VERSION "HNNBNNNYNNNNNNNNNNNNNNNNNNNNNNNNNNNNNNNNNN/4/%%%/4/'%**4NNN///"

NS_ :

BS_:

BU_: BAP_Tester BedienDisp_mi BedienDisp_vo_mi CDI ConMod_CD DashCAM Gateway_Max ICC_IO_Node LSH OCU RDK_RS3 Sound_MIB_ab_Gen3 STH ZR_MIB_EINSTIEG_ab_Gen3 ZR_MIB_OPTION_ab_Gen3 ZR_MIB_TOP_ab_Gen3

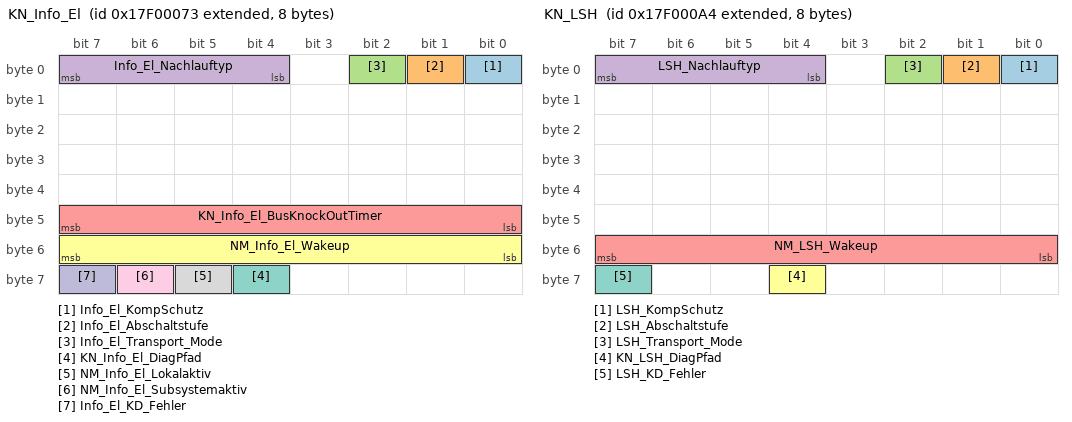
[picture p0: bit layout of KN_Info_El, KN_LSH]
BO_ 2549088371 KN_Info_El: 8 ICC_IO_Node
 SG_ Info_El_KompSchutz : 0|1@1+ (1.0,0.0) [0.0|1] ""  Vector__XXX
 SG_ Info_El_Abschaltstufe : 1|1@1+ (1.0,0.0) [0.0|1] ""  Vector__XXX
 SG_ Info_El_Transport_Mode : 2|1@1+ (1.0,0.0) [0.0|1] ""  Vector__XXX
 SG_ Info_El_Nachlauftyp : 4|4@1+ (1.0,0.0) [0.0|15] ""  Gateway_Max
 SG_ KN_Info_El_BusKnockOutTimer : 40|8@1+ (1,0) [0|254] "Unit_Minut"  Vector__XXX
 SG_ NM_Info_El_Wakeup : 48|8@1+ (1.0,0.0) [0.0|255] ""  Vector__XXX
 SG_ KN_Info_El_DiagPfad : 60|1@1+ (1.0,0.0) [0.0|1] ""  Gateway_Max
 SG_ NM_Info_El_Lokalaktiv : 61|1@1+ (1.0,0.0) [0.0|1] ""  Vector__XXX
 SG_ NM_Info_El_Subsystemaktiv : 62|1@1+ (1.0,0.0) [0.0|1] ""  Vector__XXX
 SG_ Info_El_KD_Fehler : 63|1@1+ (1.0,0.0) [0.0|1] ""  Gateway_Max

BO_ 2549088420 KN_LSH: 8 LSH
 SG_ LSH_KompSchutz : 0|1@1+ (1.0,0.0) [0.0|1] ""  Vector__XXX
 SG_ LSH_Abschaltstufe : 1|1@1+ (1.0,0.0) [0.0|1] ""  Vector__XXX
 SG_ LSH_Transport_Mode : 2|1@1+ (1.0,0.0) [0.0|1] ""  Vector__XXX
 SG_ LSH_Nachlauftyp : 4|4@1+ (1.0,0.0) [0.0|15] ""  Gateway_Max
 SG_ NM_LSH_Wakeup : 48|8@1+ (1.0,0.0) [0.0|255] ""  Vector__XXX
 SG_ KN_LSH_DiagPfad : 60|1@1+ (1.0,0.0) [0.0|1] ""  Gateway_Max
 SG_ LSH_KD_Fehler : 63|1@1+ (1.0,0.0) [0.0|1] ""  Gateway_Max

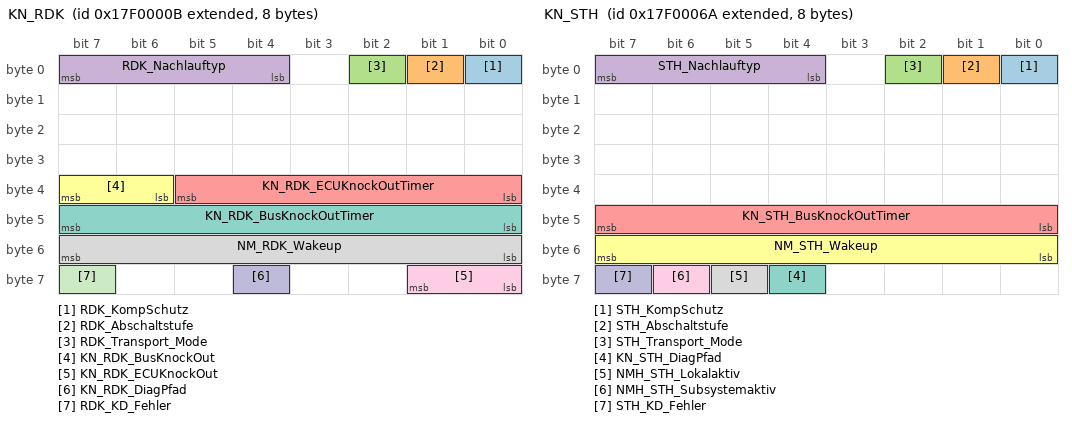
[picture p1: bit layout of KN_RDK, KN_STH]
BO_ 2549088267 KN_RDK: 8 RDK_RS3
 SG_ RDK_KompSchutz : 0|1@1+ (1.0,0.0) [0.0|1] ""  Vector__XXX
 SG_ RDK_Abschaltstufe : 1|1@1+ (1.0,0.0) [0.0|1] ""  Vector__XXX
 SG_ RDK_Transport_Mode : 2|1@1+ (1.0,0.0) [0.0|1] ""  Vector__XXX
 SG_ RDK_Nachlauftyp : 4|4@1+ (1.0,0.0) [0.0|15] ""  Gateway_Max
 SG_ KN_RDK_ECUKnockOutTimer : 32|6@1+ (1,0) [0|62] ""  Vector__XXX
 SG_ KN_RDK_BusKnockOut : 38|2@1+ (1.0,0.0) [0.0|3] ""  Vector__XXX
 SG_ KN_RDK_BusKnockOutTimer : 40|8@1+ (1,0) [0|254] ""  Vector__XXX
 SG_ NM_RDK_Wakeup : 48|8@1+ (1.0,0.0) [0.0|255] ""  Vector__XXX
 SG_ KN_RDK_ECUKnockOut : 56|2@1+ (1.0,0.0) [0.0|3] ""  Vector__XXX
 SG_ KN_RDK_DiagPfad : 60|1@1+ (1.0,0.0) [0.0|1] ""  Gateway_Max
 SG_ RDK_KD_Fehler : 63|1@1+ (1.0,0.0) [0.0|1] ""  Gateway_Max

BO_ 2549088362 KN_STH: 8 STH
 SG_ STH_KompSchutz : 0|1@1+ (1.0,0.0) [0.0|1] ""  Vector__XXX
 SG_ STH_Abschaltstufe : 1|1@1+ (1.0,0.0) [0.0|1] ""  Vector__XXX
 SG_ STH_Transport_Mode : 2|1@1+ (1.0,0.0) [0.0|1] ""  Vector__XXX
 SG_ STH_Nachlauftyp : 4|4@1+ (1.0,0.0) [0.0|15] ""  Gateway_Max
 SG_ KN_STH_BusKnockOutTimer : 40|8@1+ (1,0) [0|254] ""  Vector__XXX
 SG_ NM_STH_Wakeup : 48|8@1+ (1.0,0.0) [0.0|255] ""  Vector__XXX
 SG_ KN_STH_DiagPfad : 60|1@1+ (1.0,0.0) [0.0|1] ""  Gateway_Max
 SG_ NMH_STH_Lokalaktiv : 61|1@1+ (1.0,0.0) [0.0|1] ""  Vector__XXX
 SG_ NMH_STH_Subsystemaktiv : 62|1@1+ (1.0,0.0) [0.0|1] ""  Vector__XXX
 SG_ STH_KD_Fehler : 63|1@1+ (1.0,0.0) [0.0|1] ""  Gateway_Max

BO_ 779 Kombi_01: 8 Gateway_Max
 SG_ KBI_ABS_Lampe : 0|1@1+ (1.0,0.0) [0.0|1] ""  Vector__XXX
 SG_ KBI_ESP_Lampe : 1|1@1+ (1.0,0.0) [0.0|1] ""  Vector__XXX
 SG_ KBI_BKL_Lampe : 2|1@1+ (1.0,0.0) [0.0|1] ""  Vector__XXX
 SG_ KBI_Airbag_Lampe : 3|1@1+ (1.0,0.0) [0.0|1] ""  Vector__XXX
 SG_ KBI_SILA_gueltig : 4|1@1+ (1.0,0.0) [0.0|1] ""  Vector__XXX
 SG_ KBI_Lenkung_Lampe : 5|1@1+ (1,0) [0|1] ""  Vector__XXX
 SG_ KBI_Vorglueh_System_Lampe : 6|1@1+ (1.0,0.0) [0.0|1] ""  OCU
 SG_ KBI_NV_in_Anzeige : 7|1@1+ (1.0,0.0) [0.0|1] ""  Vector__XXX
 SG_ Kombi_01_BZ : 8|4@1+ (1,0) [0|15] ""  Vector__XXX
 SG_ KBI_Anzeigestatus_ACC : 12|1@1+ (1.0,0.0) [0.0|1] ""  OCU
 SG_ KBI_Anzeigestatus_GRA : 13|2@1+ (1.0,0.0) [0.0|3] ""  OCU
 SG_ KBI_Oeldruck_Schalter : 15|1@1+ (1.0,0.0) [0.0|1] ""  Vector__XXX
 SG_ KBI_Tankwarnung : 16|1@1+ (1.0,0.0) [0.0|1] ""  LSH,OCU,STH,ZR_MIB_EINSTIEG_ab_Gen3,ZR_MIB_OPTION_ab_Gen3,ZR_MIB_TOP_ab_Gen3
 SG_ KBI_MFA_v_Einheit_01 : 17|1@1+ (1.0,0.0) [0.0|1] ""  DashCAM,OCU,RDK_RS3,ZR_MIB_EINSTIEG_ab_Gen3,ZR_MIB_OPTION_ab_Gen3,ZR_MIB_TOP_ab_Gen3
 SG_ KBI_im_Stellgliedtest : 18|1@1+ (1.0,0.0) [0.0|1] ""  Vector__XXX
 SG_ KBI_Anzeigefehler_LDW : 19|2@1+ (1.0,0.0) [0.0|3] ""  Vector__XXX
 SG_ KBI_Tankwarnung_ungueltig : 21|1@1+ (1.0,0.0) [0.0|1] ""  OCU,ZR_MIB_TOP_ab_Gen3
 SG_ KBI_Oeldruckwarnung : 22|1@1+ (1.0,0.0) [0.0|1] ""  OCU
 SG_ KBI_Handbremse : 23|1@1+ (1.0,0.0) [0.0|1] ""  OCU,ZR_MIB_EINSTIEG_ab_Gen3,ZR_MIB_OPTION_ab_Gen3,ZR_MIB_TOP_ab_Gen3
 SG_ KBI_V_Digital : 24|9@1+ (1,0) [0|511] ""  DashCAM,OCU,RDK_RS3,ZR_MIB_EINSTIEG_ab_Gen3,ZR_MIB_OPTION_ab_Gen3,ZR_MIB_TOP_ab_Gen3
 SG_ KBI_PLA_in_Anzeige : 33|1@1+ (1.0,0.0) [0.0|1] ""  Vector__XXX
 SG_ KBI_Anzeigefehler_NV : 34|1@1+ (1.0,0.0) [0.0|1] ""  Vector__XXX
 SG_ KBI_Anzeigestatus_LIM : 35|2@1+ (1.0,0.0) [0.0|3] ""  OCU
 SG_ KBI_ARA_in_Anzeige : 37|1@1+ (1.0,0.0) [0.0|1] ""  Vector__XXX
 SG_ KBI_Taster_Lift : 38|1@1+ (1.0,0.0) [0.0|1] ""  Vector__XXX
 SG_ KBI_Taster_Fahrwerk : 39|1@1+ (1.0,0.0) [0.0|1] ""  Vector__XXX
 SG_ KBI_Audioabsenkung_MIB : 40|2@1+ (1.0,0.0) [0.0|3] ""  OCU
 SG_ KBI_Bestaetigung_ESP_Off : 42|2@1+ (1.0,0.0) [0.0|3] ""  Vector__XXX
 SG_ KBI_Anzeigestatus_RHP : 44|2@1+ (1.0,0.0) [0.0|3] ""  Vector__XXX
 SG_ KBI_angez_Geschw : 48|10@1+ (0.32,0) [0.00|325.12] "Unit_KiloMeterPerHour"  CDI,OCU,ZR_MIB_EINSTIEG_ab_Gen3,ZR_MIB_TOP_ab_Gen3
 SG_ KBI_Konsistenz_ACC : 59|1@1+ (1.0,0.0) [0.0|1] ""  Vector__XXX
 SG_ KBI_Fehler_Anzeige_ACC : 60|1@1+ (1.0,0.0) [0.0|1] ""  Vector__XXX
 SG_ KBI_Anzeigefehler_SWA : 61|2@1+ (1.0,0.0) [0.0|3] ""  Vector__XXX
 SG_ KBI_Systemstatus : 63|1@1+ (1.0,0.0) [0.0|1] ""  Vector__XXX

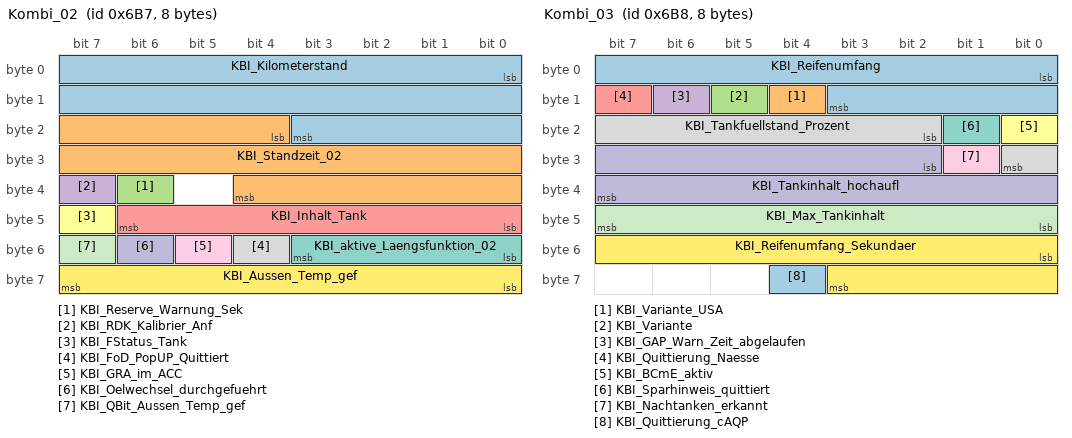
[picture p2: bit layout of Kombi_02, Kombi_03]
BO_ 1719 Kombi_02: 8 Gateway_Max
 SG_ KBI_Kilometerstand : 0|20@1+ (1,0) [0|1048573] "Unit_KiloMeter"  CDI,ConMod_CD,OCU
 SG_ KBI_Standzeit_02 : 20|17@1+ (1,0) [0|131068] "Unit_Secon"  OCU,ZR_MIB_EINSTIEG_ab_Gen3,ZR_MIB_TOP_ab_Gen3
 SG_ KBI_Reserve_Warnung_Sek : 38|1@1+ (1.0,0.0) [0.0|1] ""  ZR_MIB_EINSTIEG_ab_Gen3,ZR_MIB_OPTION_ab_Gen3,ZR_MIB_TOP_ab_Gen3
 SG_ KBI_RDK_Kalibrier_Anf : 39|1@1+ (1.0,0.0) [0.0|1] ""  RDK_RS3
 SG_ KBI_Inhalt_Tank : 40|7@1+ (1,0) [0|125] "Unit_Liter"  LSH,OCU,STH
 SG_ KBI_FStatus_Tank : 47|1@1+ (1.0,0.0) [0.0|1] ""  OCU,ZR_MIB_EINSTIEG_ab_Gen3,ZR_MIB_OPTION_ab_Gen3,ZR_MIB_TOP_ab_Gen3
 SG_ KBI_aktive_Laengsfunktion_02 : 48|4@1+ (1.0,0.0) [0.0|15] ""  Vector__XXX
 SG_ KBI_FoD_PopUP_Quittiert : 52|1@1+ (1.0,0.0) [0.0|1] ""  OCU
 SG_ KBI_GRA_im_ACC : 53|1@1+ (1.0,0.0) [0.0|1] ""  Vector__XXX
 SG_ KBI_Oelwechsel_durchgefuehrt : 54|1@1+ (1.0,0.0) [0.0|1] ""  Vector__XXX
 SG_ KBI_QBit_Aussen_Temp_gef : 55|1@1+ (1.0,0.0) [0.0|1] ""  LSH,OCU,RDK_RS3,ZR_MIB_EINSTIEG_ab_Gen3,ZR_MIB_OPTION_ab_Gen3
 SG_ KBI_Aussen_Temp_gef : 56|8@1+ (0.5,-50) [-50.0|75.0] "Unit_DegreCelsi"  LSH,OCU,RDK_RS3,STH,ZR_MIB_EINSTIEG_ab_Gen3,ZR_MIB_OPTION_ab_Gen3

BO_ 1720 Kombi_03: 8 Gateway_Max
 SG_ KBI_Reifenumfang : 0|12@1+ (1,0) [0|4095] "Unit_MilliMeter"  ZR_MIB_EINSTIEG_ab_Gen3,ZR_MIB_OPTION_ab_Gen3,ZR_MIB_TOP_ab_Gen3
 SG_ KBI_Variante_USA : 12|1@1+ (1.0,0.0) [0.0|1] ""  Vector__XXX
 SG_ KBI_Variante : 13|1@1+ (1.0,0.0) [0.0|1] ""  Vector__XXX
 SG_ KBI_GAP_Warn_Zeit_abgelaufen : 14|1@1+ (1.0,0.0) [0.0|1] ""  Vector__XXX
 SG_ KBI_Quittierung_Naesse : 15|1@1+ (1.0,0.0) [0.0|1] ""  Vector__XXX
 SG_ KBI_BCmE_aktiv : 16|1@1+ (1.0,0.0) [0.0|1] ""  Vector__XXX
 SG_ KBI_Sparhinweis_quittiert : 17|1@1+ (1.0,0.0) [0.0|1] ""  Vector__XXX
 SG_ KBI_Tankfuellstand_Prozent : 18|7@1+ (1,0) [0|100] "Unit_PerCent"  OCU
 SG_ KBI_Nachtanken_erkannt : 25|1@1+ (1.0,0.0) [0.0|1] ""  OCU,ZR_MIB_TOP_ab_Gen3
 SG_ KBI_Tankinhalt_hochaufl : 26|14@1+ (0.01,0) [0.00|163.81] "Unit_Liter"  OCU
 SG_ KBI_Max_Tankinhalt : 40|8@1+ (0.5,0) [0.0|126.5] ""  OCU
 SG_ KBI_Reifenumfang_Sekundaer : 48|12@1+ (1,0) [0|4095] "Unit_MilliMeter"  Vector__XXX
 SG_ KBI_Quittierung_cAQP : 60|1@1+ (1.0,0.0) [0.0|1] ""  Vector__XXX

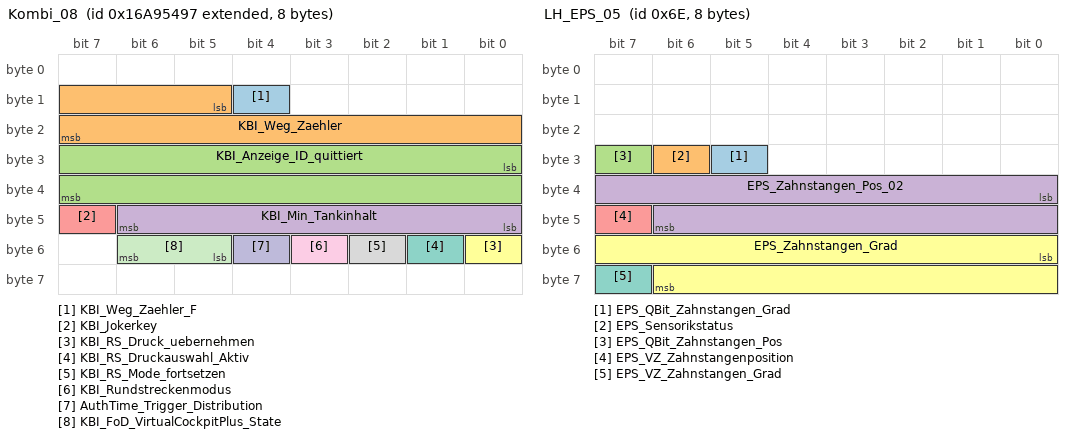
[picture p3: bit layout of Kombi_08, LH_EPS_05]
BO_ 2527679639 Kombi_08: 8 Gateway_Max
 SG_ KBI_Weg_Zaehler_F : 12|1@1+ (1.0,0.0) [0.0|1] ""  ZR_MIB_EINSTIEG_ab_Gen3,ZR_MIB_OPTION_ab_Gen3,ZR_MIB_TOP_ab_Gen3
 SG_ KBI_Weg_Zaehler : 13|11@1+ (1,0) [0|2047] "Unit_Meter"  ZR_MIB_EINSTIEG_ab_Gen3,ZR_MIB_OPTION_ab_Gen3,ZR_MIB_TOP_ab_Gen3
 SG_ KBI_Anzeige_ID_quittiert : 24|16@1+ (1,0) [1|65336] "Unit_None"  Vector__XXX
 SG_ KBI_Min_Tankinhalt : 40|7@1+ (0.1,0) [0.0|12.5] "Unit_Liter"  OCU
 SG_ KBI_Jokerkey : 47|1@1+ (1.0,0.0) [0.0|1] ""  Vector__XXX
 SG_ KBI_RS_Druck_uebernehmen : 48|1@1+ (1.0,0.0) [0.0|1] ""  Vector__XXX
 SG_ KBI_RS_Druckauswahl_Aktiv : 49|1@1+ (1.0,0.0) [0.0|1] ""  Vector__XXX
 SG_ KBI_RS_Mode_fortsetzen : 50|1@1+ (1.0,0.0) [0.0|1] ""  Vector__XXX
 SG_ KBI_Rundstreckenmodus : 51|1@1+ (1.0,0.0) [0.0|1] ""  Vector__XXX
 SG_ AuthTime_Trigger_Distribution : 52|1@1+ (1.0,0.0) [0.0|1] ""  ICC_IO_Node,OCU,ZR_MIB_EINSTIEG_ab_Gen3,ZR_MIB_OPTION_ab_Gen3,ZR_MIB_TOP_ab_Gen3
 SG_ KBI_FoD_VirtualCockpitPlus_State : 53|2@1+ (1.0,0.0) [0.0|3] ""  Vector__XXX

BO_ 2527679656 Kombi_23: 8 Gateway_Max
 SG_ KBI_StartupAnimation : 61|3@1+ (1.0,0.0) [0.0|7] ""  ZR_MIB_EINSTIEG_ab_Gen3

BO_ 2589283935 Kombi_ATM_01: 8 Gateway_Max
 SG_ KBI_View1 : 12|1@1+ (1.0,0.0) [0.0|1] ""  ZR_MIB_OPTION_ab_Gen3
 SG_ KBI_View2 : 13|1@1+ (1.0,0.0) [0.0|1] ""  ZR_MIB_OPTION_ab_Gen3
 SG_ KBI_View3 : 14|1@1+ (1.0,0.0) [0.0|1] ""  ZR_MIB_OPTION_ab_Gen3
 SG_ KBI_View4 : 15|1@1+ (1.0,0.0) [0.0|1] ""  ZR_MIB_OPTION_ab_Gen3
 SG_ KBI_View5 : 16|1@1+ (1.0,0.0) [0.0|1] ""  ZR_MIB_OPTION_ab_Gen3
 SG_ KBI_View6 : 17|1@1+ (1.0,0.0) [0.0|1] ""  ZR_MIB_OPTION_ab_Gen3
 SG_ KBI_View7 : 18|1@1+ (1.0,0.0) [0.0|1] ""  ZR_MIB_OPTION_ab_Gen3
 SG_ KBI_View8 : 19|1@1+ (1.0,0.0) [0.0|1] ""  ZR_MIB_OPTION_ab_Gen3
 SG_ KBI_View9 : 20|1@1+ (1.0,0.0) [0.0|1] ""  ZR_MIB_OPTION_ab_Gen3
 SG_ KBI_View10 : 21|1@1+ (1.0,0.0) [0.0|1] ""  ZR_MIB_OPTION_ab_Gen3
 SG_ KBI_View11 : 22|1@1+ (1.0,0.0) [0.0|1] ""  ZR_MIB_OPTION_ab_Gen3
 SG_ KBI_View12 : 23|1@1+ (1.0,0.0) [0.0|1] ""  ZR_MIB_OPTION_ab_Gen3
 SG_ KBI_View13 : 24|1@1+ (1.0,0.0) [0.0|1] ""  ZR_MIB_OPTION_ab_Gen3
 SG_ KBI_View14 : 25|1@1+ (1.0,0.0) [0.0|1] ""  ZR_MIB_OPTION_ab_Gen3
 SG_ KBI_View15 : 26|1@1+ (1.0,0.0) [0.0|1] ""  ZR_MIB_OPTION_ab_Gen3
 SG_ KBI_View16 : 27|1@1+ (1.0,0.0) [0.0|1] ""  ZR_MIB_OPTION_ab_Gen3
 SG_ KBI_View17 : 28|1@1+ (1.0,0.0) [0.0|1] ""  ZR_MIB_OPTION_ab_Gen3
 SG_ KBI_View18 : 29|1@1+ (1.0,0.0) [0.0|1] ""  ZR_MIB_OPTION_ab_Gen3
 SG_ KBI_View19 : 30|1@1+ (1.0,0.0) [0.0|1] ""  ZR_MIB_OPTION_ab_Gen3
 SG_ KBI_View20 : 31|1@1+ (1.0,0.0) [0.0|1] ""  ZR_MIB_OPTION_ab_Gen3
 SG_ KBI_View21 : 32|1@1+ (1.0,0.0) [0.0|1] ""  ZR_MIB_OPTION_ab_Gen3
 SG_ KBI_View22 : 33|1@1+ (1.0,0.0) [0.0|1] ""  ZR_MIB_OPTION_ab_Gen3
 SG_ KBI_View23 : 34|1@1+ (1.0,0.0) [0.0|1] ""  ZR_MIB_OPTION_ab_Gen3
 SG_ KBI_View24 : 35|1@1+ (1.0,0.0) [0.0|1] ""  ZR_MIB_OPTION_ab_Gen3
 SG_ KBI_Curr_View : 36|5@1+ (1.0,0.0) [0.0|31] ""  ZR_MIB_OPTION_ab_Gen3
 SG_ KBI_Sec_View_Status : 41|2@1+ (1.0,0.0) [0.0|3] ""  ZR_MIB_OPTION_ab_Gen3

BO_ 2550399240 KS_ICAS3Sys01_Req: 8 Gateway_Max
 SG_ KS_ICAS3Sys01_Req_Data : 0|64@1+ (1.0,0.0) [0.0|18446744073709551615] ""  ICC_IO_Node

BO_ 2550530312 KS_ICAS3Sys01_Resp: 8 ICC_IO_Node
 SG_ KS_ICAS3Sys01_Resp_Data : 0|64@1+ (1.0,0.0) [0.0|18446744073709551615] ""  Gateway_Max

BO_ 2549875059 KS_Info_El_Req: 8 Gateway_Max
 SG_ KS_Info_El_Req_Data : 0|64@1+ (1.0,0.0) [0.0|18446744073709551615] ""  ICC_IO_Node,ZR_MIB_EINSTIEG_ab_Gen3,ZR_MIB_OPTION_ab_Gen3,ZR_MIB_TOP_ab_Gen3

BO_ 2550006131 KS_Info_El_Resp: 8 ICC_IO_Node
 SG_ KS_Info_El_Resp_Data : 0|64@1+ (1.0,0.0) [0.0|18446744073709551615] ""  Gateway_Max

BO_ 2549899278 KS_SSN_ABT_1_Req: 8 Gateway_Max
 SG_ KS_SSN_ABT_1_Req_Data : 0|64@1+ (1.0,0.0) [0.0|18446744073709551615] ""  ICC_IO_Node,ZR_MIB_EINSTIEG_ab_Gen3,ZR_MIB_OPTION_ab_Gen3

BO_ 2550030350 KS_SSN_ABT_1_Resp: 8 ICC_IO_Node
 SG_ KS_SSN_ABT_1_Resp_Data : 0|64@1+ (1.0,0.0) [0.0|18446744073709551615] ""  Gateway_Max

BO_ 2549875053 KS_TV_Tuner_Req: 8 Gateway_Max
 SG_ KS_TV_Tuner_Req_Data : 0|64@1+ (1.0,0.0) [0.0|18446744073709551615] ""  ZR_MIB_TOP_ab_Gen3

BO_ 2550006125 KS_TV_Tuner_Resp: 8 ZR_MIB_TOP_ab_Gen3
 SG_ KS_TV_Tuner_Resp_Data : 0|64@1+ (1.0,0.0) [0.0|18446744073709551615] ""  Gateway_Max

BO_ 110 LH_EPS_05: 8 Gateway_Max
 SG_ EPS_QBit_Zahnstangen_Grad : 29|1@1+ (1.0,0.0) [0.0|1] ""  Vector__XXX
 SG_ EPS_Sensorikstatus : 30|1@1+ (1.0,0.0) [0.0|1] ""  ZR_MIB_OPTION_ab_Gen3
 SG_ EPS_QBit_Zahnstangen_Pos : 31|1@1+ (1.0,0.0) [0.0|1] ""  OCU,ZR_MIB_OPTION_ab_Gen3
 SG_ EPS_Zahnstangen_Pos_02 : 32|15@1+ (0.00306,0) [0.00000|100.00080] "Unit_MilliMeter"  OCU,ZR_MIB_OPTION_ab_Gen3
 SG_ EPS_VZ_Zahnstangenposition : 47|1@1+ (1.0,0.0) [0.0|1] ""  OCU,ZR_MIB_OPTION_ab_Gen3
 SG_ EPS_Zahnstangen_Grad : 48|15@1+ (0.0000078125,0) [0E-10|0.2559843750] "Unit_MeterPerSecon"  Vector__XXX
 SG_ EPS_VZ_Zahnstangen_Grad : 63|1@1+ (1.0,0.0) [0.0|1] ""  Vector__XXX

BO_ 981 Licht_Anf_01: 8 Gateway_Max
 SG_ Licht_Anf_01_CRC : 0|8@1+ (1,0) [0|255] ""  Vector__XXX
 SG_ Licht_Anf_01_BZ : 8|4@1+ (1,0) [0|15] ""  Vector__XXX
 SG_ BCM1_Kurvenlicht_links_Anf : 12|1@1+ (1.0,0.0) [0.0|1] ""  ZR_MIB_EINSTIEG_ab_Gen3,ZR_MIB_OPTION_ab_Gen3
 SG_ BCM1_Kurvenlicht_rechts_Anf : 13|1@1+ (1.0,0.0) [0.0|1] ""  ZR_MIB_EINSTIEG_ab_Gen3,ZR_MIB_OPTION_ab_Gen3
 SG_ BCM1_Standlicht_Anf : 14|1@1+ (1.0,0.0) [0.0|1] ""  OCU,ZR_MIB_EINSTIEG_ab_Gen3,ZR_MIB_OPTION_ab_Gen3
 SG_ BCM1_Abblendlicht_Anf : 15|1@1+ (1.0,0.0) [0.0|1] ""  OCU,ZR_MIB_EINSTIEG_ab_Gen3,ZR_MIB_OPTION_ab_Gen3
 SG_ BCM1_Fernlicht_Anf : 16|1@1+ (1.0,0.0) [0.0|1] ""  OCU,ZR_MIB_EINSTIEG_ab_Gen3,ZR_MIB_OPTION_ab_Gen3
 SG_ BCM1_Nebellicht_Anf : 17|1@1+ (1.0,0.0) [0.0|1] ""  OCU,ZR_MIB_EINSTIEG_ab_Gen3,ZR_MIB_OPTION_ab_Gen3
 SG_ BCM1_Parklicht_li_Anf : 18|1@1+ (1.0,0.0) [0.0|1] ""  OCU,ZR_MIB_EINSTIEG_ab_Gen3,ZR_MIB_OPTION_ab_Gen3
 SG_ BCM1_Parklicht_re_Anf : 19|1@1+ (1.0,0.0) [0.0|1] ""  OCU,ZR_MIB_EINSTIEG_ab_Gen3,ZR_MIB_OPTION_ab_Gen3
 SG_ BCM1_Nebelschluss_Ahg_Anf : 20|1@1+ (1.0,0.0) [0.0|1] ""  Vector__XXX
 SG_ BCM1_Nebelschluss_Fzg_Anf : 21|1@1+ (1.0,0.0) [0.0|1] ""  OCU,ZR_MIB_EINSTIEG_ab_Gen3,ZR_MIB_OPTION_ab_Gen3
 SG_ BCM1_Schlusslicht_Anf : 22|1@1+ (1.0,0.0) [0.0|1] ""  Vector__XXX
 SG_ BCM_Rueckfahrlicht_Anf : 23|1@1+ (1.0,0.0) [0.0|1] ""  OCU,ZR_MIB_EINSTIEG_ab_Gen3,ZR_MIB_OPTION_ab_Gen3,ZR_MIB_TOP_ab_Gen3
 SG_ BCM1_Signaturlicht_Anf : 24|1@1+ (1.0,0.0) [0.0|1] ""  Vector__XXX
 SG_ BCM1_Umfeldleuchten_Anf : 25|1@1+ (1.0,0.0) [0.0|1] ""  Vector__XXX
 SG_ BCM1_Tagfahrlicht_Anf : 26|1@1+ (1.0,0.0) [0.0|1] ""  ZR_MIB_EINSTIEG_ab_Gen3,ZR_MIB_OPTION_ab_Gen3,ZR_MIB_TOP_ab_Gen3
 SG_ BCM1_Regenlicht_Anf : 27|1@1+ (1.0,0.0) [0.0|1] ""  Vector__XXX
 SG_ BCM1_Autobahnlicht_Anf : 28|1@1+ (1.0,0.0) [0.0|1] ""  Vector__XXX
 SG_ BCM1_Touristen_Licht_Anf : 29|1@1+ (1.0,0.0) [0.0|1] ""  Vector__XXX
 SG_ BCM1_CH_aktiv : 30|1@1+ (1.0,0.0) [0.0|1] ""  Vector__XXX
 SG_ BCM1_LH_aktiv : 31|1@1+ (1.0,0.0) [0.0|1] ""  Vector__XXX
 SG_ BCM1_Gleitende_Leuchtw_Anf : 32|1@1+ (1.0,0.0) [0.0|1] ""  Vector__XXX
 SG_ BCM1_GLW_Fernlicht_Anf : 33|1@1+ (1.0,0.0) [0.0|1] ""  ZR_MIB_EINSTIEG_ab_Gen3,ZR_MIB_OPTION_ab_Gen3
 SG_ BCM1_Adaptive_Lichtvert_Anf : 34|1@1+ (1.0,0.0) [0.0|1] ""  Vector__XXX
 SG_ BCM1_Animationssperrung : 39|1@1+ (1.0,0.0) [0.0|1] ""  Vector__XXX
 SG_ BCM1_CH_LH_aktiv : 40|1@1+ (1.0,0.0) [0.0|1] ""  Vector__XXX
 SG_ BCM1_Allwetterlicht_Anf : 41|1@1+ (1.0,0.0) [0.0|1] ""  Vector__XXX
 SG_ TFL_Matrix_Variante01_Anf : 42|1@1+ (1.0,0.0) [0.0|1] ""  Vector__XXX
 SG_ TFL_Matrix_Variante02_Anf : 43|1@1+ (1.0,0.0) [0.0|1] ""  Vector__XXX
 SG_ TFL_Matrix_Variante03_Anf : 44|1@1+ (1.0,0.0) [0.0|1] ""  Vector__XXX
 SG_ TFL_Matrix_Variante04_Anf : 45|1@1+ (1.0,0.0) [0.0|1] ""  Vector__XXX

BO_ 982 Licht_hinten_01: 8 Gateway_Max
 SG_ Licht_hinten_01_BZ : 0|4@1+ (1,0) [0|15] ""  Vector__XXX
 SG_ BCM2_Bremsl_durch_ECD_invers : 4|1@1+ (1.0,0.0) [0.0|1] ""  Vector__XXX
 SG_ BCM2_Bremsl_durch_ECD : 5|1@1+ (1.0,0.0) [0.0|1] ""  Vector__XXX
 SG_ LH_Aussenlicht_def : 7|1@1+ (1.0,0.0) [0.0|1] ""  Vector__XXX
 SG_ LH_Standlicht_H_aktiv : 8|1@1+ (1.0,0.0) [0.0|1] ""  Vector__XXX
 SG_ LH_Parklicht_HL_aktiv : 9|1@1+ (1.0,0.0) [0.0|1] ""  Vector__XXX
 SG_ LH_Parklicht_HR_aktiv : 10|1@1+ (1.0,0.0) [0.0|1] ""  Vector__XXX
 SG_ LH_Bremslicht_H_aktiv : 11|1@1+ (1.0,0.0) [0.0|1] ""  OCU,ZR_MIB_EINSTIEG_ab_Gen3,ZR_MIB_OPTION_ab_Gen3
 SG_ LH_Nebelschluss_aktiv : 12|1@1+ (1.0,0.0) [0.0|1] ""  Vector__XXX
 SG_ LH_Rueckfahrlicht_aktiv : 13|1@1+ (1.0,0.0) [0.0|1] ""  Vector__XXX
 SG_ LH_Blinker_HL_akt : 14|1@1+ (1.0,0.0) [0.0|1] ""  Vector__XXX
 SG_ LH_Blinker_HR_akt : 15|1@1+ (1.0,0.0) [0.0|1] ""  Vector__XXX
 SG_ LH_Blinker_li_def : 16|1@1+ (1.0,0.0) [0.0|1] ""  OCU
 SG_ LH_Bremsl_li_def : 17|1@1+ (1.0,0.0) [0.0|1] ""  OCU
 SG_ LH_Schlusslicht_li_def : 18|1@1+ (1.0,0.0) [0.0|1] ""  OCU
 SG_ LH_Rueckf_li_def : 19|1@1+ (1.0,0.0) [0.0|1] ""  OCU
 SG_ LH_Nebel_li_def : 20|1@1+ (1.0,0.0) [0.0|1] ""  OCU
 SG_ LH_Schluss_Brems_Nebel_li_def : 21|1@1+ (1.0,0.0) [0.0|1] ""  OCU
 SG_ LH_Schluss_Brems_Nebel_re_def : 22|1@1+ (1.0,0.0) [0.0|1] ""  OCU
 SG_ LH_Zusatzschlussl_def : 23|1@1+ (1.0,0.0) [0.0|1] ""  OCU
 SG_ LH_Schluss_Brems_li_def : 24|1@1+ (1.0,0.0) [0.0|1] ""  OCU
 SG_ LH_Schluss_Nebel_li_def : 25|1@1+ (1.0,0.0) [0.0|1] ""  OCU
 SG_ LH_SL_BRL_BLK_li_def : 26|1@1+ (1.0,0.0) [0.0|1] ""  OCU
 SG_ LH_Brems_Blk_li_def : 27|1@1+ (1.0,0.0) [0.0|1] ""  OCU
 SG_ LH_Diag_Status_re_def : 28|1@1+ (1.0,0.0) [0.0|1] ""  OCU
 SG_ LH_Diag_Status_li_def : 29|1@1+ (1.0,0.0) [0.0|1] ""  OCU
 SG_ LH_Diag_LED_li_def : 30|1@1+ (1.0,0.0) [0.0|1] ""  OCU
 SG_ LH_Diag_LED_re_def : 31|1@1+ (1.0,0.0) [0.0|1] ""  OCU
 SG_ LH_Blinker_re_def : 32|1@1+ (1.0,0.0) [0.0|1] ""  OCU
 SG_ LH_Bremsl_re_def : 33|1@1+ (1.0,0.0) [0.0|1] ""  OCU
 SG_ LH_Schlusslicht_re_def : 34|1@1+ (1.0,0.0) [0.0|1] ""  OCU
 SG_ LH_Rueckf_re_def : 35|1@1+ (1.0,0.0) [0.0|1] ""  OCU
 SG_ LH_Nebel_re_def : 36|1@1+ (1.0,0.0) [0.0|1] ""  OCU
 SG_ LH_Schluss_Brems_re_def : 40|1@1+ (1.0,0.0) [0.0|1] ""  OCU
 SG_ LH_Schluss_Nebel_re_def : 41|1@1+ (1.0,0.0) [0.0|1] ""  OCU
 SG_ LH_SL_BRL_BLK_re_def : 42|1@1+ (1.0,0.0) [0.0|1] ""  OCU
 SG_ LH_Brems_Blk_re_def : 43|1@1+ (1.0,0.0) [0.0|1] ""  OCU
 SG_ LH_Kennzl_def : 48|1@1+ (1.0,0.0) [0.0|1] ""  OCU
 SG_ LH_3_Bremsl_def : 49|1@1+ (1.0,0.0) [0.0|1] ""  OCU
 SG_ LH_Nebel_mi_def : 50|1@1+ (1.0,0.0) [0.0|1] ""  OCU
 SG_ LH_Rueckf_mi_def : 51|1@1+ (1.0,0.0) [0.0|1] ""  Vector__XXX
 SG_ LH_Bremsl_li_ges_def : 54|1@1+ (1.0,0.0) [0.0|1] ""  OCU
 SG_ LH_Bremsl_re_ges_def : 55|1@1+ (1.0,0.0) [0.0|1] ""  OCU

BO_ 1624 Licht_vorne_01: 8 Gateway_Max
 SG_ Licht_Vorne_01_CRC : 0|8@1+ (1,0) [0|255] ""  Vector__XXX
 SG_ Licht_Vorne_01_BZ : 8|4@1+ (1,0) [0|15] ""  Vector__XXX
 SG_ LV_Standlicht_Anzeige : 12|1@1+ (1.0,0.0) [0.0|1] ""  OCU
 SG_ LV_Abblendlicht_Anzeige : 13|1@1+ (1.0,0.0) [0.0|1] ""  DashCAM,OCU,ZR_MIB_EINSTIEG_ab_Gen3,ZR_MIB_OPTION_ab_Gen3,ZR_MIB_TOP_ab_Gen3
 SG_ LV_Fernlicht_Anzeige : 14|1@1+ (1.0,0.0) [0.0|1] ""  DashCAM,OCU,ZR_MIB_EINSTIEG_ab_Gen3,ZR_MIB_OPTION_ab_Gen3,ZR_MIB_TOP_ab_Gen3
 SG_ LV_Nebellicht_Anzeige : 15|1@1+ (1.0,0.0) [0.0|1] ""  OCU,ZR_MIB_EINSTIEG_ab_Gen3,ZR_MIB_OPTION_ab_Gen3,ZR_MIB_TOP_ab_Gen3
 SG_ LV_Nebelschlusslicht_Anzeige : 16|1@1+ (1.0,0.0) [0.0|1] ""  OCU,ZR_MIB_EINSTIEG_ab_Gen3,ZR_MIB_OPTION_ab_Gen3,ZR_MIB_TOP_ab_Gen3
 SG_ LV_Tagfahrlicht_Anzeige : 17|1@1+ (1.0,0.0) [0.0|1] ""  OCU
 SG_ LV_AFL_aktiv_Anzeige : 18|1@1+ (1.0,0.0) [0.0|1] ""  OCU
 SG_ LV_AFL_defekt : 19|1@1+ (1.0,0.0) [0.0|1] ""  OCU
 SG_ LV_Blinker_li_def : 20|1@1+ (1.0,0.0) [0.0|1] ""  OCU
 SG_ LV_Standlicht_li_def : 21|1@1+ (1.0,0.0) [0.0|1] ""  OCU
 SG_ LV_Abblendlicht_li_def : 22|1@1+ (1.0,0.0) [0.0|1] ""  DashCAM,OCU
 SG_ LV_Fernlicht_li_def : 23|1@1+ (1.0,0.0) [0.0|1] ""  OCU
 SG_ LV_Nebellicht_li_def : 24|1@1+ (1.0,0.0) [0.0|1] ""  OCU
 SG_ LV_Blk_li_Seite_def : 25|1@1+ (1.0,0.0) [0.0|1] ""  OCU
 SG_ LV_Tagfahrlicht_li_def : 26|1@1+ (1.0,0.0) [0.0|1] ""  OCU
 SG_ LV_FLA_aktiv_Anzeige : 27|1@1+ (1.0,0.0) [0.0|1] ""  OCU
 SG_ LV_FLA_defekt : 28|1@1+ (1.0,0.0) [0.0|1] ""  OCU
 SG_ LV_FLA_Sensor_blockiert : 29|1@1+ (1.0,0.0) [0.0|1] ""  Vector__XXX
 SG_ LV_Blinker_re_def : 30|1@1+ (1.0,0.0) [0.0|1] ""  OCU
 SG_ LV_Standlicht_re_def : 31|1@1+ (1.0,0.0) [0.0|1] ""  OCU
 SG_ LV_Abblendlicht_re_def : 32|1@1+ (1.0,0.0) [0.0|1] ""  DashCAM,OCU
 SG_ LV_Fernlicht_re_def : 33|1@1+ (1.0,0.0) [0.0|1] ""  OCU
 SG_ LV_Nebellicht_re_def : 34|1@1+ (1.0,0.0) [0.0|1] ""  OCU
 SG_ LV_Blk_re_Seite_def : 35|1@1+ (1.0,0.0) [0.0|1] ""  OCU
 SG_ LV_Tagfahrlicht_re_def : 36|1@1+ (1.0,0.0) [0.0|1] ""  OCU
 SG_ LV_Aussenlicht_def : 37|1@1+ (1.0,0.0) [0.0|1] ""  OCU
 SG_ LV_Abblendlicht_TFL_li_def : 38|1@1+ (1.0,0.0) [0.0|1] ""  OCU
 SG_ LV_Nebellicht_TFL_li_def : 39|1@1+ (1.0,0.0) [0.0|1] ""  OCU
 SG_ LV_Standlicht_TFL_li_def : 40|1@1+ (1.0,0.0) [0.0|1] ""  OCU
 SG_ LV_Abblend_Fernlicht_li_def : 41|1@1+ (1.0,0.0) [0.0|1] ""  OCU
 SG_ LV_Abblendlicht_TFL_re_def : 42|1@1+ (1.0,0.0) [0.0|1] ""  OCU
 SG_ LV_Nebellicht_TFL_re_def : 43|1@1+ (1.0,0.0) [0.0|1] ""  OCU
 SG_ LV_Standlicht_TFL_re_def : 44|1@1+ (1.0,0.0) [0.0|1] ""  OCU
 SG_ LV_Abblend_Fernlicht_re_def : 45|1@1+ (1.0,0.0) [0.0|1] ""  OCU
 SG_ LV_Abbiegelicht_li_def : 46|1@1+ (1.0,0.0) [0.0|1] ""  OCU
 SG_ LV_Abbiegelicht_re_def : 47|1@1+ (1.0,0.0) [0.0|1] ""  OCU
 SG_ BCM1_Linksverkehr : 48|1@1+ (1.0,0.0) [0.0|1] ""  Vector__XXX
 SG_ BCM1_Licht_Dunkelheit_aktiv : 49|1@1+ (1.0,0.0) [0.0|1] ""  CDI
 SG_ LV_LED_Scheinwerfer_li_def : 50|1@1+ (1.0,0.0) [0.0|1] ""  OCU
 SG_ LV_LED_Scheinwerfer_re_def : 51|1@1+ (1.0,0.0) [0.0|1] ""  OCU
 SG_ LV_Blinker_VL_aktiv : 52|1@1+ (1.0,0.0) [0.0|1] ""  Vector__XXX
 SG_ LV_Blinker_VR_aktiv : 53|1@1+ (1.0,0.0) [0.0|1] ""  Vector__XXX
 SG_ LV_MXB_Status_Anzeige : 54|2@1+ (1.0,0.0) [0.0|3] ""  Vector__XXX

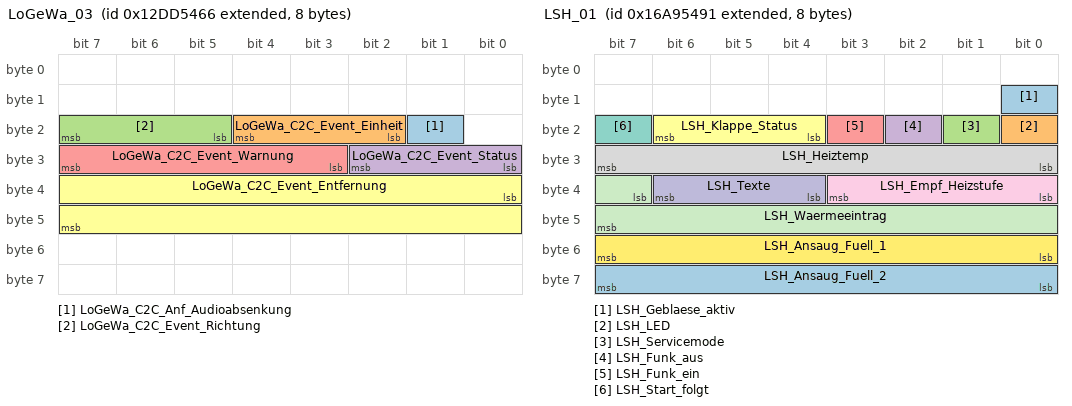
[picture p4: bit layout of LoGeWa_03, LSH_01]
BO_ 2463978598 LoGeWa_03: 8 Gateway_Max
 SG_ LoGeWa_C2C_Anf_Audioabsenkung : 17|1@1+ (1.0,0.0) [0.0|1] ""  Vector__XXX
 SG_ LoGeWa_C2C_Event_Einheit : 18|3@1+ (1.0,0.0) [0.0|7] ""  OCU
 SG_ LoGeWa_C2C_Event_Richtung : 21|3@1+ (1.0,0.0) [0.0|7] ""  OCU
 SG_ LoGeWa_C2C_Event_Status : 24|3@1+ (1.0,0.0) [0.0|7] ""  OCU
 SG_ LoGeWa_C2C_Event_Warnung : 27|5@1+ (1.0,0.0) [0.0|31] ""  OCU
 SG_ LoGeWa_C2C_Event_Entfernung : 32|16@1+ (0.1,0) [0.0|6553.4] "Unit_None"  OCU

BO_ 2527679633 LSH_01: 8 Gateway_Max
 SG_ LSH_Geblaese_aktiv : 8|1@1+ (1.0,0.0) [0.0|1] ""  Gateway_Max,OCU
 SG_ LSH_LED : 16|1@1+ (1.0,0.0) [0.0|1] ""  Gateway_Max,OCU,STH
 SG_ LSH_Servicemode : 17|1@1+ (1.0,0.0) [0.0|1] ""  Gateway_Max,OCU
 SG_ LSH_Funk_aus : 18|1@1+ (1.0,0.0) [0.0|1] ""  Gateway_Max,OCU
 SG_ LSH_Funk_ein : 19|1@1+ (1.0,0.0) [0.0|1] ""  Gateway_Max,OCU
 SG_ LSH_Klappe_Status : 20|3@1+ (1.0,0.0) [0.0|7] ""  Gateway_Max,OCU
 SG_ LSH_Start_folgt : 23|1@1+ (1.0,0.0) [0.0|1] ""  Gateway_Max,OCU
 SG_ LSH_Heiztemp : 24|8@1+ (2,-40) [-40|360] "Unit_DegreCelsi"  Gateway_Max,OCU
 SG_ LSH_Empf_Heizstufe : 32|4@1+ (1.0,0.0) [0.0|15] ""  Gateway_Max,OCU
 SG_ LSH_Texte : 36|3@1+ (1.0,0.0) [0.0|7] ""  Gateway_Max,OCU
 SG_ LSH_Waermeeintrag : 39|9@1+ (5,0) [0|2500] "Unit_Minut"  Gateway_Max,OCU
 SG_ LSH_Ansaug_Fuell_1 : 48|8@1+ (0.75,-40) [-40.00|142.25] "Unit_DegreCelsi"  Gateway_Max,OCU
 SG_ LSH_Ansaug_Fuell_2 : 56|8@1+ (0.75,-40) [-40.00|142.25] "Unit_DegreCelsi"  Gateway_Max,OCU

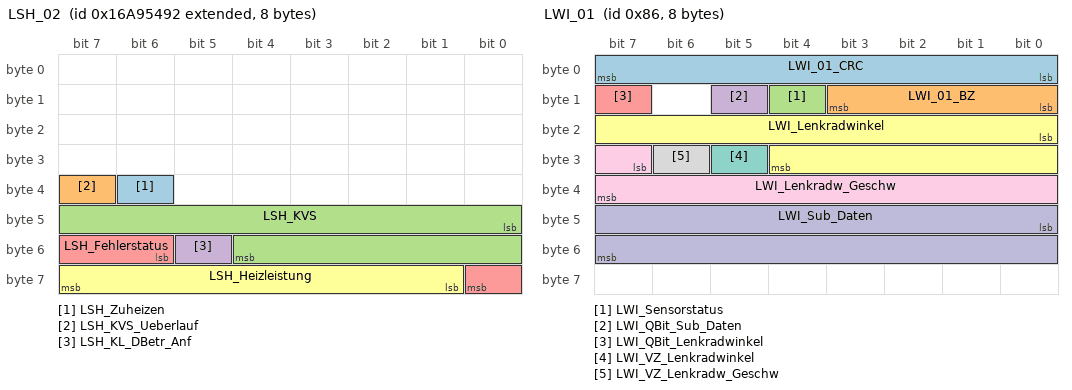
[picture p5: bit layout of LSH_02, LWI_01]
BO_ 2527679634 LSH_02: 8 Gateway_Max
 SG_ LSH_Zuheizen : 38|1@1+ (1.0,0.0) [0.0|1] ""  Gateway_Max
 SG_ LSH_KVS_Ueberlauf : 39|1@1+ (1.0,0.0) [0.0|1] ""  Gateway_Max,OCU
 SG_ LSH_KVS : 40|13@1+ (1,0) [0|8191] "Unit_MilliLiter"  Gateway_Max,OCU
 SG_ LSH_KL_DBetr_Anf : 53|1@1+ (1.0,0.0) [0.0|1] ""  Gateway_Max
 SG_ LSH_Fehlerstatus : 54|3@1+ (1.0,0.0) [0.0|7] ""  Gateway_Max,STH
 SG_ LSH_Heizleistung : 57|7@1+ (1,0) [0|100] "Unit_PerCent"  Gateway_Max

BO_ 134 LWI_01: 8 Gateway_Max
 SG_ LWI_01_CRC : 0|8@1+ (1,0) [0|255] ""  Vector__XXX
 SG_ LWI_01_BZ : 8|4@1+ (1,0) [0|15] ""  Vector__XXX
 SG_ LWI_Sensorstatus : 12|1@1+ (1.0,0.0) [0.0|1] ""  OCU
 SG_ LWI_QBit_Sub_Daten : 13|1@1+ (1.0,0.0) [0.0|1] ""  Vector__XXX
 SG_ LWI_QBit_Lenkradwinkel : 15|1@1+ (1.0,0.0) [0.0|1] ""  OCU
 SG_ LWI_Lenkradwinkel : 16|13@1+ (0.1,0) [0.0|800.0] "Unit_DegreOfArc"  OCU
 SG_ LWI_VZ_Lenkradwinkel : 29|1@1+ (1.0,0.0) [0.0|1] ""  OCU
 SG_ LWI_VZ_Lenkradw_Geschw : 30|1@1+ (1.0,0.0) [0.0|1] ""  OCU
 SG_ LWI_Lenkradw_Geschw : 31|9@1+ (5,0) [0|2500] "Unit_DegreOfArcPerSecon"  OCU
 SG_ LWI_Sub_Daten : 40|16@1+ (1,0) [0|65535] ""  Vector__XXX

BO_ 1153 MainUnit_01: 8 Gateway_Max
 SG_ ZR_LoGeWa_Event_Kombiwarnung : 0|4@1+ (1.0,0.0) [0.0|15] ""  Gateway_Max
 SG_ Nav_FoD_Status : 4|3@1+ (1.0,0.0) [0.0|7] ""  Gateway_Max,OCU
 SG_ MIB_ASW_Diagnose : 7|1@1+ (1.0,0.0) [0.0|1] ""  Gateway_Max,OCU
 SG_ ZR_Lichter_Tag : 8|1@1+ (1.0,0.0) [0.0|1] ""  Gateway_Max
 SG_ MIB_Tongenerator_PH_verfuegbar : 9|3@1+ (1.0,0.0) [0.0|7] ""  Gateway_Max,OCU
 SG_ MMI_Counter_Bedienevent : 12|4@1+ (1.0,0.0) [0.0|15] ""  Gateway_Max
 SG_ DSSS_Warning : 16|5@1+ (1.0,0.0) [0.0|31] ""  Gateway_Max
 SG_ ZR_Kindersicherung_RSE : 21|1@1+ (1.0,0.0) [0.0|1] ""  Gateway_Max
 SG_ ZR_RSE_aktivieren : 22|1@1+ (1.0,0.0) [0.0|1] ""  Gateway_Max
 SG_ MMI_SDS_aktiv : 23|1@1+ (1.0,0.0) [0.0|1] ""  Gateway_Max
 SG_ MU_SecondDisplay : 24|3@1+ (1.0,0.0) [0.0|7] ""  Gateway_Max
 SG_ MMI_Telefon_aktiv : 27|1@1+ (1.0,0.0) [0.0|1] ""  Gateway_Max
 SG_ MMI_Gurt_Mic_ref : 28|1@1+ (1.0,0.0) [0.0|1] ""  Gateway_Max
 SG_ ZR_Sta_Inszenierung : 29|2@1+ (1.0,0.0) [0.0|3] ""  Gateway_Max
 SG_ ZR_AppConnect_Zustand : 31|1@1+ (1.0,0.0) [0.0|1] ""  Gateway_Max
 SG_ MU_Update_Time : 32|8@1+ (0.1,0) [0.0|25.5] "Unit_Hours"  Gateway_Max
 SG_ ZR_Parken_Sondermodus : 48|4@1+ (1.0,0.0) [0.0|15] ""  Gateway_Max

BO_ 1178 Mem_FS_01: 8 Gateway_Max
 SG_ Mem_FS_01_MQB_CRC : 0|8@1+ (1,0) [0|255] ""  Vector__XXX
 SG_ Mem_FS_01_MQB_BZ : 8|4@1+ (1,0) [0|15] ""  Vector__XXX
 SG_ FS_Fond_Bed_enable : 12|1@1+ (1.0,0.0) [0.0|1] ""  Vector__XXX
 SG_ FS_Lehne_nicht_verriegelt : 13|1@1+ (1.0,0.0) [0.0|1] ""  Vector__XXX
 SG_ FS_Spezialposition_anfahren : 14|1@1+ (1.0,0.0) [0.0|1] ""  Vector__XXX
 SG_ FS_Gurtbringer_Sperre : 15|1@1+ (1.0,0.0) [0.0|1] ""  Vector__XXX
 SG_ FS_BFS_Sitzsym_Anfahrt : 16|1@1+ (1.0,0.0) [0.0|1] ""  Vector__XXX
 SG_ FS_Sitzfahrt_aktiv : 17|1@1+ (1.0,0.0) [0.0|1] ""  OCU
 SG_ FS_SLV_aktiv : 18|1@1+ (1.0,0.0) [0.0|1] ""  Vector__XXX
 SG_ FS_SHV_aktiv : 19|1@1+ (1.0,0.0) [0.0|1] ""  Vector__XXX
 SG_ FS_LNV_aktiv : 20|1@1+ (1.0,0.0) [0.0|1] ""  Vector__XXX
 SG_ FS_SNV_aktiv : 21|1@1+ (1.0,0.0) [0.0|1] ""  Vector__XXX
 SG_ FS_KSV_aktiv : 22|1@1+ (1.0,0.0) [0.0|1] ""  Vector__XXX
 SG_ FS_LKV_aktiv : 23|1@1+ (1.0,0.0) [0.0|1] ""  Vector__XXX
 SG_ FS_STV_aktiv : 24|1@1+ (1.0,0.0) [0.0|1] ""  Vector__XXX
 SG_ FS_LHV_aktiv : 25|1@1+ (1.0,0.0) [0.0|1] ""  Vector__XXX
 SG_ FS_LWV_aktiv : 26|1@1+ (1.0,0.0) [0.0|1] ""  Vector__XXX
 SG_ FS_GHV_aktiv : 27|1@1+ (1.0,0.0) [0.0|1] ""  Vector__XXX
 SG_ FS_BFS_KSS_Anfahrt : 28|1@1+ (1.0,0.0) [0.0|1] ""  Vector__XXX
 SG_ FS_MMB_lokal_Stop : 29|1@1+ (1.0,0.0) [0.0|1] ""  Vector__XXX
 SG_ FS_MMB_storage : 32|4@1+ (1.0,0.0) [0.0|15] ""  Vector__XXX
 SG_ FS_MMB_tipp : 36|1@1+ (1.0,0.0) [0.0|1] ""  Vector__XXX
 SG_ FS_MMB_tast : 37|1@1+ (1.0,0.0) [0.0|1] ""  Vector__XXX
 SG_ FS_MMB_store_LED_on : 38|1@1+ (1.0,0.0) [0.0|1] ""  Vector__XXX
 SG_ FS_MMB_storage_beep : 39|1@1+ (1.0,0.0) [0.0|1] ""  Vector__XXX
 SG_ FS_MMB_store : 40|1@1+ (1.0,0.0) [0.0|1] ""  Vector__XXX
 SG_ FS_MMB_glob_stop : 41|1@1+ (1.0,0.0) [0.0|1] ""  Vector__XXX
 SG_ FS_EE_Fond_FS_enable : 42|1@1+ (1.0,0.0) [0.0|1] ""  Vector__XXX
 SG_ FS_EE_Fond_BFS_enable : 43|1@1+ (1.0,0.0) [0.0|1] ""  Vector__XXX
 SG_ FS_BFS_Fond_Verst_enable : 44|1@1+ (1.0,0.0) [0.0|1] ""  Vector__XXX
 SG_ FS_EE_BFS_enable : 45|1@1+ (1.0,0.0) [0.0|1] ""  Vector__XXX

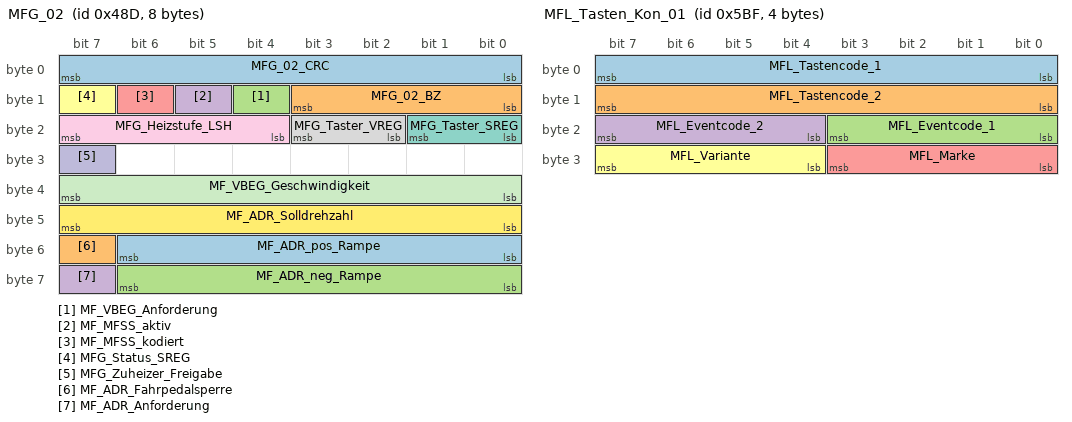
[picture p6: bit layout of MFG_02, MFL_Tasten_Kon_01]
BO_ 1165 MFG_02: 8 Gateway_Max
 SG_ MFG_02_CRC : 0|8@1+ (1,0) [0|255] ""  Vector__XXX
 SG_ MFG_02_BZ : 8|4@1+ (1,0) [0|15] ""  Vector__XXX
 SG_ MF_VBEG_Anforderung : 12|1@1+ (1.0,0.0) [0.0|1] ""  Vector__XXX
 SG_ MF_MFSS_aktiv : 13|1@1+ (1.0,0.0) [0.0|1] ""  Vector__XXX
 SG_ MF_MFSS_kodiert : 14|1@1+ (1.0,0.0) [0.0|1] ""  Vector__XXX
 SG_ MFG_Status_SREG : 15|1@1+ (1.0,0.0) [0.0|1] ""  Vector__XXX
 SG_ MFG_Taster_SREG : 16|2@1+ (1.0,0.0) [0.0|3] ""  Vector__XXX
 SG_ MFG_Taster_VREG : 18|2@1+ (1.0,0.0) [0.0|3] ""  Vector__XXX
 SG_ MFG_Heizstufe_LSH : 20|4@1+ (1.0,0.0) [0.0|15] ""  LSH
 SG_ MFG_Zuheizer_Freigabe : 31|1@1+ (1.0,0.0) [0.0|1] ""  LSH
 SG_ MF_VBEG_Geschwindigkeit : 32|8@1+ (1,0) [0|254] "Unit_KiloMeterPerHour"  Vector__XXX
 SG_ MF_ADR_Solldrehzahl : 40|8@1+ (20,0) [0|5100] "Unit_MinutInver"  Vector__XXX
 SG_ MF_ADR_pos_Rampe : 48|7@1+ (10,0) [0|1000] ""  Vector__XXX
 SG_ MF_ADR_Fahrpedalsperre : 55|1@1+ (1.0,0.0) [0.0|1] ""  Vector__XXX
 SG_ MF_ADR_neg_Rampe : 56|7@1+ (10,0) [0|1000] ""  Vector__XXX
 SG_ MF_ADR_Anforderung : 63|1@1+ (1.0,0.0) [0.0|1] ""  Vector__XXX

BO_ 1164 MFG_03: 8 Gateway_Max
 SG_ MFG_Infotainment_Autark : 12|1@1+ (1.0,0.0) [0.0|1] ""  ICC_IO_Node,ZR_MIB_EINSTIEG_ab_Gen3,ZR_MIB_OPTION_ab_Gen3
 SG_ MFG_Klappe_Status : 13|3@1+ (1.0,0.0) [0.0|7] ""  LSH
 SG_ MFG_LSH_DBetr_Ein : 16|1@1+ (1.0,0.0) [0.0|1] ""  LSH
 SG_ MFG_LSH_Betriebsdauer : 17|7@1+ (1,0) [0|120] "Unit_Minut"  LSH
 SG_ MFG_LSH_DBetr_Bestaet : 24|1@1+ (1.0,0.0) [0.0|1] ""  LSH
 SG_ MFG_LSH_Ansteuerung : 25|2@1+ (1.0,0.0) [0.0|3] ""  LSH
 SG_ MF_Radiomute : 27|1@1+ (1.0,0.0) [0.0|1] ""  ZR_MIB_EINSTIEG_ab_Gen3,ZR_MIB_OPTION_ab_Gen3,ZR_MIB_TOP_ab_Gen3
 SG_ MF_Relais_2_Batterie : 28|1@1+ (1.0,0.0) [0.0|1] ""  Vector__XXX
 SG_ MF_Batteriediagnose : 29|3@1+ (1.0,0.0) [0.0|7] ""  Vector__XXX
 SG_ MFG_AppConnect_Anf : 32|2@1+ (1.0,0.0) [0.0|3] ""  ZR_MIB_EINSTIEG_ab_Gen3
 SG_ MF_Lampenausfall : 34|1@1+ (1.0,0.0) [0.0|1] ""  Vector__XXX
 SG_ MF_Blinker_L_Sta : 35|1@1+ (1.0,0.0) [0.0|1] ""  Vector__XXX
 SG_ MF_Blinker_R_Sta : 36|1@1+ (1.0,0.0) [0.0|1] ""  Vector__XXX
 SG_ MF_interm_Nebelscheinwerfer : 37|1@1+ (1.0,0.0) [0.0|1] ""  Vector__XXX
 SG_ MF_Generatordiagnose : 38|2@1+ (1.0,0.0) [0.0|3] ""  Vector__XXX
 SG_ MF_Heck_entriegeln : 40|1@1+ (1.0,0.0) [0.0|1] ""  Vector__XXX
 SG_ MF_Heck_verriegeln : 41|1@1+ (1.0,0.0) [0.0|1] ""  Vector__XXX
 SG_ MF_2BatSOCzugering : 42|1@1+ (1.0,0.0) [0.0|1] ""  Vector__XXX
 SG_ MF_Fahrerhinweis : 43|3@1+ (1.0,0.0) [0.0|7] ""  Vector__XXX
 SG_ MF_ZV_Unlock : 46|1@1+ (1.0,0.0) [0.0|1] ""  Vector__XXX
 SG_ MF_Tuerverriegelung_hinten : 47|1@1+ (1.0,0.0) [0.0|1] ""  Vector__XXX
 SG_ MF_2BattAb : 48|1@1+ (1.0,0.0) [0.0|1] ""  LSH
 SG_ MF_2BattHlkAnf : 49|1@1+ (1.0,0.0) [0.0|1] ""  Vector__XXX
 SG_ MF_2BattLadWarn : 50|1@1+ (1.0,0.0) [0.0|1] ""  Vector__XXX
 SG_ MF_2BattLlaAnf : 51|1@1+ (1.0,0.0) [0.0|1] ""  Vector__XXX
 SG_ MF_2BattSpannungsAnf : 52|2@1+ (1.0,0.0) [0.0|3] ""  Vector__XXX
 SG_ MF_NotStartAktiv : 54|1@1+ (1.0,0.0) [0.0|1] ""  Vector__XXX
 SG_ MF_ExterneLadungWarn : 55|1@1+ (1.0,0.0) [0.0|1] ""  Vector__XXX
 SG_ MF_LSH_Zielzeit : 56|4@1+ (10,0) [0|130] "Unit_Minut"  Vector__XXX
 SG_ MF_LSH_Abschaltstufe : 60|3@1+ (1.0,0.0) [0.0|7] ""  LSH
 SG_ MF_LSH_Einschaltverbot : 63|1@1+ (1.0,0.0) [0.0|1] ""  LSH

BO_ 1471 MFL_Tasten_Kon_01: 4 Gateway_Max
 SG_ MFL_Tastencode_1 : 0|8@1+ (1.0,0.0) [0.0|255] ""  ICC_IO_Node,OCU,ZR_MIB_EINSTIEG_ab_Gen3,ZR_MIB_OPTION_ab_Gen3,ZR_MIB_TOP_ab_Gen3
 SG_ MFL_Tastencode_2 : 8|8@1+ (1.0,0.0) [0.0|255] ""  ICC_IO_Node,OCU,ZR_MIB_EINSTIEG_ab_Gen3,ZR_MIB_OPTION_ab_Gen3,ZR_MIB_TOP_ab_Gen3
 SG_ MFL_Eventcode_1 : 16|4@1+ (1.0,0.0) [0.0|15] ""  ICC_IO_Node,OCU,ZR_MIB_EINSTIEG_ab_Gen3,ZR_MIB_OPTION_ab_Gen3,ZR_MIB_TOP_ab_Gen3
 SG_ MFL_Eventcode_2 : 20|4@1+ (1.0,0.0) [0.0|15] ""  ICC_IO_Node,OCU,ZR_MIB_EINSTIEG_ab_Gen3,ZR_MIB_OPTION_ab_Gen3,ZR_MIB_TOP_ab_Gen3
 SG_ MFL_Marke : 24|4@1+ (1.0,0.0) [0.0|15] ""  ICC_IO_Node,OCU,ZR_MIB_EINSTIEG_ab_Gen3,ZR_MIB_OPTION_ab_Gen3,ZR_MIB_TOP_ab_Gen3
 SG_ MFL_Variante : 28|4@1+ (1,0) [0|15] ""  ICC_IO_Node,OCU,ZR_MIB_EINSTIEG_ab_Gen3,ZR_MIB_OPTION_ab_Gen3,ZR_MIB_TOP_ab_Gen3

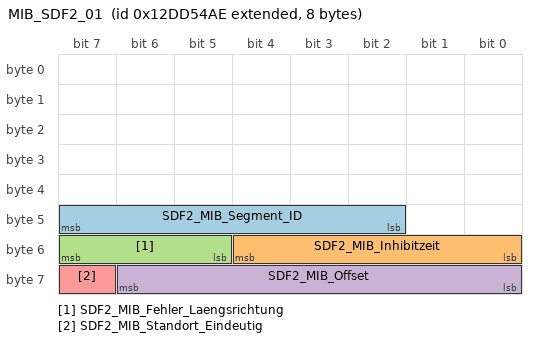
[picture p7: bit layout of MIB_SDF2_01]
BO_ 2463978670 MIB_SDF2_01: 8 ZR_MIB_TOP_ab_Gen3
 SG_ SDF2_MIB_Segment_ID : 42|6@1+ (1,0) [2|63] ""  Vector__XXX
 SG_ SDF2_MIB_Inhibitzeit : 48|5@1+ (10,0) [0|310] "Unit_MilliSecon"  Vector__XXX
 SG_ SDF2_MIB_Fehler_Laengsrichtung : 53|3@1+ (1.0,0.0) [0.0|7] ""  Vector__XXX
 SG_ SDF2_MIB_Offset : 56|7@1+ (2,0) [0|254] "Unit_Meter"  Vector__XXX
 SG_ SDF2_MIB_Standort_Eindeutig : 63|1@1+ (1.0,0.0) [0.0|1] ""  Vector__XXX

BO_TX_BU_ 2549088371 :ICC_IO_Node,ZR_MIB_EINSTIEG_ab_Gen3,ZR_MIB_OPTION_ab_Gen3,ZR_MIB_TOP_ab_Gen3;
BO_TX_BU_ 2550006131 :ICC_IO_Node,ZR_MIB_EINSTIEG_ab_Gen3,ZR_MIB_OPTION_ab_Gen3,ZR_MIB_TOP_ab_Gen3;
BO_TX_BU_ 2550030350 :ICC_IO_Node,ZR_MIB_EINSTIEG_ab_Gen3,ZR_MIB_OPTION_ab_Gen3;
BO_TX_BU_ 2527679633 :Gateway_Max,LSH;
BO_TX_BU_ 2527679634 :Gateway_Max,LSH;
BO_TX_BU_ 1153 :Gateway_Max,ZR_MIB_EINSTIEG_ab_Gen3,ZR_MIB_OPTION_ab_Gen3,ZR_MIB_TOP_ab_Gen3;
CM_ BO_ 779 "MQB";
CM_ BO_ 982 "MQB";
CM_ BO_ 2527679633 "Botschaft mit Signalen der Luftzusatzheizung";
CM_ BO_ 134 "ab MQB mit CRC in Byte 1";
CM_ BO_ 1178 "ab MQB 7.2";

CM_ SG_ 2549088371 Info_El_Abschaltstufe "Funktionseinschränkung aufgrund aktiver Abschaltstufe";
CM_ SG_ 2549088371 Info_El_KD_Fehler "Bei gesetztem Bit ist mindestens ein Kundendienstfehler eingetragen";
CM_ SG_ 2549088371 Info_El_KompSchutz "Funktionseinschränkung aufgrund Komponentenschutz aktiv";
CM_ SG_ 2549088371 Info_El_Nachlauftyp "Abgebildet wird die von der Hardware vorgegebene Möglichkeit, die Kommunikation nach Klemme 15 = AUS aufrecht zu erhalten. Es wird ein Init-Wert gesendet.";
CM_ SG_ 2549088371 Info_El_Transport_Mode "Funktionseinschränkung aufgrund aktivem Transport Mode und/oder Transport Schutz";
CM_ SG_ 2549088371 KN_Info_El_BusKnockOutTimer "Ausgabe des BusKnockOut-Timer";
CM_ SG_ 2549088371 KN_Info_El_DiagPfad "Kennzeichnung der Diagnosefähigkeit des BusInterfaces eines Steuergerätes (Knoten)
Umfang LAH 80127

Bei Nutzung des Signal explizit pro angebundenem BusInterface zu setzen:
MQB AB auf I-CAN = 0 (aktiv)
MQB A0 auf K-CAN = 0 (aktiv)
MQB2020 auf I-CAN";
CM_ SG_ 2549088371 NM_Info_El_Lokalaktiv "Zeigt an ob das SG nach Klemme15 AUS und nach entsprechender MAX Aktivzeit noch aktiv war.";
CM_ SG_ 2549088371 NM_Info_El_Subsystemaktiv "Zeigt an ob ein Subsystem des SGs nach Klemme15 AUS und nach entsprechender MAX Aktivzeit noch aktiv war";
CM_ SG_ 2549088371 NM_Info_El_Wakeup "enthält die Weckursache; stehen mehrere Weckursachen parallel an, dann muss der kleinste Wert übertragen werden";

CM_ SG_ 2549088420 KN_LSH_DiagPfad "Kennzeichnung der Diagnosefähigkeit des BusInterfaces eines Steuergerätes (Knoten)
Umfang LAH 80127

Bei Nutzung des Signal explizit pro angebundenem BusInterface zu setzen:
MQB auf I-CAN = 0 (aktiv)
MQB2020 auf I-CAN = 0 (aktiv)
MQBw_Baseline auf I";
CM_ SG_ 2549088420 LSH_Abschaltstufe "Funktionseinschränkung aufgrund aktiver Abschaltstufe";
CM_ SG_ 2549088420 LSH_KD_Fehler "Status Kundendienst-Fehlerspeicher";
CM_ SG_ 2549088420 LSH_KompSchutz "Funktionseinschränkung aufgrund Komponentenschutz aktiv";
CM_ SG_ 2549088420 LSH_Nachlauftyp "Abgebildet wird die von der Hardware vorgegebene Möglichkeit, die Kommunikation nach Klemme 15 = AUS aufrecht zu erhalten. Es wird ein Init-Wert gesendet.
0 = Kommunikation nur bei KL15=EIN (kein Nachlauf, nicht weckfähig)
1 = Kommunikation nach KL15=AU";
CM_ SG_ 2549088420 LSH_Transport_Mode "Funktionseinschränkung aufgrund aktivem Transport Mode und/oder Transport Schutz";
CM_ SG_ 2549088420 NM_LSH_Wakeup "enthält die Weckursache; stehen mehrere Weckursachen parallel an, dann muss der kleinste Wert übertragen werden";

CM_ SG_ 2549088267 KN_RDK_BusKnockOut "Ausgabe des BusKnockout-Status";
CM_ SG_ 2549088267 KN_RDK_BusKnockOutTimer "Ausgabe des BusKnockOut-Timer";
CM_ SG_ 2549088267 KN_RDK_DiagPfad "Kennzeichnung der Diagnosefähigkeit des BusInterfaces eines Steuergerätes (Knoten)
Umfang LAH 80127

Bei Nutzung des Signal explizit pro angebundenem BusInterface zu setzen:
MLBevo auf E-CAN = 0 (aktiv)
MQB auf E-CAN = 0 (aktiv)
MQB2020 auf I-CAN = ";
CM_ SG_ 2549088267 KN_RDK_ECUKnockOut "Ausgabe des ECUKnockout-Status";
CM_ SG_ 2549088267 KN_RDK_ECUKnockOutTimer "Ausgabe des ECUKnockOut-Timer";
CM_ SG_ 2549088267 NM_RDK_Wakeup "enthält die Weckursache; stehen mehrere Weckursachen parallel an, dann muss der kleinste Wert übertragen werden";
CM_ SG_ 2549088267 RDK_Abschaltstufe "Funktionseinschränkung aufgrund aktiver Abschaltstufe";
CM_ SG_ 2549088267 RDK_KD_Fehler "Bei gesetztem Bit ist mindestens ein Kundendienstfehler eingetragen";
CM_ SG_ 2549088267 RDK_KompSchutz "Funktionseinschränkung aufgrund Komponentenschutz aktiv";
CM_ SG_ 2549088267 RDK_Nachlauftyp "Abgebildet wird die von der Hardware vorgegebene Möglichkeit, die Kommunikation nach Klemme 15 = AUS aufrecht zu erhalten. Es wird ein Init-Wert gesendet.";
CM_ SG_ 2549088267 RDK_Transport_Mode "Funktionseinschränkung aufgrund aktivem Transport Mode und/oder Transport Schutz";

CM_ SG_ 2549088362 KN_STH_BusKnockOutTimer "Ausgabe des BusKnockOut-Timer";
CM_ SG_ 2549088362 KN_STH_DiagPfad "Kennzeichnung der Diagnosefähigkeit des BusInterfaces eines Steuergerätes (Knoten)
Umfang LAH 80127

Bei Nutzung des Signal explizit pro angebundenem BusInterface zu setzen:
MLBevo auf E-CAN = 0 (aktiv)
MQB auf I-CAN = 0 (aktiv)
MQB2020 auf I-CAN = ";
CM_ SG_ 2549088362 NM_STH_Wakeup "enthält die Weckursache; stehen mehrere Weckursachen parallel an, dann muss der kleinste Wert übertragen werden";
CM_ SG_ 2549088362 NMH_STH_Lokalaktiv "Zeigt an ob das SG nach Klemme15 AUS und nach entsprechender MAX Aktivzeit noch aktiv war";
CM_ SG_ 2549088362 NMH_STH_Subsystemaktiv "Zeigt an ob ein Subsystem des SGs nach Klemme15 AUS und nach entsprechender MAX Aktivzeit noch aktiv war";
CM_ SG_ 2549088362 STH_Abschaltstufe "Funktionseinschränkung aufgrund aktiver Abschaltstufe";
CM_ SG_ 2549088362 STH_KD_Fehler "Bei gesetztem Bit ist mindestens ein Kundendienstfehler eingetragen";
CM_ SG_ 2549088362 STH_KompSchutz "Funktionseinschränkung aufgrund Komponentenschutz aktiv";
CM_ SG_ 2549088362 STH_Nachlauftyp "Abgebildet wird die von der Hardware vorgegebene Möglichkeit, die Kommunikation nach Klemme 15 = AUS aufrecht zu erhalten. Es wird ein Init-Wert gesendet.";
CM_ SG_ 2549088362 STH_Transport_Mode "Funktionseinschränkung aufgrund aktivem Transport Mode und/oder Transport Schutz";

CM_ SG_ 779 KBI_ABS_Lampe "ABS-Sicherheits-Lampe wurde eingeschaltet.";
CM_ SG_ 779 KBI_Airbag_Lampe "Airbag Sicherheits-Lampe wurde eingeschaltet ";
CM_ SG_ 779 KBI_angez_Geschw "Im Tacho angezeigte Geschwindigkeit inklusive der Voreilung

";
CM_ SG_ 779 KBI_Anzeigefehler_NV "Über dieses Signal teilt das Kombiinstrument dem Nightvision-Steuergerät mit, dass ein Fehler vom Kombiinstrument diagnostiziert wurde, der zur Abschaltung der Nightvision-Funktion führen muss.";
CM_ SG_ 779 KBI_Anzeigefehler_SWA "Signal bezieht sich nur auf die SWA-Lampe, Vorhalt für Kombis mit SWA-Lampe. ";
CM_ SG_ 779 KBI_Anzeigestatus_ACC "Status der ACC-Anzeige im nicht permanenten Displaybereich";
CM_ SG_ 779 KBI_Anzeigestatus_GRA "Anzeigestatus der GRA High Wunschgeschwindigkeitsanzeige im Kombiinstrument.
Bei VW bedeutet 'nicht vorhanden' GRA-low fähig (LED immer verbaut).
0 = nicht vorhanden
1 = Wunschgeschwindigkeits-Anzeigemöglichkeit vorhanden
2 = reserviert
3 = Fehler (B";
CM_ SG_ 779 KBI_Anzeigestatus_LIM "Anzeigestatus der Speedlimiter Wunschgeschwindigkeitsanzeige im Kombiinstrument (permanenter Anzeigebereich)
0 = nicht vorhanden
1 = Wunschgeschwindigkeits-Anzeigemöglichkeit vorhanden
2 = reserviert
3 = Fehler (Botschaftsüberwachung, Timeout, Akustik";
CM_ SG_ 779 KBI_Anzeigestatus_RHP "Anzeigestatus des roten RHP-Symbols.";
CM_ SG_ 779 KBI_ARA_in_Anzeige "Anzeige von ARA im Kombi aktiv";
CM_ SG_ 779 KBI_Audioabsenkung_MIB "Anforderung der Audioabsenkung im MIB";
CM_ SG_ 779 KBI_Bestaetigung_ESP_Off "ESP Off Bestätigung vom Kombi ans ESC";
CM_ SG_ 779 KBI_BKL_Lampe "Sicherheits-Lampe Bremskontrolle wurde eingeschaltet;
";
CM_ SG_ 779 KBI_ESP_Lampe "ESP-Sicherheits-Lampe wurde eingeschaltet ";
CM_ SG_ 779 KBI_Fehler_Anzeige_ACC "Rückmeldung an ACC, dass mindestens eine der ACC-relevanten Anzeigen -rote Fahrerübernahme, Mitteldisplay, Gong - fehlerhaft sind.";
CM_ SG_ 779 KBI_Handbremse "Handbremsen-Information vom Kombi.
Das Signal bezieht sich ausschließlich auf den Zustand der konventionellen Handbremse.";
CM_ SG_ 779 KBI_im_Stellgliedtest "Kombi im Stellgliedtest, Signal muss eingelesen werden, um Fehlfunktion aufgrund der Bewegung der Stellglieder (Drehzahlmesser, Tacho) des Kombis zu verhindern";
CM_ SG_ 779 KBI_Konsistenz_ACC "Rückmeldung an ACC, dass die Botschaften zur Ansteuerung von Anzeigen nicht bzw. nicht konsistent empfangen wurden (Timeout-, BZ-, CHK- und DLC-Fehler)                                                                                                        ";
CM_ SG_ 779 KBI_Lenkung_Lampe "Sicherheits-Lampe der Lenkung (Lenkhilfe EPS, Audi-Dynamic-Steering ...) wurde eingeschaltet.

0x0 = Lenkungs-Lampe aus
0x1 = Lenkungs-Lampe ein";
CM_ SG_ 779 KBI_MFA_v_Einheit_01 "Einheit der Geschwindigkeit, die vom Fahrer im Car-Menü gewählt wurde. Veränderliche Grösse, im Gegensatz zur Einheit des Tachokranzes.";
CM_ SG_ 779 KBI_NV_in_Anzeige "Das Bit gibt dem NV die Information, ob NV-Bild im Kombi in der Anzeige ist. (Information ist notwendig um Kontrasverstellungen nur dann zuzulassen, wenn der Fahrer das Feedback über das  Kombidisplay bekommt.)";
CM_ SG_ 779 KBI_Oeldruck_Schalter "Das Signal bildet den Status des Öldrucks über den am Kombi angeschlossenen Öldruckschalter ab.";
CM_ SG_ 779 KBI_Oeldruckwarnung "Öldruckwarnung im Kombi aktiv";
CM_ SG_ 779 KBI_PLA_in_Anzeige "Das Signal wird als aktive Rückmeldung genutzt, ob die Info des PLA im Kombi angezeigt wird. Wenn nach Anforderung des Displays das Signal zweimal auf 0 ist, wird der Parkvorgang abgebrochen.
Ein Kombi, dass PLA Anzeige nicht unterstützt, schickt dauerha";
CM_ SG_ 779 KBI_SILA_gueltig "Rückmeldeinformation (Bit 1-6) ist gültig";
CM_ SG_ 779 KBI_Systemstatus "Signalisiert erkannte FuSi-relevante Fehler im Kombi
(keinen Ausfall der Akustik oder des Displays)";
CM_ SG_ 779 KBI_Tankwarnung "Fahrer wird gewarnt, dass er den Reservebereich erreicht hat. Fzg.spezifische Warnschwelle";
CM_ SG_ 779 KBI_Tankwarnung_ungueltig "Validiert den Inhalt des Signales KBI_Tankwarnung";
CM_ SG_ 779 KBI_Taster_Fahrwerk "Betätigung Taster 'Fahrwerk' im Kombi";
CM_ SG_ 779 KBI_Taster_Lift "Betätigung Taster 'Lift' im Kombi J1 zur Verarbeitung im Porsche EFP Steuergerät";
CM_ SG_ 779 KBI_V_Digital "Ausgabe der im Kombi angezeigten digitalen Geschwindigkeit.

Einheit ist im KBI_MFA_v_Einheit_01 definiert";
CM_ SG_ 779 KBI_Vorglueh_System_Lampe "Rückmeldung der Vorglühlampe bzw. Motor Systemlampe (MO_Systemlampe) an den Motor (bei Diesel und Otto!). Hardwaremässig gleiche LED im Kombi (EPC- oder Glühwendel), Unterscheidung nur über Ziffernblatt.";

CM_ SG_ 1719 KBI_aktive_Laengsfunktion_02 "Auswahl, der vom Fahrer gewünschten Laengsregelfunktion";
CM_ SG_ 1719 KBI_FoD_PopUP_Quittiert "Angezeigte FoD-Warnung im Kombi wurde vom Fahrer quittiert; 
Signal wird für die Dauer von 2 Sekunden gesendet";
CM_ SG_ 1719 KBI_FStatus_Tank "Signal wird gesetzt:

a) Während der Fehlerentprellzeit (20 s Entprellung)

b) Bei erkanntem Fehler wird der Tankinhalt während der laufenden KL15-Phase über den 
    Verbrauch zurückgerechnet. In dieser Zeit ist das Bit ebenfalls gesetzt. Nach einem";
CM_ SG_ 1719 KBI_GRA_im_ACC "Gibt den vom Fahrer ausgewählten Modus (ACC oder GRA_im_ACC) an.";
CM_ SG_ 1719 KBI_Inhalt_Tank "Restmenge 2 bzw. 2,5l nicht auflösbar

";
CM_ SG_ 1719 KBI_Kilometerstand "Fehler wird ausgegeben, falls Kilometerstand nicht restaurierbar
";
CM_ SG_ 1719 KBI_Oelwechsel_durchgefuehrt "Nach einen Ölwechsel (Service) ist die Ethanol Warmfahrwarnung zu unterdrücken.";
CM_ SG_ 1719 KBI_QBit_Aussen_Temp_gef "0x0 = gültiger Wert
0x1 = Ersatz-, Init- oder Fehlerwert";
CM_ SG_ 1719 KBI_RDK_Kalibrier_Anf "Bei gesetztem Bit soll die RDK die aktuellen Istdrücke zu Solldrücken übernehmen (nur bei Nichtverbau einer Headunit erforderlich).";
CM_ SG_ 1719 KBI_Reserve_Warnung_Sek "Signalisiert die Reservewarnung für die Energiespeicher CNG, LPG, HV-Batterie.
Fahrer wird gewarnt, dass er den Reservebereich erreicht hat. Fzg.spezifische Warnschwelle.";
CM_ SG_ 1719 KBI_Standzeit_02 "Zähler welcher die Standzeit des Motors wiedergibt.
Das Signal beschreibt den Anteil der Motor-Standzeit zwischen Zündung aus und nächstem Motorstart.";

CM_ SG_ 1720 KBI_BCmE_aktiv "Anzeige BCmE aktiv (BCmE-Screen oder Einsparhinweis in der Anzeige)";
CM_ SG_ 1720 KBI_GAP_Warn_Zeit_abgelaufen "Die Zeit, z.B. 1460 Tage, bis zur finalen Warnstufe der Gasanlagenprüfung wurde berechnet. Berechnung erfolgt auf Basis der aktuellen Uhrzeit mit einem Tageszähler. Keine Berechnung des Zählers bei Kl.30 AUS.";
CM_ SG_ 1720 KBI_Max_Tankinhalt "Mitteilung des maximalen Tankinhalts an das Reichweitenmodul";
CM_ SG_ 1720 KBI_Nachtanken_erkannt "Statusinformation Nachtankmodus";
CM_ SG_ 1720 KBI_Quittierung_cAQP "Quittierungsbestätigung vom Fahrer für Funktion cAQP";
CM_ SG_ 1720 KBI_Quittierung_Naesse "Quittierungsbestätigung vom Fahrer";
CM_ SG_ 1720 KBI_Reifenumfang "Mittlerer Radumfang aus der K-Zahl gerechnet in Millimeter.  Byte 2 Bit 5,4 reserviert, Byte 2 Bit 3..0 und Byte 1 Bit 7..0; Wertebereich 0..4096 mm
";
CM_ SG_ 1720 KBI_Reifenumfang_Sekundaer "Fahrzeuge mit unterschiedlichen Reifenumfängen Vorderachse / Hinterachse:

Primärachse: KBI_Reifenumfang
Sekundärachse: KBI_Reifenumfang_Sekundaer
";
CM_ SG_ 1720 KBI_Sparhinweis_quittiert "angezeigter Sparhinweis ist quittiert. Signal wird nach zwei Sendebotschaften wieder auf '0' gesetzt.";
CM_ SG_ 1720 KBI_Tankfuellstand_Prozent "Tankfüllstand in %";
CM_ SG_ 1720 KBI_Tankinhalt_hochaufl "angezeigter Tankinhalt hochauflösend zur Restreichweitenberechnung";
CM_ SG_ 1720 KBI_Variante "Zeigt an ob es sich um ein konventionelles Zeiger-Kombiinstrument handelt oder um eine Volldisplay-Kombiinstrument";
CM_ SG_ 1720 KBI_Variante_USA "In diesem Signal wird die HW-Variante des Kombis ausgegeben, ACC plausibilisiert auf dieses Signal hin seine US-Codierung";

CM_ SG_ 2527679639 AuthTime_Trigger_Distribution "Funktion Authentische Zeit-Verteilung.Broadcast- Triggersignal für Bekanntgabe an alle Clients, dass ein neuer Zeitstempel im Zeitmaster vorliegt.";
CM_ SG_ 2527679639 KBI_Anzeige_ID_quittiert "Inforrmation über die vom Fahrer quittierte Anzeige";
CM_ SG_ 2527679639 KBI_FoD_VirtualCockpitPlus_State "Informs if the function on demand feature 'Virtual Cockpit Plus' is locked or not.";
CM_ SG_ 2527679639 KBI_Jokerkey "Betaetigung KBI Jokertaste";
CM_ SG_ 2527679639 KBI_Min_Tankinhalt "Tankanzeigeleerwert für Reichweitenberechnung, kein reales Kraftstoffvolumen";
CM_ SG_ 2527679639 KBI_RS_Druck_uebernehmen "Druck für Rundstreckenmodus übernehmen";
CM_ SG_ 2527679639 KBI_RS_Druckauswahl_Aktiv "Menue Druckauswahl aktiv";
CM_ SG_ 2527679639 KBI_RS_Mode_fortsetzen "Kombi fordert Fortsetzung des Rundstreckenmodus";
CM_ SG_ 2527679639 KBI_Rundstreckenmodus "Rundstreckenmodus Anforderung";
CM_ SG_ 2527679639 KBI_Weg_Zaehler "Inkrementaler Zähler des Kombis

PAG-Plattform:
Sendeart: Cyclic
Zykluszeit: 100ms

MLBevo_Konzern:
Sendeart: OnChange
Zykluszeit: 1000ms
Inhibitzeit: 100ms
";
CM_ SG_ 2527679639 KBI_Weg_Zaehler_F "Fehlerbit für den Inkrementalzähler Weg

PAG-Plattform:
Sendeart: Cyclic
Zykluszeit: 100ms

MLBevo_Konzern:
Sendeart: OnChange
Zykluszeit: 1000ms
Inhibitzeit: 100ms";

CM_ SG_ 2527679656 KBI_StartupAnimation "Synchronisierung der StartupAnimation zwischen Kombi und MMI.";

CM_ SG_ 2589283935 KBI_Curr_View "Aktueller auf dem Kombiinstrument dargestellter View";
CM_ SG_ 2589283935 KBI_Sec_View_Status "Anzeigezustand der Nebenanzeigen im Kombiinstrument";
CM_ SG_ 2589283935 KBI_View1 "Dieser View wird vom Kombiinstrument unterstützt";
CM_ SG_ 2589283935 KBI_View10 "Dieser View wird vom Kombiinstrument unterstützt";
CM_ SG_ 2589283935 KBI_View11 "Dieser View wird vom Kombiinstrument unterstützt";
CM_ SG_ 2589283935 KBI_View12 "Dieser View wird vom Kombiinstrument unterstützt";
CM_ SG_ 2589283935 KBI_View13 "Dieser View wird vom Kombiinstrument unterstützt";
CM_ SG_ 2589283935 KBI_View14 "Dieser View wird vom Kombiinstrument unterstützt";
CM_ SG_ 2589283935 KBI_View15 "Dieser View wird vom Kombiinstrument unterstützt";
CM_ SG_ 2589283935 KBI_View16 "Dieser View wird vom Kombiinstrument unterstützt";
CM_ SG_ 2589283935 KBI_View17 "Dieser View wird vom Kombiinstrument unterstützt";
CM_ SG_ 2589283935 KBI_View18 "Dieser View wird vom Kombiinstrument unterstützt";
CM_ SG_ 2589283935 KBI_View19 "Dieser View wird vom Kombiinstrument unterstützt";
CM_ SG_ 2589283935 KBI_View2 "Dieser View wird vom Kombiinstrument unterstützt";
CM_ SG_ 2589283935 KBI_View20 "Dieser View wird vom Kombiinstrument unterstützt";
CM_ SG_ 2589283935 KBI_View21 "Dieser View wird vom Kombiinstrument unterstützt";
CM_ SG_ 2589283935 KBI_View22 "Dieser View wird vom Kombiinstrument unterstützt";
CM_ SG_ 2589283935 KBI_View23 "Dieser View wird vom Kombiinstrument unterstützt";
CM_ SG_ 2589283935 KBI_View24 "Dieser View wird vom Kombiinstrument unterstützt";
CM_ SG_ 2589283935 KBI_View3 "Dieser View wird vom Kombiinstrument unterstützt";
CM_ SG_ 2589283935 KBI_View4 "Dieser View wird vom Kombiinstrument unterstützt";
CM_ SG_ 2589283935 KBI_View5 "Dieser View wird vom Kombiinstrument unterstützt";
CM_ SG_ 2589283935 KBI_View6 "Dieser View wird vom Kombiinstrument unterstützt";
CM_ SG_ 2589283935 KBI_View7 "Dieser View wird vom Kombiinstrument unterstützt";
CM_ SG_ 2589283935 KBI_View8 "Dieser View wird vom Kombiinstrument unterstützt";
CM_ SG_ 2589283935 KBI_View9 "Dieser View wird vom Kombiinstrument unterstützt";

CM_ SG_ 2550399240 KS_ICAS3Sys01_Req_Data "Komponentenschutz (Funktion 01h). Request mit NA des Slaves.";

CM_ SG_ 2550530312 KS_ICAS3Sys01_Resp_Data "Komponentenschutz (Funktion 01h). Request mit NA des Slaves.";

CM_ SG_ 2549875059 KS_Info_El_Req_Data "Komponentenschutz (Funktion 01h). Request mit NA des Slaves.";

CM_ SG_ 2550006131 KS_Info_El_Resp_Data "Komponentenschutz (Funktion 01h). Response mit eigener NA.";

CM_ SG_ 2549899278 KS_SSN_ABT_1_Req_Data "Kompontenschutz DK2 ABT1";

CM_ SG_ 2550030350 KS_SSN_ABT_1_Resp_Data "Komponentenschutz DK2 ABT";

CM_ SG_ 2549875053 KS_TV_Tuner_Req_Data "Komponentenschutz (Funktion 01h). Request mit NA des Slaves.";

CM_ SG_ 2550006125 KS_TV_Tuner_Resp_Data "Komponentenschutz (Funktion 01h). Response mit eigener NA.";

CM_ SG_ 110 EPS_QBit_Zahnstangen_Grad "QBit zum Signal EPS_Zahnstangen_Grad";
CM_ SG_ 110 EPS_QBit_Zahnstangen_Pos "beschreibt die Qualität/Vertrauenswürdigkeit der Zahnstangenposition";
CM_ SG_ 110 EPS_Sensorikstatus "Status des Sensors";
CM_ SG_ 110 EPS_VZ_Zahnstangen_Grad "Vorzeichen Zahnstangengradient";
CM_ SG_ 110 EPS_VZ_Zahnstangenposition "Vorzeichen der Position/Verschiebung der Zahnstange bzgl. Lenkungsmitte
Vorzeichen:
(Fahreransicht: positiv = links von der Nullstellung des Lenkrades)
Nullstellung = +0mm";
CM_ SG_ 110 EPS_Zahnstangen_Grad "Zahnstangengeschwindigkeit";
CM_ SG_ 110 EPS_Zahnstangen_Pos_02 "Position der Zahnstange des Lenkgetriebes in mm";

CM_ SG_ 981 BCM1_Abblendlicht_Anf "Anforderung Abblendlicht
";
CM_ SG_ 981 BCM1_Adaptive_Lichtvert_Anf "Funktion 'Adaptive Lichtverteilung' im AFS-SG  Ein- und Ausschalten";
CM_ SG_ 981 BCM1_Allwetterlicht_Anf "Anforderung eines Allwetterlichts (über AFS-SG realisiert): Licht für schlechte Sichtverhältnisse";
CM_ SG_ 981 BCM1_Animationssperrung "Sperrung der Scheinwerfer- und Heckleuchten-Animationen. Grund für Sperrung sind allgemeine Rahmenbedingungen, wie beispielseweise eine LDS-Stellung ungleich 'Auto'";
CM_ SG_ 981 BCM1_Autobahnlicht_Anf "Anforderung Autobahnlicht
";
CM_ SG_ 981 BCM1_CH_aktiv "Coming Home (zusätzlich zum Signal 'BCM1_CH_LH_aktiv' in der Botschaft BCM1_01)";
CM_ SG_ 981 BCM1_CH_LH_aktiv "Status Comming / Leaving Home
";
CM_ SG_ 981 BCM1_Fernlicht_Anf "Anforderung Fernlicht
";
CM_ SG_ 981 BCM1_Gleitende_Leuchtw_Anf "Funktion 'Gleitende Leuchtweite' im AFS-SG  freischalten";
CM_ SG_ 981 BCM1_GLW_Fernlicht_Anf "Harte Fernlichtanforderung von BCM1 an die Funktion 'gleitende Leuchtweite' im AFS-SG";
CM_ SG_ 981 BCM1_Kurvenlicht_links_Anf "Ansteuerung linkes Kurvenlicht/Abbiegelicht duch BCM1";
CM_ SG_ 981 BCM1_Kurvenlicht_rechts_Anf "Ansteuerung rechtes Kurvenlicht/Abbiegelicht duch BCM1";
CM_ SG_ 981 BCM1_LH_aktiv "Leaving Home (zusätzlich zum Signal 'BCM1_CH_LH_aktiv' in der Botschaft BCM1_01)";
CM_ SG_ 981 BCM1_Nebellicht_Anf "Anforderung Nebellicht
";
CM_ SG_ 981 BCM1_Nebelschluss_Ahg_Anf "Anforderung: Nebelschlusslicht Anhänger (Sollzustand)
";
CM_ SG_ 981 BCM1_Nebelschluss_Fzg_Anf "Anforderung: Nebelschlusslicht Fahrzeug (Sollzustand)";
CM_ SG_ 981 BCM1_Parklicht_li_Anf "Anforderung: Parklicht links (Sollzustand)
";
CM_ SG_ 981 BCM1_Parklicht_re_Anf "Anforderung: Parklicht rechts (Sollzustand)
";
CM_ SG_ 981 BCM1_Regenlicht_Anf "Anforderung: Regenlicht (Sollzustand)
";
CM_ SG_ 981 BCM1_Schlusslicht_Anf "Anforderung: Schlusslicht Fahrzeug (Sollzustand)
";
CM_ SG_ 981 BCM1_Signaturlicht_Anf "Signal zur Anforderung des Signaturlichts";
CM_ SG_ 981 BCM1_Standlicht_Anf "Anforderung: Schlusslicht (Sollzustand)";
CM_ SG_ 981 BCM1_Tagfahrlicht_Anf "Anforderung: Tagfahrlicht (Sollzustand)";
CM_ SG_ 981 BCM1_Touristen_Licht_Anf "Anforderung: Touristenlicht (Sollzustand)";
CM_ SG_ 981 BCM1_Umfeldleuchten_Anf "Anforderung für Umfeldleuchten";
CM_ SG_ 981 BCM_Rueckfahrlicht_Anf "Anforderung Rückfahrlicht (Sollzustand). 
Das Signal wird entprellt (typisch 400ms) und bei KL15EIN gesendet. Das Signal ist unabhängig von der Position des Heckdeckels (kein Überhitzungsschutz).";
CM_ SG_ 981 Licht_Anf_01_BZ "4bit Botschaftszaehler, wird mit jeder Sendebotschaft inkrementiert";
CM_ SG_ 981 Licht_Anf_01_CRC "Für MLB:
'Berechnung siehe Lastenheft 'Kommunikationsabsicherung für FlexRay und CAN''

Ab MQB und MLBevo:
'Berechnung siehe Lastenheft 'End-to-End Kommunikationsabsicherung''

Endwerte siehe Begleitdokument 'S-PDU Kennungsfolgen'";
CM_ SG_ 981 TFL_Matrix_Variante01_Anf "Gibt die einzustellende Variante der Tagfahrlicht-Matrix an.";
CM_ SG_ 981 TFL_Matrix_Variante02_Anf "Gibt die einzustellende Variante der Tagfahrlicht-Matrix an.";
CM_ SG_ 981 TFL_Matrix_Variante03_Anf "Gibt die einzustellende Variante der Tagfahrlicht-Matrix an.";
CM_ SG_ 981 TFL_Matrix_Variante04_Anf "Gibt die einzustellende Variante der Tagfahrlicht-Matrix an.";

CM_ SG_ 982 BCM2_Bremsl_durch_ECD "Bremslicht (ECD-Bremsung)
";
CM_ SG_ 982 BCM2_Bremsl_durch_ECD_invers "Inversbit Bremslicht (ECD-Bremsung) (Kommunikationsabsicherung)";
CM_ SG_ 982 LH_3_Bremsl_def "Fehlerstatus 3. Bremsleuchte
";
CM_ SG_ 982 LH_Aussenlicht_def "Aussenlicht kann nicht mehr korrekt angesteuert werden (EEPROM Codierung kann nicht mehr ausgelesen werden)
";
CM_ SG_ 982 LH_Blinker_HL_akt "Blinker hinten links
";
CM_ SG_ 982 LH_Blinker_HR_akt "Blinker hinten rechts
";
CM_ SG_ 982 LH_Blinker_li_def "Fehlerstatus Blinker hinten links
";
CM_ SG_ 982 LH_Blinker_re_def "Fehlerstatus Blinker hinten rechts
";
CM_ SG_ 982 LH_Brems_Blk_li_def "Konfiguration BRL + BLK links 
";
CM_ SG_ 982 LH_Brems_Blk_re_def "Konfiguration BRL + BLK rechts
";
CM_ SG_ 982 LH_Bremsl_li_def "Fehlerstatus Bremslicht hinten links (Detektion Einzelausfall)
";
CM_ SG_ 982 LH_Bremsl_li_ges_def "Fehlerstatus Bremslicht hinten links (Detektion Totalausfall)
";
CM_ SG_ 982 LH_Bremsl_re_def "Fehlerstatus Bremslicht hinten rechts  (Detektion Einzelausfall)
";
CM_ SG_ 982 LH_Bremsl_re_ges_def "Fehlerstatus Bremslicht hinten rechts (Detektion Totalausfall)";
CM_ SG_ 982 LH_Bremslicht_H_aktiv "Bremslicht hinten
";
CM_ SG_ 982 LH_Diag_LED_li_def "Heckleuchte links defekt";
CM_ SG_ 982 LH_Diag_LED_re_def "Heckleuchte rechts defekt";
CM_ SG_ 982 LH_Diag_Status_li_def "Außenlicht Diagnose 
Systemstörung links";
CM_ SG_ 982 LH_Diag_Status_re_def "Außenlicht Diagnose Systemstörung rechts ";
CM_ SG_ 982 LH_Kennzl_def "Fehlerstatus Kennzeichenbeleuchtung hinten
";
CM_ SG_ 982 LH_Nebel_li_def "Fehlererkennung Nebelschlusslicht hinten links";
CM_ SG_ 982 LH_Nebel_mi_def "Fehlererkennung Nebelschlusslicht hinten Mitte


";
CM_ SG_ 982 LH_Nebel_re_def "Fehlererkennung Nebelschlusslicht hinten rechts
";
CM_ SG_ 982 LH_Nebelschluss_aktiv "Nebelschlusslicht
";
CM_ SG_ 982 LH_Parklicht_HL_aktiv "Parklicht hinten links 
";
CM_ SG_ 982 LH_Parklicht_HR_aktiv "Parklicht hinten rechts 
";
CM_ SG_ 982 LH_Rueckf_li_def "Fehlererkennung Rückfahrlicht hinten links
";
CM_ SG_ 982 LH_Rueckf_mi_def "Fehlererkennung Rückfahrlicht Mitte
";
CM_ SG_ 982 LH_Rueckf_re_def "Fehlererkennung Rückfahrlicht hinten rechts
";
CM_ SG_ 982 LH_Rueckfahrlicht_aktiv "Rueckfahrlicht";
CM_ SG_ 982 LH_Schluss_Brems_li_def "Konfiguration SL+ BRL + PL links und SL+ BRL  links
";
CM_ SG_ 982 LH_Schluss_Brems_Nebel_li_def "Signal wird gesetzt, wenn eine Unterbrechung oder  ein Kurzschluss am Lampenausgang für Schluss_Brems_Nebelschlusslicht erkannt wird.";
CM_ SG_ 982 LH_Schluss_Brems_Nebel_re_def "Signal wird gesetzt, wenn eine Unterbrechung oder  ein Kurzschluss am Lampenausgang für Schluss_Brems_Nebelschlusslicht erkannt wird.";
CM_ SG_ 982 LH_Schluss_Brems_re_def "Konfiguration SL+ BRL + PL rechts und SL+ BRL  rechts
";
CM_ SG_ 982 LH_Schluss_Nebel_li_def "Konfiguration SL + NSL links oder SL + NSL + PL links
";
CM_ SG_ 982 LH_Schluss_Nebel_re_def "Konfiguration SL + NSL rechts oder SL + NSL + PL rechts
";
CM_ SG_ 982 LH_Schlusslicht_li_def "Fehlererkennung Schlusslicht hinten links
";
CM_ SG_ 982 LH_Schlusslicht_re_def "Fehlererkennung Schlusslicht hinten rechts";
CM_ SG_ 982 LH_SL_BRL_BLK_li_def "Konfiguration SL + BRL + BLK links oder SL + BRL + BLK + PL links
";
CM_ SG_ 982 LH_SL_BRL_BLK_re_def "Konfiguration SL + BRL + BLK rechts oder SL + BRL + BLK + PL rechts
";
CM_ SG_ 982 LH_Standlicht_H_aktiv "Standlicht hinten
";
CM_ SG_ 982 LH_Zusatzschlussl_def "mindestens ein Zusatzschlusslicht in der Heckbeleuchtung defekt.";
CM_ SG_ 982 Licht_hinten_01_BZ "überlaufender 4bit Botschaftszaehler; wird in jeder Sendebotschaft inkrementiert";

CM_ SG_ 1624 BCM1_Licht_Dunkelheit_aktiv "Licht aktiv aufgrund von Dunkelheit (nicht bei Autobahn-, Tagfahr- oder Regenlicht)";
CM_ SG_ 1624 BCM1_Linksverkehr "Information über Aufbauzustand des Fzg:
0 = Scheinwerfer für Rechtsverkehr
1 = Scheinwerfer für Linksverkehr";
CM_ SG_ 1624 Licht_Vorne_01_CRC "Für MLB:
'Berechnung siehe Lastenheft 'Kommunikationsabsicherung für FlexRay und CAN''

Ab MQB und MLBevo:
'Berechnung siehe Lastenheft 'End-to-End Kommunikationsabsicherung''

Endwerte siehe Begleitdokument 'S-PDU Kennungsfolgen'";
CM_ SG_ 1624 LV_Abbiegelicht_li_def "Fehlerstatus Abbiegelicht vorne links
";
CM_ SG_ 1624 LV_Abbiegelicht_re_def "Fehlerstatus Abbiegelicht vorne rechts
";
CM_ SG_ 1624 LV_Abblend_Fernlicht_li_def "Fehlerstatus Abblendlicht und Fernlicht links ";
CM_ SG_ 1624 LV_Abblend_Fernlicht_re_def "Fehlerstatus Abblendlicht und Fernlicht rechts";
CM_ SG_ 1624 LV_Abblendlicht_Anzeige "Abblendlicht aktiv";
CM_ SG_ 1624 LV_Abblendlicht_li_def "Fehlerstatus Abblendlicht vorne links 
";
CM_ SG_ 1624 LV_Abblendlicht_re_def "Fehlerstatus Abblendlicht vorne rechts
";
CM_ SG_ 1624 LV_Abblendlicht_TFL_li_def "Fehlerstatus Abblendlicht und Tagfahrlicht links
";
CM_ SG_ 1624 LV_Abblendlicht_TFL_re_def "Fehlerstatus Abblendlicht und Tagfahrlicht rechts ";
CM_ SG_ 1624 LV_AFL_aktiv_Anzeige "Anzeige AFL-Funktion";
CM_ SG_ 1624 LV_AFL_defekt "Fehlerstatus AFL
";
CM_ SG_ 1624 LV_Aussenlicht_def "Aussenlicht kann nicht mehr korrekt angesteuert werden (EEPROM Codierung kann nicht mehr ausgelesen werden)
";
CM_ SG_ 1624 LV_Blinker_li_def "Fehlerstatus Blinker vorne links
";
CM_ SG_ 1624 LV_Blinker_re_def "Fehlerstatus Blinker vorne rechts
";
CM_ SG_ 1624 LV_Blinker_VL_aktiv "Blinker vorne links
";
CM_ SG_ 1624 LV_Blinker_VR_aktiv "Blinker vorne links
";
CM_ SG_ 1624 LV_Blk_li_Seite_def "Fehlerstatus Seitenblinker links
";
CM_ SG_ 1624 LV_Blk_re_Seite_def "Fehlerstatus Blinker Seite rechts
";
CM_ SG_ 1624 LV_Fernlicht_Anzeige "Fernlicht_aktiv";
CM_ SG_ 1624 LV_Fernlicht_li_def "Fehlerstatus Fernlicht vorne links
";
CM_ SG_ 1624 LV_Fernlicht_re_def "Fehlerstatus Fernlicht vorne rechts
";
CM_ SG_ 1624 LV_FLA_aktiv_Anzeige "Ansteuerung FLA-Lampe im Kombi (BCM1 Bedienmaster)";
CM_ SG_ 1624 LV_FLA_defekt "Fehlerstatus FLA (Anzeige des entsprechenden Fehlertext im Kombi)";
CM_ SG_ 1624 LV_FLA_Sensor_blockiert "Status FLA-Sensor (Anzeige des entsprechenden Fehlertext im Kombi)";
CM_ SG_ 1624 LV_LED_Scheinwerfer_li_def "Fehlerstatus LED-Scheinwerfer links
";
CM_ SG_ 1624 LV_LED_Scheinwerfer_re_def "Fehlerstatus LED-Scheinwerfer rechts";
CM_ SG_ 1624 LV_MXB_Status_Anzeige "Aktueller Status des Fernlichts / MxB zur Signalisierung im Kombi.";
CM_ SG_ 1624 LV_Nebellicht_Anzeige "Nebellicht_aktiv
";
CM_ SG_ 1624 LV_Nebellicht_li_def "Fehlerstatus Nebelscheinwerfer vorne links
";
CM_ SG_ 1624 LV_Nebellicht_re_def "Fehlerstatus Nebelscheinwerfer vorne rechts
";
CM_ SG_ 1624 LV_Nebellicht_TFL_li_def "Fehlerstatus Nebellicht und Tagfahrlicht links ";
CM_ SG_ 1624 LV_Nebellicht_TFL_re_def "Fehlerstatus Nebellicht und Tagfahrlicht rechts";
CM_ SG_ 1624 LV_Nebelschlusslicht_Anzeige "Nebelschlusslicht_aktiv
";
CM_ SG_ 1624 LV_Standlicht_Anzeige "Anzeige Standlicht
";
CM_ SG_ 1624 LV_Standlicht_li_def "Fehlerstatus Standlicht vorne links
";
CM_ SG_ 1624 LV_Standlicht_re_def "Fehlerstatus Standlicht vorne rechts
";
CM_ SG_ 1624 LV_Standlicht_TFL_li_def "Fehlerstatus Standlicht und Tagfahrlicht links ";
CM_ SG_ 1624 LV_Standlicht_TFL_re_def "Fehlerstatus Standlicht und Tagfahrlicht rechts ";
CM_ SG_ 1624 LV_Tagfahrlicht_Anzeige "Anzeige Tagfahrlicht
";
CM_ SG_ 1624 LV_Tagfahrlicht_li_def "Fehlerstatus Tagfahrlicht links
";
CM_ SG_ 1624 LV_Tagfahrlicht_re_def "Fehlerstatus Tagfahrlicht rechts";

CM_ SG_ 2463978598 LoGeWa_C2C_Anf_Audioabsenkung "Anforderung der Audioabsenkung im Infotainment, aufgrund empfangener Car-2-Car Nachricht (z.B. SonderEinsatzFahrzeuge)";
CM_ SG_ 2463978598 LoGeWa_C2C_Event_Einheit "Einheit der Entfernung des Events für Kombianzeige von Car2Car";
CM_ SG_ 2463978598 LoGeWa_C2C_Event_Entfernung "Entfernung des Events für Kombianzeige von Car2Car";
CM_ SG_ 2463978598 LoGeWa_C2C_Event_Richtung "Richtung des Events für Kombianzeige von Car2Car";
CM_ SG_ 2463978598 LoGeWa_C2C_Event_Status "Status der Anzeige des Events für Kombianzeige von Car2Car";
CM_ SG_ 2463978598 LoGeWa_C2C_Event_Warnung "Typ des Events für Kombianzeige von Car2Car";

CM_ SG_ 2527679633 LSH_Ansaug_Fuell_1 "Luftstandheizungsansaugtemperaturfühler 1";
CM_ SG_ 2527679633 LSH_Ansaug_Fuell_2 "Luftstandheizungsansaugtemperaturfühler 2";
CM_ SG_ 2527679633 LSH_Empf_Heizstufe "Heizstufen";
CM_ SG_ 2527679633 LSH_Funk_aus "LSH über Funksignal ausschalten";
CM_ SG_ 2527679633 LSH_Funk_ein "LSH über Funksignal einschalten";
CM_ SG_ 2527679633 LSH_Geblaese_aktiv "Anzeige der Luftstandheizung, dass das interne Gebläse aktiv ist.
0 = Gebläse inaktiv
1 = Gebläse aktiv";
CM_ SG_ 2527679633 LSH_Heiztemp "Luftheizungswärmetauschertemperatur";
CM_ SG_ 2527679633 LSH_Klappe_Status "Status Luftklappe";
CM_ SG_ 2527679633 LSH_LED "Funktionslampe Luftstandheizung";
CM_ SG_ 2527679633 LSH_Servicemode "Luftstandheizung Servicemode";
CM_ SG_ 2527679633 LSH_Start_folgt "Thema Start/Stop: Im Stop-Modus muß das KBT einen Wiederstart anfordern, da ein STH-Start notwendig ist.";
CM_ SG_ 2527679633 LSH_Texte "Anforderung der untersch. Anzeigetexte im Mitteldisplay d. Kombi.

0: Keine Anzeige
1: Kein Standheizungsbetrieb wegen Batteriemanagementeinschränkung
2: Kein Standheizungsbetrieb wegen Kraftstoffmangels
3: Kein Standheizungsbetrieb wegen internem Sy";
CM_ SG_ 2527679633 LSH_Waermeeintrag "Signal enthält die Brenndauer der Luftstandheizung in 5min-Schritten";

CM_ SG_ 2527679634 LSH_Fehlerstatus "Fehlerstatus Luftstandheizung";
CM_ SG_ 2527679634 LSH_Heizleistung "Heizleistung in %";
CM_ SG_ 2527679634 LSH_KL_DBetr_Anf "Sicherheitsabfrage der Luftstandheizung, ob Dauerstandheizbetrieb wirklich gestartet werden soll.
Bestätigungsbit für Anforderung KL_LSH_DBetr_Ein";
CM_ SG_ 2527679634 LSH_KVS "Kraftstoffverbrauch";
CM_ SG_ 2527679634 LSH_KVS_Ueberlauf "Kraftstoffverbrauch Ueberlauf";
CM_ SG_ 2527679634 LSH_Zuheizen "Rückmeldung von der Luftstandheizung, dass das Gerät im Zuheizbetrieb ist.";

CM_ SG_ 134 LWI_01_BZ "Botschaft asynchron geroutet. Zählerwert kann springen.";
CM_ SG_ 134 LWI_01_CRC "Für MLB:
'Berechnung siehe Lastenheft 'Kommunikationsabsicherung für FlexRay und CAN''

Ab MQB und MLBevo:
'Berechnung siehe Lastenheft 'End-to-End Kommunikationsabsicherung'

Endwerte siehe Begleitdokument 'S-PDU Kennungsfolgen'";
CM_ SG_ 134 LWI_Lenkradw_Geschw "Wertebereich = +/- 2500 Grad/s
Auflösung = 5 Grad/s

Hinweis: Zusätzlich gestellte Winkel bei Dynamiklenkung beachten !";
CM_ SG_ 134 LWI_Lenkradwinkel "Wertebereich = +/- 800 Grad
Auflösung = 0,1 Grad
ACHTUNG: spezifizierte Interne Auflösung des Sensors beträgt aber nur Schrittweite 0,5 Grad!

Hinweis:
MLB: Zusätzlich gestellte Winkel bei Dynamiklenkung beachten !
MQB: Nicht konstante Lenkübersetzu";
CM_ SG_ 134 LWI_QBit_Lenkradwinkel "Das QBit wird auch bei nicht abgeglichenem Lenkradwinkelsensor gesetzt";
CM_ SG_ 134 LWI_QBit_Sub_Daten "Es gilt die Signalspezifikation laut LAH";
CM_ SG_ 134 LWI_Sub_Daten "Verschlüsseltes Datenpaket vom Sub-Rechner des LWS, Verwendung nur durch SCU und ESP_ADS
Verwendung gemäß 'Sicherheitsanforderungen an Empfängersteuergeräte'

Im MLB gilt die Signalspezifikation: LAH 8K0953B
Im MLBevo gilt die Signalspezifikation LAH.";
CM_ SG_ 134 LWI_VZ_Lenkradw_Geschw "Vorzeichen Lenkradwinkelgeschwindigkeit gemäss DIN70000; 
Nullstellung = +0";
CM_ SG_ 134 LWI_VZ_Lenkradwinkel "Vorzeichen Lenkradwinkel gemäss DIN70000; 
Nullstellung = +0";

CM_ SG_ 1153 DSSS_Warning "DSSS - Driving Safety Support System Meldungen";
CM_ SG_ 1153 MIB_ASW_Diagnose "Diagnose Rückmeldung vom MIB zu Heckradar Entry. ASW Warnton Verfügbarkeit.";
CM_ SG_ 1153 MIB_Tongenerator_PH_verfuegbar "Verfügbarkeit des Tongenerators im MIB für die Nutzung durch die Parkhilfe";
CM_ SG_ 1153 MMI_Counter_Bedienevent "Signal wird inkrementiert, wenn Bedienevent stattgefunden hat.";
CM_ SG_ 1153 MMI_Gurt_Mic_ref "Referenzsignal für das Gurtmikrofon Steuergerät zur Signalisierung ob der Downlink aktiv oder inaktiv ist";
CM_ SG_ 1153 MMI_SDS_aktiv "Signal wird gesetzt, solange die Sprachbedienung aktiv ist.";
CM_ SG_ 1153 MU_SecondDisplay "Dient zur Überwachung der zweiten LVDS Leitung.";
CM_ SG_ 1153 MU_Update_Time "Ermöglicht auslesen der Historiendaten, wann ein Update lief";
CM_ SG_ 1153 Nav_FoD_Status "FoD Status der Navigation";
CM_ SG_ 1153 ZR_AppConnect_Zustand "Ist Zustand des AppConnect Kontextes im MIB";
CM_ SG_ 1153 ZR_Kindersicherung_RSE "Sperren der Rearseat Unit (Komplette Weckfähigkeit)";
CM_ SG_ 1153 ZR_Lichter_Tag "Berechnete Kennzeichnung des Sonnenstandes über bzw. oder unter Horizont.";
CM_ SG_ 1153 ZR_LoGeWa_Event_Kombiwarnung "Event für Kombiwarnung";
CM_ SG_ 1153 ZR_Parken_Sondermodus "Rückkanal zum pilotierten Parken zur Signalisierung Status Sondermodus";
CM_ SG_ 1153 ZR_RSE_aktivieren "Weckfähigkeit der RSE";
CM_ SG_ 1153 ZR_Sta_Inszenierung "MIB sendet Status über Inszenierungssound (welcome sound) an BCM1
Zweck: Synchronisierung mit weiteren Teilnehmern der Startupinszenierung";

CM_ SG_ 1178 FS_BFS_Fond_Verst_enable "Verstellung Fond (vom MMI)
";
CM_ SG_ 1178 FS_BFS_KSS_Anfahrt "Komfortseitensicht Anfahrt BFS";
CM_ SG_ 1178 FS_BFS_Sitzsym_Anfahrt "Sitzsymetrie Anfahrt BFS";
CM_ SG_ 1178 FS_EE_BFS_enable "EasyEntry Freigabe für Befahrersitz.";
CM_ SG_ 1178 FS_EE_Fond_BFS_enable "EE Fond rechts

";
CM_ SG_ 1178 FS_EE_Fond_FS_enable "EE Fond links
";
CM_ SG_ 1178 FS_Fond_Bed_enable "Freigabe für Fondsitzverstellungen";
CM_ SG_ 1178 FS_GHV_aktiv "Verstellung Gurthöhe
";
CM_ SG_ 1178 FS_Gurtbringer_Sperre "Freigabesignal für den Gurtzubringer";
CM_ SG_ 1178 FS_KSV_aktiv "Verstellung Kopfstütze
";
CM_ SG_ 1178 FS_Lehne_nicht_verriegelt "Fahrer Sitz Lehne Verstellung Verriegelt Status

Verwendung nur im Bentley";
CM_ SG_ 1178 FS_LHV_aktiv "Verstellung Lordose Höhe
";
CM_ SG_ 1178 FS_LKV_aktiv "Verstellung Lehnenkopf
";
CM_ SG_ 1178 FS_LNV_aktiv "Verstellung Lehnenneigung
";
CM_ SG_ 1178 FS_LWV_aktiv "Verstellung Lordose W
";
CM_ SG_ 1178 FS_MMB_glob_stop "Abbruch Memoryverstellung";
CM_ SG_ 1178 FS_MMB_lokal_Stop "mit dem lokal Stop moechte man, dass ein Sitz mit Pneumatik - Lordose sich im Memoryfall wie ein Sitz mit elektromechanischer Lordose verhaelt. Nur lokler Abbruch im TIP-Betrieb.";
CM_ SG_ 1178 FS_MMB_storage "Memory-Positionstaste, Funkschlüssel-Memory-ID, Benutzerkonto-Nummer";
CM_ SG_ 1178 FS_MMB_storage_beep "Quittierungston Sitzmemory FS (Anforderung Kombi)";
CM_ SG_ 1178 FS_MMB_store "Memoryposition Speichern";
CM_ SG_ 1178 FS_MMB_store_LED_on "LED für Speichern
";
CM_ SG_ 1178 FS_MMB_tast "Memoryverstellung im Tastbetrieb";
CM_ SG_ 1178 FS_MMB_tipp "Memoryverstellung im Tippbetrieb";
CM_ SG_ 1178 FS_SHV_aktiv "Verstellung Sitzhöhe

";
CM_ SG_ 1178 FS_Sitzfahrt_aktiv "Aktive Sitzfahrt Fahrersitz
";
CM_ SG_ 1178 FS_SLV_aktiv "Sitzlängsverstellung
";
CM_ SG_ 1178 FS_SNV_aktiv "Verstellung Sitzneigung
";
CM_ SG_ 1178 FS_Spezialposition_anfahren "paralell zu diesem Signal wird eine Botschaft auf den KCAN gesendet in der spezielle Anforderungen für den Empfänger stehen. 
Dieses Signal dient zusätzlich der Checksummenabsicherung bei einer Remotverstellung ";
CM_ SG_ 1178 FS_STV_aktiv "Verstellung Sitztiefe
";
CM_ SG_ 1178 Mem_FS_01_MQB_BZ "4bit Botschaftszähler, wird mit jeder Sendebotschaft inkrementiert";
CM_ SG_ 1178 Mem_FS_01_MQB_CRC "Für MLB:
Berechnung siehe Lastenheft 'Kommunikationsabsicherung für FlexRay und CAN'
Ab MQB und MLBevo:
Berechnung siehe Lastenheft 'End-to-End Kommunikationsabsicherung'

Endwerte siehe Begleitdokument 'S-PDU Kennungsfolgen'";

CM_ SG_ 1165 MF_ADR_Anforderung "Anforderung der Arbeitsdrehzahlanhebung";
CM_ SG_ 1165 MF_ADR_Fahrpedalsperre "Aktivierung der Fahrpedalsperre";
CM_ SG_ 1165 MF_ADR_neg_Rampe "Gradient Abschaltung ADR";
CM_ SG_ 1165 MF_ADR_pos_Rampe "Gradient Drehzahl Einschaltung ADR";
CM_ SG_ 1165 MF_ADR_Solldrehzahl "Solldrehzahl der Arbeitsdrehzahlregelung";
CM_ SG_ 1165 MF_MFSS_aktiv "Status der Funktion Motor-Fern-Start-Stopp";
CM_ SG_ 1165 MF_MFSS_kodiert "MFG/ KFG zeigt Kodierstatus auf MFSS";
CM_ SG_ 1165 MF_VBEG_Anforderung "Anforderung Geschwindigkeitsbegrenzung";
CM_ SG_ 1165 MF_VBEG_Geschwindigkeit "Geschwindigkeitsbegrenzung KFG";
CM_ SG_ 1165 MFG_02_BZ "Botschaftszähler";
CM_ SG_ 1165 MFG_02_CRC "Für MLB:
'Berechnung siehe Lastenheft 'Kommunikationsabsicherung für FlexRay und CAN''

Ab MQB und MLBevo:
'Berechnung siehe Lastenheft 'End-to-End Kommunikationsabsicherung''

Endwerte siehe Begleitdokument 'S-PDU Kennungsfolgen'

Kennungsfolge:";
CM_ SG_ 1165 MFG_Heizstufe_LSH "Vom Klimabedienteil gesendete Heizstufe der Luftstandheizung";
CM_ SG_ 1165 MFG_Status_SREG "Über das Signal wird dem Motorsteuergerät der Freischaltstatus der Funktion Stand Regeneration (SREG) übermittelt.";
CM_ SG_ 1165 MFG_Taster_SREG "Über den Taster SREG wird die Funktion im MSG aktiviert. Ein fehlerhafter Schaltzustand wird berücksichtigt";
CM_ SG_ 1165 MFG_Taster_VREG "Über den Taster VREG wird die Funktion im MSG aktiviert. Ein fehlerhafter Schaltzustand wird berücksichtigt";
CM_ SG_ 1165 MFG_Zuheizer_Freigabe "Freigabe Zuheizer";

CM_ SG_ 1164 MF_2BatSOCzugering "Anzeige bei geringer Ladung der Zweitbatterie";
CM_ SG_ 1164 MF_2BattAb "Batterie Ab Warnung der Zweitbatterie";
CM_ SG_ 1164 MF_2BattHlkAnf "Anforderung einer HLK - Stufe an das BEM";
CM_ SG_ 1164 MF_2BattLadWarn "Anzeige das bei Motorlauf die Zweitbatterie entladen wird im KI";
CM_ SG_ 1164 MF_2BattLlaAnf "Anforderung einer Drehzahlanhebung an das BEM";
CM_ SG_ 1164 MF_2BattSpannungsAnf "Mindestspannugnsanforderung der Zusatbatterie an den BEM";
CM_ SG_ 1164 MF_Batteriediagnose "Erstellt für Zusatzbatterie Crafter";
CM_ SG_ 1164 MF_Blinker_L_Sta "Status Blinker links Sonderaufbauten";
CM_ SG_ 1164 MF_Blinker_R_Sta "Status Blinker rechts Sonderaufbauten";
CM_ SG_ 1164 MF_ExterneLadungWarn "Warnung bei Motorlauf das externer Ladestecker gesteckt ist im KI";
CM_ SG_ 1164 MF_Fahrerhinweis "Fahrerhinweis Kombiinstrument";
CM_ SG_ 1164 MF_Generatordiagnose "Neu erstellt für Crafter";
CM_ SG_ 1164 MF_Heck_entriegeln "Entriegelung Heck über KFG";
CM_ SG_ 1164 MF_Heck_verriegeln "Verriegelung Heck über KFG";
CM_ SG_ 1164 MF_interm_Nebelscheinwerfer "Intermittierender Nebelscheinwerfer bei einer Einsatzfahrt";
CM_ SG_ 1164 MF_Lampenausfall "Meldung Lampenausfall Aufbauhersteller";
CM_ SG_ 1164 MF_LSH_Abschaltstufe "Abschaltstufen der Luftstandheizung an der Zweitbatterie. Das Signal dient der Steuerung des Klima SG an der ersten Batterie und der LSH an der zweiten Batterie durch das Zweitbatterie Em im KFG";
CM_ SG_ 1164 MF_LSH_Einschaltverbot "Statussignal für das Einschaltverbot der Luftstandheizung an der Zweitbatterie, Steuerung durch das Zweitbatterie EM im KFG.
0 volle Verfuegbarkeit Standheizung/-lueftung
1 Standheizung/-lueftung nicht aktivierbar";
CM_ SG_ 1164 MF_LSH_Zielzeit "Definition der Zielzeit für die Luftstandheizung an der zweiten Batterie, Steuerung durch das Zweitbatterie EM im KFG.";
CM_ SG_ 1164 MF_NotStartAktiv "Anzeige Notstart Aktiv für den Zeitraum der Schließung des Notstartrelais";
CM_ SG_ 1164 MF_Radiomute "Wird bei Sonderfahrzeugen wie Polizei dafür verwendet, um das Radio bei einem eingehenden Funkspruch zu muten.";
CM_ SG_ 1164 MF_Relais_2_Batterie "Zeigt den Zustand des vom KFG angesteuerten Laderelais einer verbauten 2. Batterie an";
CM_ SG_ 1164 MF_Tuerverriegelung_hinten "Internes Verriegeln der hinteren Türen";
CM_ SG_ 1164 MF_ZV_Unlock "Globales entriegeln über KFG";
CM_ SG_ 1164 MFG_AppConnect_Anf "AppConnect Anforderung durch das KFG";
CM_ SG_ 1164 MFG_Infotainment_Autark "Das Signal gibt an ob die Energieversorgung für ein Infotainment im Fahrzeug Autarkbetrieb sichergestellt ist";
CM_ SG_ 1164 MFG_Klappe_Status "Einstellung der Luftklappenposition an der Luftstandheizung";
CM_ SG_ 1164 MFG_LSH_Ansteuerung "Ansteuerung LSH";
CM_ SG_ 1164 MFG_LSH_Betriebsdauer "Betriebsdauer LSH";
CM_ SG_ 1164 MFG_LSH_DBetr_Bestaet "Bestätigung des KFGs an die LSH, dass Dauerbetrieb tatsächlich angefordert ist.";
CM_ SG_ 1164 MFG_LSH_DBetr_Ein "Dauerbetrieb der Luftstandheizung Ein";

CM_ SG_ 1471 MFL_Eventcode_1 "Siehe Q-LAH MFL-Protokoll";
CM_ SG_ 1471 MFL_Eventcode_2 "Siehe Q-LAH MFL-Protokoll";
CM_ SG_ 1471 MFL_Marke "Marke für markenspezifische Variantennummer des MFL";
CM_ SG_ 1471 MFL_Tastencode_1 "Beschreibt die Funktion einer fest zugeordneten Taste/Walze auf dem MFL. Bei Betätigung ändert sich der Wert von 0x0 auf den jeweiligen Tastencode.";
CM_ SG_ 1471 MFL_Tastencode_2 "Beschreibt die Funktion einer fest zugeordneten Taste/Walze auf dem MFL. Ist MFL_Tastencode_1 wegen Betätigung einer Taste/Walze bereits mit einem Wert ungleich 0x0 belegt, so ändert sich bei Betätigung einer weiteren Taste/Walze der Wert dieses Signals v";
CM_ SG_ 1471 MFL_Variante "Markenspezifische Variantennummer des MFL";

CM_ SG_ 2463978670 SDF2_MIB_Fehler_Laengsrichtung "Längsfehler der Positionierung im ZR.";
CM_ SG_ 2463978670 SDF2_MIB_Inhibitzeit "Zeitspanne zwischen Generierung und Versand der Positionsdaten im ZR.";
CM_ SG_ 2463978670 SDF2_MIB_Offset "Verbleibende Länge des Streckensegments, auf dem sich das Fahrzeug nach der Positionierung auf dem ZR befindet.";
CM_ SG_ 2463978670 SDF2_MIB_Segment_ID "PSD-Segment ID der Positionierung im ZR";
CM_ SG_ 2463978670 SDF2_MIB_Standort_Eindeutig "Information, ob die Position des Fahrzeugs im ZR eindeutig dem aktuellen Segment zugeordnet wurde.";
BA_DEF_REL_ BU_SG_REL_  "GenSigTimeoutTime" INT 0 65535;
BA_DEF_ BO_  "DiagRequest" ENUM "No", "Yes";
BA_DEF_ BO_  "DiagResponse" ENUM "No", "Yes";
BA_DEF_ BO_  "DiagState" ENUM "No", "Yes";
BA_DEF_ BO_  "GenMsgChkConstant" HEX 0 4095;
BA_DEF_ BO_  "GenMsgCycleTime" INT 0 65535;
BA_DEF_ BO_  "GenMsgCycleTimeFast" INT 0 65535;
BA_DEF_ BO_  "GenMsgDelayTime" INT 0 100000;
BA_DEF_ BO_  "GenMsgILSupport" ENUM "No", "Yes";
BA_DEF_ BO_  "GenMsgNrOfRepetition" INT 0 100;
BA_DEF_ BO_  "GenMsgPDUConstants" STRING;
BA_DEF_ BO_  "GenMsgSendType" ENUM "Cyclic", "not_used", "not_used", "not_used", "not_used", "not_used", "not_used", "IfActive", "NoMsgSendType";
BA_DEF_ BO_  "GenMsgStartDelayTime" INT 0 100000;
BA_DEF_ BO_  "NmMessage" ENUM "No", "Yes";
BA_DEF_ BO_  "NmhMessage" ENUM "No", "Yes";
BA_DEF_ BO_  "MsgType" ENUM "Application", "NM ", "NMH", "TP2.0", "ISO-TP ", "BAP", "EID", "KS", "XCP_PRE_CONFIGURED", "XCP_RUNTIME_CONFIGURED";
BA_DEF_ BO_  "VAGTP20_API" HEX 0 255;
BA_DEF_ BO_  "VAGTP20_DynConnection" ENUM "No", "Yes";
BA_DEF_ BO_  "VAGTP20_DynSetup" ENUM "No", "Yes";
BA_DEF_ BO_  "VAGTP20_StatConnection" ENUM "No", "Yes";
BA_DEF_ SG_  "GenSigActiveRepetitions" INT -2147483648 2147483647;
BA_DEF_ SG_  "GenSigInactiveValue" INT -2147483648 2147483647;
BA_DEF_ SG_  "GenSigSendType" ENUM "Cyclic", "OnWrite", "OnWriteWithRepetition", "OnChange", "OnChangeWithRepetition", "IfActive", "IfActiveWithRepetition", "NoSigSendType", "OnChangeAndIfActive", "OnChangeAndIfActiveWithRepetition";
BA_DEF_ SG_  "GenSigStartValue" INT -2147483648 2147483647;
BA_DEF_ SG_  "NWM-WakeupAllowed" ENUM "No", "Yes";
BA_DEF_ SG_  "GenSigFuncType" ENUM "NoFunction", "MsgCounter", "CRC-8", "XOR", "XOR-2", "DatedBit", "SW-Kl15", "CHK", "Constant", "Protocol", "CRC-8-SAE_J1850", "CRC-32", "DataLength", "DataID", "MsgCounter16", "SOK-Signatur", "Cluster";
BA_DEF_ SG_  "GenSigSwitchedByIgnition" ENUM "No", "Yes";
BA_DEF_ SG_  "Fehlerwert" HEX 0 2147483647;
BA_DEF_ SG_  "GenSigMissingSourceValue" HEX 0 2147483647;
BA_DEF_DEF_REL_  "GenSigTimeoutTime" 0;
BA_DEF_DEF_  "DiagRequest" "No";
BA_DEF_DEF_  "DiagResponse" "No";
BA_DEF_DEF_  "DiagState" "No";
BA_DEF_DEF_  "GenMsgChkConstant" 0;
BA_DEF_DEF_  "GenMsgCycleTime" 0;
BA_DEF_DEF_  "GenMsgCycleTimeFast" 0;
BA_DEF_DEF_  "GenMsgDelayTime" 0;
BA_DEF_DEF_  "GenMsgILSupport" "No";
BA_DEF_DEF_  "GenMsgNrOfRepetition" 0;
BA_DEF_DEF_  "GenMsgPDUConstants" "";
BA_DEF_DEF_  "GenMsgSendType" "NoMsgSendType";
BA_DEF_DEF_  "GenMsgStartDelayTime" 0;
BA_DEF_DEF_  "NmMessage" "No";
BA_DEF_DEF_  "NmhMessage" "No";
BA_DEF_DEF_  "MsgType" "Application";
BA_DEF_DEF_  "VAGTP20_API" 0;
BA_DEF_DEF_  "VAGTP20_DynConnection" "No";
BA_DEF_DEF_  "VAGTP20_DynSetup" "No";
BA_DEF_DEF_  "VAGTP20_StatConnection" "No";
BA_DEF_DEF_  "GenSigActiveRepetitions" 0;
BA_DEF_DEF_  "GenSigInactiveValue" 0;
BA_DEF_DEF_  "GenSigSendType" "NoSigSendType";
BA_DEF_DEF_  "GenSigStartValue" 0;
BA_DEF_DEF_  "NWM-WakeupAllowed" "No";
BA_DEF_DEF_  "GenSigFuncType" "NoFunction";
BA_DEF_DEF_  "GenSigSwitchedByIgnition" "Yes";
BA_DEF_DEF_  "Fehlerwert" 0;
BA_DEF_DEF_  "GenSigMissingSourceValue" 0;
BA_ "GenMsgCycleTime" BO_ 2549088371 500;
BA_ "GenMsgILSupport" BO_ 2549088371 1;
BA_ "GenMsgSendType" BO_ 2549088371 0;
BA_ "GenMsgCycleTime" BO_ 2549088420 500;
BA_ "GenMsgILSupport" BO_ 2549088420 1;
BA_ "GenMsgSendType" BO_ 2549088420 0;
BA_ "GenMsgCycleTime" BO_ 2549088267 500;
BA_ "GenMsgILSupport" BO_ 2549088267 1;
BA_ "GenMsgSendType" BO_ 2549088267 0;
BA_ "GenMsgCycleTime" BO_ 2549088362 500;
BA_ "GenMsgILSupport" BO_ 2549088362 1;
BA_ "GenMsgSendType" BO_ 2549088362 0;
BA_ "GenMsgCycleTime" BO_ 779 50;
BA_ "GenMsgILSupport" BO_ 779 1;
BA_ "GenMsgSendType" BO_ 779 0;
BA_ "GenMsgCycleTime" BO_ 1719 1000;
BA_ "GenMsgDelayTime" BO_ 1719 100;
BA_ "GenMsgILSupport" BO_ 1719 1;
BA_ "GenMsgSendType" BO_ 1719 0;
BA_ "GenMsgCycleTime" BO_ 1720 1000;
BA_ "GenMsgILSupport" BO_ 1720 1;
BA_ "GenMsgSendType" BO_ 1720 0;
BA_ "GenMsgCycleTime" BO_ 2527679639 1000;
BA_ "GenMsgCycleTimeFast" BO_ 2527679639 100;
BA_ "GenMsgDelayTime" BO_ 2527679639 100;
BA_ "GenMsgILSupport" BO_ 2527679639 1;
BA_ "GenMsgNrOfRepetition" BO_ 2527679639 5;
BA_ "GenMsgSendType" BO_ 2527679639 0;
BA_ "GenMsgCycleTime" BO_ 2527679656 1000;
BA_ "GenMsgDelayTime" BO_ 2527679656 50;
BA_ "GenMsgILSupport" BO_ 2527679656 1;
BA_ "GenMsgSendType" BO_ 2527679656 0;
BA_ "GenMsgCycleTime" BO_ 2589283935 1000;
BA_ "GenMsgCycleTimeFast" BO_ 2589283935 100;
BA_ "GenMsgDelayTime" BO_ 2589283935 50;
BA_ "GenMsgILSupport" BO_ 2589283935 1;
BA_ "GenMsgNrOfRepetition" BO_ 2589283935 5;
BA_ "GenMsgSendType" BO_ 2589283935 0;
BA_ "MsgType" BO_ 2550399240 4;
BA_ "MsgType" BO_ 2550530312 4;
BA_ "MsgType" BO_ 2549875059 4;
BA_ "MsgType" BO_ 2550006131 4;
BA_ "MsgType" BO_ 2549899278 4;
BA_ "MsgType" BO_ 2550030350 4;
BA_ "MsgType" BO_ 2549875053 4;
BA_ "MsgType" BO_ 2550006125 4;
BA_ "GenMsgCycleTime" BO_ 110 100;
BA_ "GenMsgILSupport" BO_ 110 1;
BA_ "GenMsgPDUConstants" BO_ 110 "0xd9,0xb3,0x09,0xa6,0x77,0x68,0xc5,0x85,0xf0,0xf1,0x0d,0xdd,0xad,0x0c,0x0a,0xae";
BA_ "GenMsgSendType" BO_ 110 0;
BA_ "GenMsgCycleTime" BO_ 981 100;
BA_ "GenMsgDelayTime" BO_ 981 50;
BA_ "GenMsgILSupport" BO_ 981 1;
BA_ "GenMsgPDUConstants" BO_ 981 "0xc5,0x39,0xc7,0xf9,0x92,0xd8,0x24,0xce,0xf1,0xb5,0x7a,0xc4,0xbc,0x60,0xe3,0xd1";
BA_ "GenMsgSendType" BO_ 981 0;
BA_ "GenMsgCycleTime" BO_ 982 100;
BA_ "GenMsgDelayTime" BO_ 982 20;
BA_ "GenMsgILSupport" BO_ 982 1;
BA_ "GenMsgSendType" BO_ 982 0;
BA_ "GenMsgCycleTime" BO_ 1624 1000;
BA_ "GenMsgDelayTime" BO_ 1624 50;
BA_ "GenMsgILSupport" BO_ 1624 1;
BA_ "GenMsgPDUConstants" BO_ 1624 "0x46,0x0f,0xe0,0xcc,0xbe,0xb1,0xd7,0xf1,0x1f,0x31,0xc1,0x25,0xb4,0x3e,0xc8,0xa3";
BA_ "GenMsgSendType" BO_ 1624 0;
BA_ "GenMsgCycleTime" BO_ 2463978598 200;
BA_ "GenMsgDelayTime" BO_ 2463978598 100;
BA_ "GenMsgILSupport" BO_ 2463978598 1;
BA_ "GenMsgSendType" BO_ 2463978598 0;
BA_ "GenMsgCycleTime" BO_ 2527679633 200;
BA_ "GenMsgILSupport" BO_ 2527679633 1;
BA_ "GenMsgSendType" BO_ 2527679633 0;
BA_ "GenMsgCycleTime" BO_ 2527679634 200;
BA_ "GenMsgILSupport" BO_ 2527679634 1;
BA_ "GenMsgSendType" BO_ 2527679634 0;
BA_ "GenMsgChkConstant" BO_ 134 134;
BA_ "GenMsgCycleTime" BO_ 134 500;
BA_ "GenMsgILSupport" BO_ 134 1;
BA_ "GenMsgPDUConstants" BO_ 134 "0x86,0x86,0x86,0x86,0x86,0x86,0x86,0x86,0x86,0x86,0x86,0x86,0x86,0x86,0x86,0x86";
BA_ "GenMsgSendType" BO_ 134 0;
BA_ "GenMsgCycleTime" BO_ 1153 500;
BA_ "GenMsgCycleTimeFast" BO_ 1153 50;
BA_ "GenMsgDelayTime" BO_ 1153 50;
BA_ "GenMsgILSupport" BO_ 1153 1;
BA_ "GenMsgNrOfRepetition" BO_ 1153 5;
BA_ "GenMsgSendType" BO_ 1153 0;
BA_ "GenMsgCycleTime" BO_ 1178 100;
BA_ "GenMsgDelayTime" BO_ 1178 50;
BA_ "GenMsgILSupport" BO_ 1178 1;
BA_ "GenMsgPDUConstants" BO_ 1178 "0xd0,0xc5,0xac,0x82,0xb1,0xfb,0x24,0x4d,0xc0,0x20,0x4b,0xbc,0x86,0x3b,0x22,0x25";
BA_ "GenMsgSendType" BO_ 1178 0;
BA_ "GenMsgCycleTime" BO_ 1165 200;
BA_ "GenMsgILSupport" BO_ 1165 1;
BA_ "GenMsgPDUConstants" BO_ 1165 "0x84,0xcb,0x82,0xa1,0x41,0xe2,0xfa,0x9a,0x90,0x5e,0x51,0xe3,0xe8,0xc4,0x7f,0xf1";
BA_ "GenMsgSendType" BO_ 1165 0;
BA_ "GenMsgCycleTime" BO_ 1164 200;
BA_ "GenMsgCycleTimeFast" BO_ 1164 50;
BA_ "GenMsgDelayTime" BO_ 1164 20;
BA_ "GenMsgILSupport" BO_ 1164 1;
BA_ "GenMsgNrOfRepetition" BO_ 1164 5;
BA_ "GenMsgSendType" BO_ 1164 0;
BA_ "GenMsgCycleTimeFast" BO_ 1471 1000;
BA_ "GenMsgDelayTime" BO_ 1471 30;
BA_ "GenMsgILSupport" BO_ 1471 1;
BA_ "GenMsgNrOfRepetition" BO_ 1471 5;
BA_ "GenMsgCycleTime" BO_ 2463978670 150;
BA_ "GenMsgILSupport" BO_ 2463978670 1;
BA_ "GenMsgSendType" BO_ 2463978670 0;
BA_ "GenSigSendType" SG_ 2549088371 Info_El_Abschaltstufe 0;
BA_ "GenSigSwitchedByIgnition" SG_ 2549088371 Info_El_Abschaltstufe 0;
BA_ "GenSigSendType" SG_ 2549088371 Info_El_KD_Fehler 0;
BA_ "GenSigSwitchedByIgnition" SG_ 2549088371 Info_El_KD_Fehler 0;
BA_ "GenSigSendType" SG_ 2549088371 Info_El_KompSchutz 0;
BA_ "GenSigSwitchedByIgnition" SG_ 2549088371 Info_El_KompSchutz 0;
BA_ "GenSigSendType" SG_ 2549088371 Info_El_Nachlauftyp 0;
BA_ "GenSigStartValue" SG_ 2549088371 Info_El_Nachlauftyp 2;
BA_ "GenSigSwitchedByIgnition" SG_ 2549088371 Info_El_Nachlauftyp 0;
BA_ "GenSigSendType" SG_ 2549088371 Info_El_Transport_Mode 0;
BA_ "GenSigSwitchedByIgnition" SG_ 2549088371 Info_El_Transport_Mode 0;
BA_ "GenSigSendType" SG_ 2549088371 KN_Info_El_BusKnockOutTimer 0;
BA_ "GenSigStartValue" SG_ 2549088371 KN_Info_El_BusKnockOutTimer 255;
BA_ "GenSigSwitchedByIgnition" SG_ 2549088371 KN_Info_El_BusKnockOutTimer 0;
BA_ "GenSigSendType" SG_ 2549088371 KN_Info_El_DiagPfad 0;
BA_ "GenSigSwitchedByIgnition" SG_ 2549088371 KN_Info_El_DiagPfad 0;
BA_ "GenSigSendType" SG_ 2549088371 NM_Info_El_Lokalaktiv 0;
BA_ "GenSigSwitchedByIgnition" SG_ 2549088371 NM_Info_El_Lokalaktiv 0;
BA_ "GenSigSendType" SG_ 2549088371 NM_Info_El_Subsystemaktiv 0;
BA_ "GenSigSwitchedByIgnition" SG_ 2549088371 NM_Info_El_Subsystemaktiv 0;
BA_ "GenSigSendType" SG_ 2549088371 NM_Info_El_Wakeup 0;
BA_ "NWM-WakeupAllowed" SG_ 2549088371 NM_Info_El_Wakeup 1;
BA_ "GenSigSwitchedByIgnition" SG_ 2549088371 NM_Info_El_Wakeup 0;
BA_ "GenSigSendType" SG_ 2549088420 KN_LSH_DiagPfad 0;
BA_ "GenSigSwitchedByIgnition" SG_ 2549088420 KN_LSH_DiagPfad 0;
BA_ "GenSigSendType" SG_ 2549088420 LSH_Abschaltstufe 0;
BA_ "GenSigSwitchedByIgnition" SG_ 2549088420 LSH_Abschaltstufe 0;
BA_ "GenSigSendType" SG_ 2549088420 LSH_KD_Fehler 0;
BA_ "GenSigSwitchedByIgnition" SG_ 2549088420 LSH_KD_Fehler 0;
BA_ "GenSigSendType" SG_ 2549088420 LSH_KompSchutz 0;
BA_ "GenSigSwitchedByIgnition" SG_ 2549088420 LSH_KompSchutz 0;
BA_ "GenSigSendType" SG_ 2549088420 LSH_Nachlauftyp 0;
BA_ "GenSigStartValue" SG_ 2549088420 LSH_Nachlauftyp 2;
BA_ "GenSigSwitchedByIgnition" SG_ 2549088420 LSH_Nachlauftyp 0;
BA_ "GenSigSendType" SG_ 2549088420 LSH_Transport_Mode 0;
BA_ "GenSigSwitchedByIgnition" SG_ 2549088420 LSH_Transport_Mode 0;
BA_ "GenSigSendType" SG_ 2549088420 NM_LSH_Wakeup 0;
BA_ "GenSigSwitchedByIgnition" SG_ 2549088420 NM_LSH_Wakeup 0;
BA_ "GenSigSendType" SG_ 2549088267 KN_RDK_BusKnockOut 0;
BA_ "GenSigSwitchedByIgnition" SG_ 2549088267 KN_RDK_BusKnockOut 0;
BA_ "GenSigSendType" SG_ 2549088267 KN_RDK_BusKnockOutTimer 0;
BA_ "GenSigSwitchedByIgnition" SG_ 2549088267 KN_RDK_BusKnockOutTimer 0;
BA_ "GenSigSendType" SG_ 2549088267 KN_RDK_DiagPfad 0;
BA_ "GenSigSwitchedByIgnition" SG_ 2549088267 KN_RDK_DiagPfad 0;
BA_ "GenSigSendType" SG_ 2549088267 KN_RDK_ECUKnockOut 0;
BA_ "GenSigSwitchedByIgnition" SG_ 2549088267 KN_RDK_ECUKnockOut 0;
BA_ "GenSigSendType" SG_ 2549088267 KN_RDK_ECUKnockOutTimer 0;
BA_ "GenSigSwitchedByIgnition" SG_ 2549088267 KN_RDK_ECUKnockOutTimer 0;
BA_ "GenSigSendType" SG_ 2549088267 NM_RDK_Wakeup 0;
BA_ "NWM-WakeupAllowed" SG_ 2549088267 NM_RDK_Wakeup 1;
BA_ "GenSigSwitchedByIgnition" SG_ 2549088267 NM_RDK_Wakeup 0;
BA_ "GenSigSendType" SG_ 2549088267 RDK_Abschaltstufe 0;
BA_ "GenSigSwitchedByIgnition" SG_ 2549088267 RDK_Abschaltstufe 0;
BA_ "GenSigSendType" SG_ 2549088267 RDK_KD_Fehler 0;
BA_ "GenSigSwitchedByIgnition" SG_ 2549088267 RDK_KD_Fehler 0;
BA_ "GenSigSendType" SG_ 2549088267 RDK_KompSchutz 0;
BA_ "GenSigSwitchedByIgnition" SG_ 2549088267 RDK_KompSchutz 0;
BA_ "GenSigSendType" SG_ 2549088267 RDK_Nachlauftyp 0;
BA_ "GenSigStartValue" SG_ 2549088267 RDK_Nachlauftyp 2;
BA_ "GenSigSwitchedByIgnition" SG_ 2549088267 RDK_Nachlauftyp 0;
BA_ "GenSigSendType" SG_ 2549088267 RDK_Transport_Mode 0;
BA_ "GenSigSwitchedByIgnition" SG_ 2549088267 RDK_Transport_Mode 0;
BA_ "GenSigSendType" SG_ 2549088362 KN_STH_BusKnockOutTimer 0;
BA_ "GenSigSwitchedByIgnition" SG_ 2549088362 KN_STH_BusKnockOutTimer 0;
BA_ "GenSigSendType" SG_ 2549088362 KN_STH_DiagPfad 0;
BA_ "GenSigSwitchedByIgnition" SG_ 2549088362 KN_STH_DiagPfad 0;
BA_ "GenSigSendType" SG_ 2549088362 NM_STH_Wakeup 0;
BA_ "NWM-WakeupAllowed" SG_ 2549088362 NM_STH_Wakeup 1;
BA_ "GenSigSendType" SG_ 2549088362 NMH_STH_Lokalaktiv 0;
BA_ "GenSigSwitchedByIgnition" SG_ 2549088362 NMH_STH_Lokalaktiv 0;
BA_ "GenSigSendType" SG_ 2549088362 NMH_STH_Subsystemaktiv 0;
BA_ "GenSigSwitchedByIgnition" SG_ 2549088362 NMH_STH_Subsystemaktiv 0;
BA_ "GenSigSendType" SG_ 2549088362 STH_Abschaltstufe 0;
BA_ "GenSigSwitchedByIgnition" SG_ 2549088362 STH_Abschaltstufe 0;
BA_ "GenSigSendType" SG_ 2549088362 STH_KD_Fehler 0;
BA_ "GenSigSwitchedByIgnition" SG_ 2549088362 STH_KD_Fehler 0;
BA_ "GenSigSendType" SG_ 2549088362 STH_KompSchutz 0;
BA_ "GenSigSwitchedByIgnition" SG_ 2549088362 STH_KompSchutz 0;
BA_ "GenSigSendType" SG_ 2549088362 STH_Nachlauftyp 0;
BA_ "GenSigStartValue" SG_ 2549088362 STH_Nachlauftyp 2;
BA_ "GenSigSwitchedByIgnition" SG_ 2549088362 STH_Nachlauftyp 0;
BA_ "GenSigSendType" SG_ 2549088362 STH_Transport_Mode 0;
BA_ "GenSigSwitchedByIgnition" SG_ 2549088362 STH_Transport_Mode 0;
BA_ "GenSigSendType" SG_ 779 KBI_ABS_Lampe 0;
BA_ "GenSigSwitchedByIgnition" SG_ 779 KBI_ABS_Lampe 0;
BA_ "GenSigSendType" SG_ 779 KBI_Airbag_Lampe 0;
BA_ "GenSigSwitchedByIgnition" SG_ 779 KBI_Airbag_Lampe 0;
BA_ "GenSigSendType" SG_ 779 KBI_angez_Geschw 0;
BA_ "GenSigSwitchedByIgnition" SG_ 779 KBI_angez_Geschw 0;
BA_ "GenSigSendType" SG_ 779 KBI_Anzeigefehler_LDW 0;
BA_ "GenSigSwitchedByIgnition" SG_ 779 KBI_Anzeigefehler_LDW 0;
BA_ "GenSigSendType" SG_ 779 KBI_Anzeigefehler_NV 0;
BA_ "GenSigSwitchedByIgnition" SG_ 779 KBI_Anzeigefehler_NV 0;
BA_ "GenSigSendType" SG_ 779 KBI_Anzeigefehler_SWA 0;
BA_ "GenSigSwitchedByIgnition" SG_ 779 KBI_Anzeigefehler_SWA 0;
BA_ "GenSigSendType" SG_ 779 KBI_Anzeigestatus_ACC 0;
BA_ "GenSigSwitchedByIgnition" SG_ 779 KBI_Anzeigestatus_ACC 0;
BA_ "GenSigSendType" SG_ 779 KBI_Anzeigestatus_GRA 0;
BA_ "GenSigSwitchedByIgnition" SG_ 779 KBI_Anzeigestatus_GRA 0;
BA_ "Fehlerwert" SG_ 779 KBI_Anzeigestatus_GRA 3;
BA_ "GenSigSendType" SG_ 779 KBI_Anzeigestatus_LIM 0;
BA_ "GenSigSwitchedByIgnition" SG_ 779 KBI_Anzeigestatus_LIM 0;
BA_ "Fehlerwert" SG_ 779 KBI_Anzeigestatus_LIM 3;
BA_ "GenSigSendType" SG_ 779 KBI_Anzeigestatus_RHP 0;
BA_ "GenSigSwitchedByIgnition" SG_ 779 KBI_Anzeigestatus_RHP 0;
BA_ "GenSigSendType" SG_ 779 KBI_ARA_in_Anzeige 0;
BA_ "GenSigSwitchedByIgnition" SG_ 779 KBI_ARA_in_Anzeige 0;
BA_ "GenSigSendType" SG_ 779 KBI_Audioabsenkung_MIB 0;
BA_ "GenSigSwitchedByIgnition" SG_ 779 KBI_Audioabsenkung_MIB 0;
BA_ "GenSigSendType" SG_ 779 KBI_Bestaetigung_ESP_Off 0;
BA_ "GenSigSwitchedByIgnition" SG_ 779 KBI_Bestaetigung_ESP_Off 0;
BA_ "GenSigSendType" SG_ 779 KBI_BKL_Lampe 0;
BA_ "GenSigSwitchedByIgnition" SG_ 779 KBI_BKL_Lampe 0;
BA_ "GenSigSendType" SG_ 779 KBI_ESP_Lampe 0;
BA_ "GenSigSwitchedByIgnition" SG_ 779 KBI_ESP_Lampe 0;
BA_ "GenSigSendType" SG_ 779 KBI_Fehler_Anzeige_ACC 0;
BA_ "GenSigSwitchedByIgnition" SG_ 779 KBI_Fehler_Anzeige_ACC 0;
BA_ "GenSigSendType" SG_ 779 KBI_Handbremse 0;
BA_ "GenSigSwitchedByIgnition" SG_ 779 KBI_Handbremse 0;
BA_ "GenSigSendType" SG_ 779 KBI_im_Stellgliedtest 0;
BA_ "GenSigSwitchedByIgnition" SG_ 779 KBI_im_Stellgliedtest 0;
BA_ "GenSigSendType" SG_ 779 KBI_Konsistenz_ACC 0;
BA_ "GenSigSwitchedByIgnition" SG_ 779 KBI_Konsistenz_ACC 0;
BA_ "GenSigSendType" SG_ 779 KBI_Lenkung_Lampe 0;
BA_ "GenSigSwitchedByIgnition" SG_ 779 KBI_Lenkung_Lampe 0;
BA_ "GenSigSendType" SG_ 779 KBI_MFA_v_Einheit_01 0;
BA_ "GenSigSwitchedByIgnition" SG_ 779 KBI_MFA_v_Einheit_01 0;
BA_ "GenSigSendType" SG_ 779 KBI_NV_in_Anzeige 0;
BA_ "GenSigSwitchedByIgnition" SG_ 779 KBI_NV_in_Anzeige 0;
BA_ "GenSigSendType" SG_ 779 KBI_Oeldruck_Schalter 0;
BA_ "GenSigSwitchedByIgnition" SG_ 779 KBI_Oeldruck_Schalter 0;
BA_ "GenSigSendType" SG_ 779 KBI_Oeldruckwarnung 0;
BA_ "GenSigSwitchedByIgnition" SG_ 779 KBI_Oeldruckwarnung 0;
BA_ "GenSigSendType" SG_ 779 KBI_PLA_in_Anzeige 0;
BA_ "GenSigSwitchedByIgnition" SG_ 779 KBI_PLA_in_Anzeige 0;
BA_ "GenSigSendType" SG_ 779 KBI_SILA_gueltig 0;
BA_ "GenSigSwitchedByIgnition" SG_ 779 KBI_SILA_gueltig 0;
BA_ "GenSigSendType" SG_ 779 KBI_Systemstatus 0;
BA_ "GenSigSwitchedByIgnition" SG_ 779 KBI_Systemstatus 0;
BA_ "GenSigSendType" SG_ 779 KBI_Tankwarnung 0;
BA_ "GenSigSwitchedByIgnition" SG_ 779 KBI_Tankwarnung 0;
BA_ "GenSigSendType" SG_ 779 KBI_Tankwarnung_ungueltig 0;
BA_ "GenSigStartValue" SG_ 779 KBI_Tankwarnung_ungueltig 1;
BA_ "GenSigSwitchedByIgnition" SG_ 779 KBI_Tankwarnung_ungueltig 0;
BA_ "GenSigSendType" SG_ 779 KBI_Taster_Fahrwerk 0;
BA_ "GenSigSwitchedByIgnition" SG_ 779 KBI_Taster_Fahrwerk 0;
BA_ "GenSigSendType" SG_ 779 KBI_Taster_Lift 0;
BA_ "GenSigSwitchedByIgnition" SG_ 779 KBI_Taster_Lift 0;
BA_ "GenSigSendType" SG_ 779 KBI_V_Digital 0;
BA_ "GenSigSwitchedByIgnition" SG_ 779 KBI_V_Digital 0;
BA_ "GenSigSendType" SG_ 779 KBI_Vorglueh_System_Lampe 0;
BA_ "GenSigSwitchedByIgnition" SG_ 779 KBI_Vorglueh_System_Lampe 0;
BA_ "GenSigSendType" SG_ 779 Kombi_01_BZ 0;
BA_ "GenSigFuncType" SG_ 779 Kombi_01_BZ 1;
BA_ "GenSigSwitchedByIgnition" SG_ 779 Kombi_01_BZ 0;
BA_ "GenSigSendType" SG_ 1719 KBI_aktive_Laengsfunktion_02 3;
BA_ "GenSigSendType" SG_ 1719 KBI_Aussen_Temp_gef 0;
BA_ "GenSigStartValue" SG_ 1719 KBI_Aussen_Temp_gef 254;
BA_ "GenSigSwitchedByIgnition" SG_ 1719 KBI_Aussen_Temp_gef 0;
BA_ "Fehlerwert" SG_ 1719 KBI_Aussen_Temp_gef 255;
BA_ "GenSigSendType" SG_ 1719 KBI_FoD_PopUP_Quittiert 3;
BA_ "GenSigSendType" SG_ 1719 KBI_FStatus_Tank 0;
BA_ "GenSigSwitchedByIgnition" SG_ 1719 KBI_FStatus_Tank 0;
BA_ "GenSigSendType" SG_ 1719 KBI_GRA_im_ACC 3;
BA_ "GenSigSwitchedByIgnition" SG_ 1719 KBI_GRA_im_ACC 0;
BA_ "GenSigSendType" SG_ 1719 KBI_Inhalt_Tank 0;
BA_ "GenSigStartValue" SG_ 1719 KBI_Inhalt_Tank 126;
BA_ "GenSigSwitchedByIgnition" SG_ 1719 KBI_Inhalt_Tank 0;
BA_ "Fehlerwert" SG_ 1719 KBI_Inhalt_Tank 127;
BA_ "GenSigSendType" SG_ 1719 KBI_Kilometerstand 0;
BA_ "GenSigStartValue" SG_ 1719 KBI_Kilometerstand 1048574;
BA_ "GenSigSwitchedByIgnition" SG_ 1719 KBI_Kilometerstand 0;
BA_ "Fehlerwert" SG_ 1719 KBI_Kilometerstand 1048575;
BA_ "GenSigSendType" SG_ 1719 KBI_Oelwechsel_durchgefuehrt 0;
BA_ "GenSigSwitchedByIgnition" SG_ 1719 KBI_Oelwechsel_durchgefuehrt 0;
BA_ "GenSigSendType" SG_ 1719 KBI_QBit_Aussen_Temp_gef 0;
BA_ "GenSigStartValue" SG_ 1719 KBI_QBit_Aussen_Temp_gef 1;
BA_ "GenSigSwitchedByIgnition" SG_ 1719 KBI_QBit_Aussen_Temp_gef 0;
BA_ "GenSigSendType" SG_ 1719 KBI_RDK_Kalibrier_Anf 3;
BA_ "GenSigSwitchedByIgnition" SG_ 1719 KBI_RDK_Kalibrier_Anf 0;
BA_ "GenSigSendType" SG_ 1719 KBI_Reserve_Warnung_Sek 3;
BA_ "GenSigSwitchedByIgnition" SG_ 1719 KBI_Reserve_Warnung_Sek 0;
BA_ "GenSigSendType" SG_ 1719 KBI_Standzeit_02 0;
BA_ "GenSigStartValue" SG_ 1719 KBI_Standzeit_02 131070;
BA_ "GenSigSwitchedByIgnition" SG_ 1719 KBI_Standzeit_02 0;
BA_ "Fehlerwert" SG_ 1719 KBI_Standzeit_02 131071;
BA_ "GenSigSendType" SG_ 1720 KBI_BCmE_aktiv 0;
BA_ "GenSigSwitchedByIgnition" SG_ 1720 KBI_BCmE_aktiv 0;
BA_ "GenSigSendType" SG_ 1720 KBI_GAP_Warn_Zeit_abgelaufen 0;
BA_ "GenSigSwitchedByIgnition" SG_ 1720 KBI_GAP_Warn_Zeit_abgelaufen 0;
BA_ "GenSigSendType" SG_ 1720 KBI_Max_Tankinhalt 0;
BA_ "GenSigStartValue" SG_ 1720 KBI_Max_Tankinhalt 254;
BA_ "GenSigSwitchedByIgnition" SG_ 1720 KBI_Max_Tankinhalt 0;
BA_ "Fehlerwert" SG_ 1720 KBI_Max_Tankinhalt 255;
BA_ "GenSigSendType" SG_ 1720 KBI_Nachtanken_erkannt 0;
BA_ "GenSigSwitchedByIgnition" SG_ 1720 KBI_Nachtanken_erkannt 0;
BA_ "GenSigSendType" SG_ 1720 KBI_Quittierung_cAQP 0;
BA_ "GenSigSwitchedByIgnition" SG_ 1720 KBI_Quittierung_cAQP 0;
BA_ "GenSigSendType" SG_ 1720 KBI_Quittierung_Naesse 0;
BA_ "GenSigSwitchedByIgnition" SG_ 1720 KBI_Quittierung_Naesse 0;
BA_ "GenSigSendType" SG_ 1720 KBI_Reifenumfang 0;
BA_ "GenSigFuncType" SG_ 1720 KBI_Reifenumfang 8;
BA_ "GenSigSwitchedByIgnition" SG_ 1720 KBI_Reifenumfang 0;
BA_ "GenSigSendType" SG_ 1720 KBI_Reifenumfang_Sekundaer 0;
BA_ "GenSigSwitchedByIgnition" SG_ 1720 KBI_Reifenumfang_Sekundaer 0;
BA_ "GenSigSendType" SG_ 1720 KBI_Sparhinweis_quittiert 0;
BA_ "GenSigSwitchedByIgnition" SG_ 1720 KBI_Sparhinweis_quittiert 0;
BA_ "GenSigSendType" SG_ 1720 KBI_Tankfuellstand_Prozent 0;
BA_ "GenSigStartValue" SG_ 1720 KBI_Tankfuellstand_Prozent 126;
BA_ "GenSigSwitchedByIgnition" SG_ 1720 KBI_Tankfuellstand_Prozent 0;
BA_ "Fehlerwert" SG_ 1720 KBI_Tankfuellstand_Prozent 127;
BA_ "GenSigSendType" SG_ 1720 KBI_Tankinhalt_hochaufl 0;
BA_ "GenSigStartValue" SG_ 1720 KBI_Tankinhalt_hochaufl 16382;
BA_ "GenSigSwitchedByIgnition" SG_ 1720 KBI_Tankinhalt_hochaufl 0;
BA_ "Fehlerwert" SG_ 1720 KBI_Tankinhalt_hochaufl 16383;
BA_ "GenSigSendType" SG_ 1720 KBI_Variante 0;
BA_ "GenSigSwitchedByIgnition" SG_ 1720 KBI_Variante 0;
BA_ "GenSigSendType" SG_ 1720 KBI_Variante_USA 0;
BA_ "GenSigSwitchedByIgnition" SG_ 1720 KBI_Variante_USA 0;
BA_ "GenSigSendType" SG_ 2527679639 AuthTime_Trigger_Distribution 4;
BA_ "GenSigSwitchedByIgnition" SG_ 2527679639 AuthTime_Trigger_Distribution 0;
BA_ "GenSigSendType" SG_ 2527679639 KBI_Anzeige_ID_quittiert 5;
BA_ "GenSigSwitchedByIgnition" SG_ 2527679639 KBI_Anzeige_ID_quittiert 0;
BA_ "GenSigSendType" SG_ 2527679639 KBI_FoD_VirtualCockpitPlus_State 3;
BA_ "GenSigSwitchedByIgnition" SG_ 2527679639 KBI_FoD_VirtualCockpitPlus_State 0;
BA_ "GenSigSendType" SG_ 2527679639 KBI_Jokerkey 3;
BA_ "GenSigSwitchedByIgnition" SG_ 2527679639 KBI_Jokerkey 0;
BA_ "GenSigSendType" SG_ 2527679639 KBI_Min_Tankinhalt 0;
BA_ "GenSigStartValue" SG_ 2527679639 KBI_Min_Tankinhalt 126;
BA_ "GenSigSwitchedByIgnition" SG_ 2527679639 KBI_Min_Tankinhalt 0;
BA_ "Fehlerwert" SG_ 2527679639 KBI_Min_Tankinhalt 127;
BA_ "GenSigSendType" SG_ 2527679639 KBI_RS_Druck_uebernehmen 3;
BA_ "GenSigSwitchedByIgnition" SG_ 2527679639 KBI_RS_Druck_uebernehmen 0;
BA_ "GenSigSendType" SG_ 2527679639 KBI_RS_Druckauswahl_Aktiv 3;
BA_ "GenSigSwitchedByIgnition" SG_ 2527679639 KBI_RS_Druckauswahl_Aktiv 0;
BA_ "GenSigSendType" SG_ 2527679639 KBI_RS_Mode_fortsetzen 3;
BA_ "GenSigSwitchedByIgnition" SG_ 2527679639 KBI_RS_Mode_fortsetzen 0;
BA_ "GenSigSendType" SG_ 2527679639 KBI_Rundstreckenmodus 3;
BA_ "GenSigSwitchedByIgnition" SG_ 2527679639 KBI_Rundstreckenmodus 0;
BA_ "GenSigSendType" SG_ 2527679639 KBI_Weg_Zaehler 3;
BA_ "GenSigSwitchedByIgnition" SG_ 2527679639 KBI_Weg_Zaehler 0;
BA_ "GenSigSendType" SG_ 2527679639 KBI_Weg_Zaehler_F 3;
BA_ "GenSigSwitchedByIgnition" SG_ 2527679639 KBI_Weg_Zaehler_F 0;
BA_ "Fehlerwert" SG_ 2527679639 KBI_Weg_Zaehler_F 1;
BA_ "GenSigSendType" SG_ 2527679656 KBI_StartupAnimation 3;
BA_ "GenSigSwitchedByIgnition" SG_ 2527679656 KBI_StartupAnimation 0;
BA_ "GenSigSendType" SG_ 2589283935 KBI_Curr_View 4;
BA_ "GenSigSwitchedByIgnition" SG_ 2589283935 KBI_Curr_View 0;
BA_ "GenSigSendType" SG_ 2589283935 KBI_Sec_View_Status 4;
BA_ "GenSigSwitchedByIgnition" SG_ 2589283935 KBI_Sec_View_Status 0;
BA_ "GenSigSendType" SG_ 2589283935 KBI_View1 0;
BA_ "GenSigSwitchedByIgnition" SG_ 2589283935 KBI_View1 0;
BA_ "GenSigSendType" SG_ 2589283935 KBI_View10 0;
BA_ "GenSigSwitchedByIgnition" SG_ 2589283935 KBI_View10 0;
BA_ "GenSigSendType" SG_ 2589283935 KBI_View11 0;
BA_ "GenSigSwitchedByIgnition" SG_ 2589283935 KBI_View11 0;
BA_ "GenSigSendType" SG_ 2589283935 KBI_View12 0;
BA_ "GenSigSwitchedByIgnition" SG_ 2589283935 KBI_View12 0;
BA_ "GenSigSendType" SG_ 2589283935 KBI_View13 0;
BA_ "GenSigSwitchedByIgnition" SG_ 2589283935 KBI_View13 0;
BA_ "GenSigSendType" SG_ 2589283935 KBI_View14 0;
BA_ "GenSigSwitchedByIgnition" SG_ 2589283935 KBI_View14 0;
BA_ "GenSigSendType" SG_ 2589283935 KBI_View15 0;
BA_ "GenSigSwitchedByIgnition" SG_ 2589283935 KBI_View15 0;
BA_ "GenSigSendType" SG_ 2589283935 KBI_View16 0;
BA_ "GenSigSwitchedByIgnition" SG_ 2589283935 KBI_View16 0;
BA_ "GenSigSendType" SG_ 2589283935 KBI_View17 0;
BA_ "GenSigSwitchedByIgnition" SG_ 2589283935 KBI_View17 0;
BA_ "GenSigSendType" SG_ 2589283935 KBI_View18 0;
BA_ "GenSigSwitchedByIgnition" SG_ 2589283935 KBI_View18 0;
BA_ "GenSigSendType" SG_ 2589283935 KBI_View19 0;
BA_ "GenSigSwitchedByIgnition" SG_ 2589283935 KBI_View19 0;
BA_ "GenSigSendType" SG_ 2589283935 KBI_View2 0;
BA_ "GenSigSwitchedByIgnition" SG_ 2589283935 KBI_View2 0;
BA_ "GenSigSendType" SG_ 2589283935 KBI_View20 0;
BA_ "GenSigSwitchedByIgnition" SG_ 2589283935 KBI_View20 0;
BA_ "GenSigSendType" SG_ 2589283935 KBI_View21 0;
BA_ "GenSigSwitchedByIgnition" SG_ 2589283935 KBI_View21 0;
BA_ "GenSigSendType" SG_ 2589283935 KBI_View22 0;
BA_ "GenSigSwitchedByIgnition" SG_ 2589283935 KBI_View22 0;
BA_ "GenSigSendType" SG_ 2589283935 KBI_View23 0;
BA_ "GenSigSwitchedByIgnition" SG_ 2589283935 KBI_View23 0;
BA_ "GenSigSendType" SG_ 2589283935 KBI_View24 0;
BA_ "GenSigSwitchedByIgnition" SG_ 2589283935 KBI_View24 0;
BA_ "GenSigSendType" SG_ 2589283935 KBI_View3 0;
BA_ "GenSigSwitchedByIgnition" SG_ 2589283935 KBI_View3 0;
BA_ "GenSigSendType" SG_ 2589283935 KBI_View4 0;
BA_ "GenSigSwitchedByIgnition" SG_ 2589283935 KBI_View4 0;
BA_ "GenSigSendType" SG_ 2589283935 KBI_View5 0;
BA_ "GenSigSwitchedByIgnition" SG_ 2589283935 KBI_View5 0;
BA_ "GenSigSendType" SG_ 2589283935 KBI_View6 0;
BA_ "GenSigSwitchedByIgnition" SG_ 2589283935 KBI_View6 0;
BA_ "GenSigSendType" SG_ 2589283935 KBI_View7 0;
BA_ "GenSigSwitchedByIgnition" SG_ 2589283935 KBI_View7 0;
BA_ "GenSigSendType" SG_ 2589283935 KBI_View8 0;
BA_ "GenSigSwitchedByIgnition" SG_ 2589283935 KBI_View8 0;
BA_ "GenSigSendType" SG_ 2589283935 KBI_View9 0;
BA_ "GenSigSwitchedByIgnition" SG_ 2589283935 KBI_View9 0;
BA_ "GenSigSendType" SG_ 2550399240 KS_ICAS3Sys01_Req_Data 3;
BA_ "GenSigFuncType" SG_ 2550399240 KS_ICAS3Sys01_Req_Data 9;
BA_ "GenSigSwitchedByIgnition" SG_ 2550399240 KS_ICAS3Sys01_Req_Data 0;
BA_ "GenSigSendType" SG_ 2550530312 KS_ICAS3Sys01_Resp_Data 3;
BA_ "GenSigFuncType" SG_ 2550530312 KS_ICAS3Sys01_Resp_Data 9;
BA_ "GenSigSwitchedByIgnition" SG_ 2550530312 KS_ICAS3Sys01_Resp_Data 0;
BA_ "GenSigSendType" SG_ 2549875059 KS_Info_El_Req_Data 3;
BA_ "GenSigFuncType" SG_ 2549875059 KS_Info_El_Req_Data 9;
BA_ "GenSigSwitchedByIgnition" SG_ 2549875059 KS_Info_El_Req_Data 0;
BA_ "GenSigSendType" SG_ 2550006131 KS_Info_El_Resp_Data 3;
BA_ "GenSigFuncType" SG_ 2550006131 KS_Info_El_Resp_Data 9;
BA_ "GenSigSwitchedByIgnition" SG_ 2550006131 KS_Info_El_Resp_Data 0;
BA_ "GenSigSendType" SG_ 2549899278 KS_SSN_ABT_1_Req_Data 3;
BA_ "GenSigFuncType" SG_ 2549899278 KS_SSN_ABT_1_Req_Data 9;
BA_ "GenSigSwitchedByIgnition" SG_ 2549899278 KS_SSN_ABT_1_Req_Data 0;
BA_ "GenSigSendType" SG_ 2550030350 KS_SSN_ABT_1_Resp_Data 3;
BA_ "GenSigFuncType" SG_ 2550030350 KS_SSN_ABT_1_Resp_Data 9;
BA_ "GenSigSwitchedByIgnition" SG_ 2550030350 KS_SSN_ABT_1_Resp_Data 0;
BA_ "GenSigSendType" SG_ 2549875053 KS_TV_Tuner_Req_Data 3;
BA_ "GenSigFuncType" SG_ 2549875053 KS_TV_Tuner_Req_Data 9;
BA_ "GenSigSwitchedByIgnition" SG_ 2549875053 KS_TV_Tuner_Req_Data 0;
BA_ "GenSigSendType" SG_ 2550006125 KS_TV_Tuner_Resp_Data 3;
BA_ "GenSigFuncType" SG_ 2550006125 KS_TV_Tuner_Resp_Data 9;
BA_ "GenSigSwitchedByIgnition" SG_ 2550006125 KS_TV_Tuner_Resp_Data 0;
BA_ "GenSigSendType" SG_ 110 EPS_QBit_Zahnstangen_Grad 0;
BA_ "GenSigStartValue" SG_ 110 EPS_QBit_Zahnstangen_Grad 1;
BA_ "GenSigSwitchedByIgnition" SG_ 110 EPS_QBit_Zahnstangen_Grad 0;
BA_ "GenSigSendType" SG_ 110 EPS_QBit_Zahnstangen_Pos 0;
BA_ "GenSigSwitchedByIgnition" SG_ 110 EPS_QBit_Zahnstangen_Pos 0;
BA_ "GenSigSendType" SG_ 110 EPS_Sensorikstatus 0;
BA_ "GenSigSwitchedByIgnition" SG_ 110 EPS_Sensorikstatus 0;
BA_ "GenSigSendType" SG_ 110 EPS_VZ_Zahnstangen_Grad 0;
BA_ "GenSigSwitchedByIgnition" SG_ 110 EPS_VZ_Zahnstangen_Grad 0;
BA_ "GenSigSendType" SG_ 110 EPS_VZ_Zahnstangenposition 0;
BA_ "GenSigSwitchedByIgnition" SG_ 110 EPS_VZ_Zahnstangenposition 0;
BA_ "GenSigSendType" SG_ 110 EPS_Zahnstangen_Grad 0;
BA_ "GenSigSwitchedByIgnition" SG_ 110 EPS_Zahnstangen_Grad 0;
BA_ "Fehlerwert" SG_ 110 EPS_Zahnstangen_Grad 32767;
BA_ "GenSigSendType" SG_ 110 EPS_Zahnstangen_Pos_02 0;
BA_ "GenSigStartValue" SG_ 110 EPS_Zahnstangen_Pos_02 32766;
BA_ "GenSigSwitchedByIgnition" SG_ 110 EPS_Zahnstangen_Pos_02 0;
BA_ "Fehlerwert" SG_ 110 EPS_Zahnstangen_Pos_02 32767;
BA_ "GenSigSendType" SG_ 981 BCM1_Abblendlicht_Anf 0;
BA_ "GenSigSwitchedByIgnition" SG_ 981 BCM1_Abblendlicht_Anf 0;
BA_ "GenSigSendType" SG_ 981 BCM1_Adaptive_Lichtvert_Anf 0;
BA_ "GenSigSwitchedByIgnition" SG_ 981 BCM1_Adaptive_Lichtvert_Anf 0;
BA_ "GenSigSendType" SG_ 981 BCM1_Allwetterlicht_Anf 0;
BA_ "GenSigSwitchedByIgnition" SG_ 981 BCM1_Allwetterlicht_Anf 0;
BA_ "GenSigSendType" SG_ 981 BCM1_Animationssperrung 3;
BA_ "GenSigStartValue" SG_ 981 BCM1_Animationssperrung 1;
BA_ "GenSigSwitchedByIgnition" SG_ 981 BCM1_Animationssperrung 0;
BA_ "GenSigSendType" SG_ 981 BCM1_Autobahnlicht_Anf 0;
BA_ "GenSigSwitchedByIgnition" SG_ 981 BCM1_Autobahnlicht_Anf 0;
BA_ "GenSigSendType" SG_ 981 BCM1_CH_aktiv 0;
BA_ "NWM-WakeupAllowed" SG_ 981 BCM1_CH_aktiv 1;
BA_ "GenSigSwitchedByIgnition" SG_ 981 BCM1_CH_aktiv 0;
BA_ "GenSigSendType" SG_ 981 BCM1_CH_LH_aktiv 0;
BA_ "GenSigSwitchedByIgnition" SG_ 981 BCM1_CH_LH_aktiv 0;
BA_ "GenSigSendType" SG_ 981 BCM1_Fernlicht_Anf 0;
BA_ "GenSigSwitchedByIgnition" SG_ 981 BCM1_Fernlicht_Anf 0;
BA_ "GenSigSendType" SG_ 981 BCM1_Gleitende_Leuchtw_Anf 0;
BA_ "GenSigSwitchedByIgnition" SG_ 981 BCM1_Gleitende_Leuchtw_Anf 0;
BA_ "GenSigSendType" SG_ 981 BCM1_GLW_Fernlicht_Anf 3;
BA_ "GenSigSwitchedByIgnition" SG_ 981 BCM1_GLW_Fernlicht_Anf 0;
BA_ "GenSigSendType" SG_ 981 BCM1_Kurvenlicht_links_Anf 0;
BA_ "GenSigSwitchedByIgnition" SG_ 981 BCM1_Kurvenlicht_links_Anf 0;
BA_ "GenSigSendType" SG_ 981 BCM1_Kurvenlicht_rechts_Anf 0;
BA_ "GenSigSwitchedByIgnition" SG_ 981 BCM1_Kurvenlicht_rechts_Anf 0;
BA_ "GenSigSendType" SG_ 981 BCM1_LH_aktiv 0;
BA_ "NWM-WakeupAllowed" SG_ 981 BCM1_LH_aktiv 1;
BA_ "GenSigSwitchedByIgnition" SG_ 981 BCM1_LH_aktiv 0;
BA_ "GenSigSendType" SG_ 981 BCM1_Nebellicht_Anf 0;
BA_ "GenSigSwitchedByIgnition" SG_ 981 BCM1_Nebellicht_Anf 0;
BA_ "GenSigSendType" SG_ 981 BCM1_Nebelschluss_Ahg_Anf 0;
BA_ "GenSigSwitchedByIgnition" SG_ 981 BCM1_Nebelschluss_Ahg_Anf 0;
BA_ "GenSigSendType" SG_ 981 BCM1_Nebelschluss_Fzg_Anf 0;
BA_ "GenSigSwitchedByIgnition" SG_ 981 BCM1_Nebelschluss_Fzg_Anf 0;
BA_ "GenSigSendType" SG_ 981 BCM1_Parklicht_li_Anf 0;
BA_ "GenSigSwitchedByIgnition" SG_ 981 BCM1_Parklicht_li_Anf 0;
BA_ "GenSigSendType" SG_ 981 BCM1_Parklicht_re_Anf 0;
BA_ "GenSigSwitchedByIgnition" SG_ 981 BCM1_Parklicht_re_Anf 0;
BA_ "GenSigSendType" SG_ 981 BCM1_Regenlicht_Anf 0;
BA_ "GenSigSwitchedByIgnition" SG_ 981 BCM1_Regenlicht_Anf 0;
BA_ "GenSigSendType" SG_ 981 BCM1_Schlusslicht_Anf 0;
BA_ "GenSigSwitchedByIgnition" SG_ 981 BCM1_Schlusslicht_Anf 0;
BA_ "GenSigSendType" SG_ 981 BCM1_Signaturlicht_Anf 0;
BA_ "GenSigSwitchedByIgnition" SG_ 981 BCM1_Signaturlicht_Anf 0;
BA_ "GenSigSendType" SG_ 981 BCM1_Standlicht_Anf 0;
BA_ "GenSigSwitchedByIgnition" SG_ 981 BCM1_Standlicht_Anf 0;
BA_ "GenSigSendType" SG_ 981 BCM1_Tagfahrlicht_Anf 0;
BA_ "GenSigSwitchedByIgnition" SG_ 981 BCM1_Tagfahrlicht_Anf 0;
BA_ "GenSigSendType" SG_ 981 BCM1_Touristen_Licht_Anf 0;
BA_ "GenSigSwitchedByIgnition" SG_ 981 BCM1_Touristen_Licht_Anf 0;
BA_ "GenSigSendType" SG_ 981 BCM1_Umfeldleuchten_Anf 0;
BA_ "GenSigSwitchedByIgnition" SG_ 981 BCM1_Umfeldleuchten_Anf 0;
BA_ "GenSigSendType" SG_ 981 BCM_Rueckfahrlicht_Anf 0;
BA_ "GenSigSwitchedByIgnition" SG_ 981 BCM_Rueckfahrlicht_Anf 0;
BA_ "GenSigSendType" SG_ 981 Licht_Anf_01_BZ 0;
BA_ "GenSigFuncType" SG_ 981 Licht_Anf_01_BZ 1;
BA_ "GenSigSwitchedByIgnition" SG_ 981 Licht_Anf_01_BZ 0;
BA_ "GenSigSendType" SG_ 981 Licht_Anf_01_CRC 0;
BA_ "GenSigFuncType" SG_ 981 Licht_Anf_01_CRC 2;
BA_ "GenSigSwitchedByIgnition" SG_ 981 Licht_Anf_01_CRC 0;
BA_ "GenSigSendType" SG_ 981 TFL_Matrix_Variante01_Anf 3;
BA_ "GenSigSendType" SG_ 981 TFL_Matrix_Variante02_Anf 3;
BA_ "GenSigSendType" SG_ 981 TFL_Matrix_Variante03_Anf 3;
BA_ "GenSigSendType" SG_ 981 TFL_Matrix_Variante04_Anf 3;
BA_ "GenSigSendType" SG_ 982 BCM2_Bremsl_durch_ECD 0;
BA_ "GenSigSwitchedByIgnition" SG_ 982 BCM2_Bremsl_durch_ECD 0;
BA_ "GenSigSendType" SG_ 982 BCM2_Bremsl_durch_ECD_invers 0;
BA_ "GenSigStartValue" SG_ 982 BCM2_Bremsl_durch_ECD_invers 1;
BA_ "GenSigSwitchedByIgnition" SG_ 982 BCM2_Bremsl_durch_ECD_invers 0;
BA_ "GenSigSendType" SG_ 982 LH_3_Bremsl_def 0;
BA_ "GenSigSwitchedByIgnition" SG_ 982 LH_3_Bremsl_def 0;
BA_ "GenSigSendType" SG_ 982 LH_Aussenlicht_def 0;
BA_ "GenSigSwitchedByIgnition" SG_ 982 LH_Aussenlicht_def 0;
BA_ "GenSigSendType" SG_ 982 LH_Blinker_HL_akt 0;
BA_ "GenSigSwitchedByIgnition" SG_ 982 LH_Blinker_HL_akt 0;
BA_ "GenSigSendType" SG_ 982 LH_Blinker_HR_akt 0;
BA_ "GenSigSwitchedByIgnition" SG_ 982 LH_Blinker_HR_akt 0;
BA_ "GenSigSendType" SG_ 982 LH_Blinker_li_def 0;
BA_ "GenSigSwitchedByIgnition" SG_ 982 LH_Blinker_li_def 0;
BA_ "GenSigSendType" SG_ 982 LH_Blinker_re_def 0;
BA_ "GenSigSwitchedByIgnition" SG_ 982 LH_Blinker_re_def 0;
BA_ "GenSigSendType" SG_ 982 LH_Brems_Blk_li_def 0;
BA_ "GenSigSwitchedByIgnition" SG_ 982 LH_Brems_Blk_li_def 0;
BA_ "GenSigSendType" SG_ 982 LH_Brems_Blk_re_def 0;
BA_ "GenSigSwitchedByIgnition" SG_ 982 LH_Brems_Blk_re_def 0;
BA_ "GenSigSendType" SG_ 982 LH_Bremsl_li_def 0;
BA_ "GenSigSwitchedByIgnition" SG_ 982 LH_Bremsl_li_def 0;
BA_ "GenSigSendType" SG_ 982 LH_Bremsl_li_ges_def 0;
BA_ "GenSigSwitchedByIgnition" SG_ 982 LH_Bremsl_li_ges_def 0;
BA_ "GenSigSendType" SG_ 982 LH_Bremsl_re_def 0;
BA_ "GenSigSwitchedByIgnition" SG_ 982 LH_Bremsl_re_def 0;
BA_ "GenSigSendType" SG_ 982 LH_Bremsl_re_ges_def 0;
BA_ "GenSigSwitchedByIgnition" SG_ 982 LH_Bremsl_re_ges_def 0;
BA_ "GenSigSendType" SG_ 982 LH_Bremslicht_H_aktiv 0;
BA_ "GenSigSwitchedByIgnition" SG_ 982 LH_Bremslicht_H_aktiv 0;
BA_ "GenSigSendType" SG_ 982 LH_Diag_LED_li_def 0;
BA_ "GenSigSwitchedByIgnition" SG_ 982 LH_Diag_LED_li_def 0;
BA_ "GenSigSendType" SG_ 982 LH_Diag_LED_re_def 0;
BA_ "GenSigSwitchedByIgnition" SG_ 982 LH_Diag_LED_re_def 0;
BA_ "GenSigSendType" SG_ 982 LH_Diag_Status_li_def 0;
BA_ "GenSigSwitchedByIgnition" SG_ 982 LH_Diag_Status_li_def 0;
BA_ "GenSigSendType" SG_ 982 LH_Diag_Status_re_def 0;
BA_ "GenSigSwitchedByIgnition" SG_ 982 LH_Diag_Status_re_def 0;
BA_ "GenSigSendType" SG_ 982 LH_Kennzl_def 0;
BA_ "GenSigSwitchedByIgnition" SG_ 982 LH_Kennzl_def 0;
BA_ "GenSigSendType" SG_ 982 LH_Nebel_li_def 0;
BA_ "GenSigSwitchedByIgnition" SG_ 982 LH_Nebel_li_def 0;
BA_ "GenSigSendType" SG_ 982 LH_Nebel_mi_def 0;
BA_ "GenSigSwitchedByIgnition" SG_ 982 LH_Nebel_mi_def 0;
BA_ "GenSigSendType" SG_ 982 LH_Nebel_re_def 0;
BA_ "GenSigSwitchedByIgnition" SG_ 982 LH_Nebel_re_def 0;
BA_ "GenSigSendType" SG_ 982 LH_Nebelschluss_aktiv 0;
BA_ "GenSigSwitchedByIgnition" SG_ 982 LH_Nebelschluss_aktiv 0;
BA_ "GenSigSendType" SG_ 982 LH_Parklicht_HL_aktiv 0;
BA_ "GenSigSwitchedByIgnition" SG_ 982 LH_Parklicht_HL_aktiv 0;
BA_ "GenSigSendType" SG_ 982 LH_Parklicht_HR_aktiv 0;
BA_ "GenSigSwitchedByIgnition" SG_ 982 LH_Parklicht_HR_aktiv 0;
BA_ "GenSigSendType" SG_ 982 LH_Rueckf_li_def 0;
BA_ "GenSigSwitchedByIgnition" SG_ 982 LH_Rueckf_li_def 0;
BA_ "GenSigSendType" SG_ 982 LH_Rueckf_mi_def 0;
BA_ "GenSigSwitchedByIgnition" SG_ 982 LH_Rueckf_mi_def 0;
BA_ "GenSigSendType" SG_ 982 LH_Rueckf_re_def 0;
BA_ "GenSigSwitchedByIgnition" SG_ 982 LH_Rueckf_re_def 0;
BA_ "GenSigSendType" SG_ 982 LH_Rueckfahrlicht_aktiv 0;
BA_ "GenSigSwitchedByIgnition" SG_ 982 LH_Rueckfahrlicht_aktiv 0;
BA_ "GenSigSendType" SG_ 982 LH_Schluss_Brems_li_def 0;
BA_ "GenSigSwitchedByIgnition" SG_ 982 LH_Schluss_Brems_li_def 0;
BA_ "GenSigSendType" SG_ 982 LH_Schluss_Brems_Nebel_li_def 0;
BA_ "GenSigSwitchedByIgnition" SG_ 982 LH_Schluss_Brems_Nebel_li_def 0;
BA_ "GenSigSendType" SG_ 982 LH_Schluss_Brems_Nebel_re_def 0;
BA_ "GenSigSwitchedByIgnition" SG_ 982 LH_Schluss_Brems_Nebel_re_def 0;
BA_ "GenSigSendType" SG_ 982 LH_Schluss_Brems_re_def 0;
BA_ "GenSigSwitchedByIgnition" SG_ 982 LH_Schluss_Brems_re_def 0;
BA_ "GenSigSendType" SG_ 982 LH_Schluss_Nebel_li_def 0;
BA_ "GenSigSwitchedByIgnition" SG_ 982 LH_Schluss_Nebel_li_def 0;
BA_ "GenSigSendType" SG_ 982 LH_Schluss_Nebel_re_def 0;
BA_ "GenSigSwitchedByIgnition" SG_ 982 LH_Schluss_Nebel_re_def 0;
BA_ "GenSigSendType" SG_ 982 LH_Schlusslicht_li_def 0;
BA_ "GenSigSwitchedByIgnition" SG_ 982 LH_Schlusslicht_li_def 0;
BA_ "GenSigSendType" SG_ 982 LH_Schlusslicht_re_def 0;
BA_ "GenSigSwitchedByIgnition" SG_ 982 LH_Schlusslicht_re_def 0;
BA_ "GenSigSendType" SG_ 982 LH_SL_BRL_BLK_li_def 0;
BA_ "GenSigSwitchedByIgnition" SG_ 982 LH_SL_BRL_BLK_li_def 0;
BA_ "GenSigSendType" SG_ 982 LH_SL_BRL_BLK_re_def 0;
BA_ "GenSigSwitchedByIgnition" SG_ 982 LH_SL_BRL_BLK_re_def 0;
BA_ "GenSigSendType" SG_ 982 LH_Standlicht_H_aktiv 0;
BA_ "GenSigSwitchedByIgnition" SG_ 982 LH_Standlicht_H_aktiv 0;
BA_ "GenSigSendType" SG_ 982 LH_Zusatzschlussl_def 0;
BA_ "GenSigSwitchedByIgnition" SG_ 982 LH_Zusatzschlussl_def 0;
BA_ "GenSigSendType" SG_ 982 Licht_hinten_01_BZ 0;
BA_ "GenSigFuncType" SG_ 982 Licht_hinten_01_BZ 1;
BA_ "GenSigSwitchedByIgnition" SG_ 982 Licht_hinten_01_BZ 0;
BA_ "GenSigSendType" SG_ 1624 BCM1_Licht_Dunkelheit_aktiv 3;
BA_ "GenSigSwitchedByIgnition" SG_ 1624 BCM1_Licht_Dunkelheit_aktiv 0;
BA_ "GenSigSendType" SG_ 1624 BCM1_Linksverkehr 0;
BA_ "GenSigSwitchedByIgnition" SG_ 1624 BCM1_Linksverkehr 0;
BA_ "GenSigSendType" SG_ 1624 Licht_Vorne_01_BZ 0;
BA_ "GenSigFuncType" SG_ 1624 Licht_Vorne_01_BZ 1;
BA_ "GenSigSendType" SG_ 1624 Licht_Vorne_01_CRC 0;
BA_ "GenSigFuncType" SG_ 1624 Licht_Vorne_01_CRC 2;
BA_ "GenSigSendType" SG_ 1624 LV_Abbiegelicht_li_def 0;
BA_ "GenSigSwitchedByIgnition" SG_ 1624 LV_Abbiegelicht_li_def 0;
BA_ "GenSigSendType" SG_ 1624 LV_Abbiegelicht_re_def 0;
BA_ "GenSigSwitchedByIgnition" SG_ 1624 LV_Abbiegelicht_re_def 0;
BA_ "GenSigSendType" SG_ 1624 LV_Abblend_Fernlicht_li_def 0;
BA_ "GenSigSwitchedByIgnition" SG_ 1624 LV_Abblend_Fernlicht_li_def 0;
BA_ "GenSigSendType" SG_ 1624 LV_Abblend_Fernlicht_re_def 0;
BA_ "GenSigSwitchedByIgnition" SG_ 1624 LV_Abblend_Fernlicht_re_def 0;
BA_ "GenSigSendType" SG_ 1624 LV_Abblendlicht_Anzeige 3;
BA_ "GenSigSwitchedByIgnition" SG_ 1624 LV_Abblendlicht_Anzeige 0;
BA_ "GenSigSendType" SG_ 1624 LV_Abblendlicht_li_def 0;
BA_ "GenSigSwitchedByIgnition" SG_ 1624 LV_Abblendlicht_li_def 0;
BA_ "GenSigSendType" SG_ 1624 LV_Abblendlicht_re_def 0;
BA_ "GenSigSwitchedByIgnition" SG_ 1624 LV_Abblendlicht_re_def 0;
BA_ "GenSigSendType" SG_ 1624 LV_Abblendlicht_TFL_li_def 0;
BA_ "GenSigSwitchedByIgnition" SG_ 1624 LV_Abblendlicht_TFL_li_def 0;
BA_ "GenSigSendType" SG_ 1624 LV_Abblendlicht_TFL_re_def 0;
BA_ "GenSigSwitchedByIgnition" SG_ 1624 LV_Abblendlicht_TFL_re_def 0;
BA_ "GenSigSendType" SG_ 1624 LV_AFL_aktiv_Anzeige 3;
BA_ "GenSigSwitchedByIgnition" SG_ 1624 LV_AFL_aktiv_Anzeige 0;
BA_ "GenSigSendType" SG_ 1624 LV_AFL_defekt 3;
BA_ "GenSigSwitchedByIgnition" SG_ 1624 LV_AFL_defekt 0;
BA_ "GenSigSendType" SG_ 1624 LV_Aussenlicht_def 0;
BA_ "GenSigSwitchedByIgnition" SG_ 1624 LV_Aussenlicht_def 0;
BA_ "GenSigSendType" SG_ 1624 LV_Blinker_li_def 0;
BA_ "GenSigSwitchedByIgnition" SG_ 1624 LV_Blinker_li_def 0;
BA_ "GenSigSendType" SG_ 1624 LV_Blinker_re_def 0;
BA_ "GenSigSwitchedByIgnition" SG_ 1624 LV_Blinker_re_def 0;
BA_ "GenSigSendType" SG_ 1624 LV_Blinker_VL_aktiv 3;
BA_ "GenSigSwitchedByIgnition" SG_ 1624 LV_Blinker_VL_aktiv 0;
BA_ "GenSigSendType" SG_ 1624 LV_Blinker_VR_aktiv 3;
BA_ "GenSigSwitchedByIgnition" SG_ 1624 LV_Blinker_VR_aktiv 0;
BA_ "GenSigSendType" SG_ 1624 LV_Blk_li_Seite_def 0;
BA_ "GenSigSwitchedByIgnition" SG_ 1624 LV_Blk_li_Seite_def 0;
BA_ "GenSigSendType" SG_ 1624 LV_Blk_re_Seite_def 0;
BA_ "GenSigSwitchedByIgnition" SG_ 1624 LV_Blk_re_Seite_def 0;
BA_ "GenSigSendType" SG_ 1624 LV_Fernlicht_Anzeige 3;
BA_ "GenSigSwitchedByIgnition" SG_ 1624 LV_Fernlicht_Anzeige 0;
BA_ "GenSigSendType" SG_ 1624 LV_Fernlicht_li_def 0;
BA_ "GenSigSwitchedByIgnition" SG_ 1624 LV_Fernlicht_li_def 0;
BA_ "GenSigSendType" SG_ 1624 LV_Fernlicht_re_def 0;
BA_ "GenSigSwitchedByIgnition" SG_ 1624 LV_Fernlicht_re_def 0;
BA_ "GenSigSendType" SG_ 1624 LV_FLA_aktiv_Anzeige 3;
BA_ "GenSigSwitchedByIgnition" SG_ 1624 LV_FLA_aktiv_Anzeige 0;
BA_ "GenSigSendType" SG_ 1624 LV_FLA_defekt 0;
BA_ "GenSigSwitchedByIgnition" SG_ 1624 LV_FLA_defekt 0;
BA_ "GenSigSendType" SG_ 1624 LV_FLA_Sensor_blockiert 0;
BA_ "GenSigSwitchedByIgnition" SG_ 1624 LV_FLA_Sensor_blockiert 0;
BA_ "GenSigSendType" SG_ 1624 LV_LED_Scheinwerfer_li_def 0;
BA_ "GenSigSwitchedByIgnition" SG_ 1624 LV_LED_Scheinwerfer_li_def 0;
BA_ "GenSigSendType" SG_ 1624 LV_LED_Scheinwerfer_re_def 0;
BA_ "GenSigSwitchedByIgnition" SG_ 1624 LV_LED_Scheinwerfer_re_def 0;
BA_ "GenSigSendType" SG_ 1624 LV_MXB_Status_Anzeige 3;
BA_ "GenSigSwitchedByIgnition" SG_ 1624 LV_MXB_Status_Anzeige 0;
BA_ "GenSigSendType" SG_ 1624 LV_Nebellicht_Anzeige 3;
BA_ "GenSigSwitchedByIgnition" SG_ 1624 LV_Nebellicht_Anzeige 0;
BA_ "GenSigSendType" SG_ 1624 LV_Nebellicht_li_def 0;
BA_ "GenSigSwitchedByIgnition" SG_ 1624 LV_Nebellicht_li_def 0;
BA_ "GenSigSendType" SG_ 1624 LV_Nebellicht_re_def 0;
BA_ "GenSigSwitchedByIgnition" SG_ 1624 LV_Nebellicht_re_def 0;
BA_ "GenSigSendType" SG_ 1624 LV_Nebellicht_TFL_li_def 0;
BA_ "GenSigSwitchedByIgnition" SG_ 1624 LV_Nebellicht_TFL_li_def 0;
BA_ "GenSigSendType" SG_ 1624 LV_Nebellicht_TFL_re_def 0;
BA_ "GenSigSwitchedByIgnition" SG_ 1624 LV_Nebellicht_TFL_re_def 0;
BA_ "GenSigSendType" SG_ 1624 LV_Nebelschlusslicht_Anzeige 3;
BA_ "GenSigSwitchedByIgnition" SG_ 1624 LV_Nebelschlusslicht_Anzeige 0;
BA_ "GenSigSendType" SG_ 1624 LV_Standlicht_Anzeige 3;
BA_ "GenSigSwitchedByIgnition" SG_ 1624 LV_Standlicht_Anzeige 0;
BA_ "GenSigSendType" SG_ 1624 LV_Standlicht_li_def 0;
BA_ "GenSigSwitchedByIgnition" SG_ 1624 LV_Standlicht_li_def 0;
BA_ "GenSigSendType" SG_ 1624 LV_Standlicht_re_def 0;
BA_ "GenSigSwitchedByIgnition" SG_ 1624 LV_Standlicht_re_def 0;
BA_ "GenSigSendType" SG_ 1624 LV_Standlicht_TFL_li_def 0;
BA_ "GenSigSwitchedByIgnition" SG_ 1624 LV_Standlicht_TFL_li_def 0;
BA_ "GenSigSendType" SG_ 1624 LV_Standlicht_TFL_re_def 0;
BA_ "GenSigSwitchedByIgnition" SG_ 1624 LV_Standlicht_TFL_re_def 0;
BA_ "GenSigSendType" SG_ 1624 LV_Tagfahrlicht_Anzeige 3;
BA_ "GenSigSwitchedByIgnition" SG_ 1624 LV_Tagfahrlicht_Anzeige 0;
BA_ "GenSigSendType" SG_ 1624 LV_Tagfahrlicht_li_def 0;
BA_ "GenSigSwitchedByIgnition" SG_ 1624 LV_Tagfahrlicht_li_def 0;
BA_ "GenSigSendType" SG_ 1624 LV_Tagfahrlicht_re_def 0;
BA_ "GenSigSwitchedByIgnition" SG_ 1624 LV_Tagfahrlicht_re_def 0;
BA_ "GenSigSendType" SG_ 2463978598 LoGeWa_C2C_Anf_Audioabsenkung 3;
BA_ "GenSigSwitchedByIgnition" SG_ 2463978598 LoGeWa_C2C_Anf_Audioabsenkung 0;
BA_ "GenSigSendType" SG_ 2463978598 LoGeWa_C2C_Event_Einheit 0;
BA_ "GenSigSendType" SG_ 2463978598 LoGeWa_C2C_Event_Entfernung 0;
BA_ "GenSigStartValue" SG_ 2463978598 LoGeWa_C2C_Event_Entfernung 65535;
BA_ "GenSigSendType" SG_ 2463978598 LoGeWa_C2C_Event_Richtung 0;
BA_ "GenSigSendType" SG_ 2463978598 LoGeWa_C2C_Event_Status 3;
BA_ "GenSigSendType" SG_ 2463978598 LoGeWa_C2C_Event_Warnung 0;
BA_ "GenSigSwitchedByIgnition" SG_ 2463978598 LoGeWa_C2C_Event_Warnung 0;
BA_ "GenSigSendType" SG_ 2527679633 LSH_Ansaug_Fuell_1 0;
BA_ "GenSigStartValue" SG_ 2527679633 LSH_Ansaug_Fuell_1 254;
BA_ "GenSigSwitchedByIgnition" SG_ 2527679633 LSH_Ansaug_Fuell_1 0;
BA_ "Fehlerwert" SG_ 2527679633 LSH_Ansaug_Fuell_1 255;
BA_ "GenSigSendType" SG_ 2527679633 LSH_Ansaug_Fuell_2 0;
BA_ "GenSigStartValue" SG_ 2527679633 LSH_Ansaug_Fuell_2 254;
BA_ "GenSigSwitchedByIgnition" SG_ 2527679633 LSH_Ansaug_Fuell_2 0;
BA_ "Fehlerwert" SG_ 2527679633 LSH_Ansaug_Fuell_2 255;
BA_ "GenSigSendType" SG_ 2527679633 LSH_Empf_Heizstufe 0;
BA_ "GenSigSwitchedByIgnition" SG_ 2527679633 LSH_Empf_Heizstufe 0;
BA_ "Fehlerwert" SG_ 2527679633 LSH_Empf_Heizstufe 15;
BA_ "GenSigSendType" SG_ 2527679633 LSH_Funk_aus 0;
BA_ "GenSigSwitchedByIgnition" SG_ 2527679633 LSH_Funk_aus 0;
BA_ "GenSigSendType" SG_ 2527679633 LSH_Funk_ein 0;
BA_ "GenSigSwitchedByIgnition" SG_ 2527679633 LSH_Funk_ein 0;
BA_ "GenSigSendType" SG_ 2527679633 LSH_Geblaese_aktiv 0;
BA_ "GenSigSwitchedByIgnition" SG_ 2527679633 LSH_Geblaese_aktiv 0;
BA_ "GenSigSendType" SG_ 2527679633 LSH_Heiztemp 0;
BA_ "GenSigStartValue" SG_ 2527679633 LSH_Heiztemp 254;
BA_ "GenSigSwitchedByIgnition" SG_ 2527679633 LSH_Heiztemp 0;
BA_ "Fehlerwert" SG_ 2527679633 LSH_Heiztemp 255;
BA_ "GenSigSendType" SG_ 2527679633 LSH_Klappe_Status 0;
BA_ "GenSigSwitchedByIgnition" SG_ 2527679633 LSH_Klappe_Status 0;
BA_ "GenSigSendType" SG_ 2527679633 LSH_LED 0;
BA_ "GenSigSwitchedByIgnition" SG_ 2527679633 LSH_LED 0;
BA_ "GenSigSendType" SG_ 2527679633 LSH_Servicemode 0;
BA_ "GenSigSwitchedByIgnition" SG_ 2527679633 LSH_Servicemode 0;
BA_ "GenSigSendType" SG_ 2527679633 LSH_Start_folgt 0;
BA_ "GenSigSwitchedByIgnition" SG_ 2527679633 LSH_Start_folgt 0;
BA_ "GenSigSendType" SG_ 2527679633 LSH_Texte 0;
BA_ "GenSigSwitchedByIgnition" SG_ 2527679633 LSH_Texte 0;
BA_ "GenSigSendType" SG_ 2527679633 LSH_Waermeeintrag 0;
BA_ "GenSigStartValue" SG_ 2527679633 LSH_Waermeeintrag 510;
BA_ "GenSigSwitchedByIgnition" SG_ 2527679633 LSH_Waermeeintrag 0;
BA_ "Fehlerwert" SG_ 2527679633 LSH_Waermeeintrag 511;
BA_ "GenSigSendType" SG_ 2527679634 LSH_Fehlerstatus 0;
BA_ "GenSigSwitchedByIgnition" SG_ 2527679634 LSH_Fehlerstatus 0;
BA_ "GenSigSendType" SG_ 2527679634 LSH_Heizleistung 0;
BA_ "GenSigSwitchedByIgnition" SG_ 2527679634 LSH_Heizleistung 0;
BA_ "GenSigSendType" SG_ 2527679634 LSH_KL_DBetr_Anf 0;
BA_ "GenSigSwitchedByIgnition" SG_ 2527679634 LSH_KL_DBetr_Anf 0;
BA_ "GenSigSendType" SG_ 2527679634 LSH_KVS 0;
BA_ "GenSigSwitchedByIgnition" SG_ 2527679634 LSH_KVS 0;
BA_ "GenSigSendType" SG_ 2527679634 LSH_KVS_Ueberlauf 0;
BA_ "GenSigSwitchedByIgnition" SG_ 2527679634 LSH_KVS_Ueberlauf 0;
BA_ "GenSigSendType" SG_ 2527679634 LSH_Zuheizen 0;
BA_ "GenSigSwitchedByIgnition" SG_ 2527679634 LSH_Zuheizen 0;
BA_ "GenSigSendType" SG_ 134 LWI_01_BZ 0;
BA_ "GenSigFuncType" SG_ 134 LWI_01_BZ 1;
BA_ "GenSigSendType" SG_ 134 LWI_01_CRC 0;
BA_ "GenSigFuncType" SG_ 134 LWI_01_CRC 2;
BA_ "GenSigSwitchedByIgnition" SG_ 134 LWI_01_CRC 0;
BA_ "GenSigSendType" SG_ 134 LWI_Lenkradw_Geschw 0;
BA_ "GenSigStartValue" SG_ 134 LWI_Lenkradw_Geschw 510;
BA_ "Fehlerwert" SG_ 134 LWI_Lenkradw_Geschw 511;
BA_ "GenSigSendType" SG_ 134 LWI_Lenkradwinkel 0;
BA_ "GenSigStartValue" SG_ 134 LWI_Lenkradwinkel 8190;
BA_ "Fehlerwert" SG_ 134 LWI_Lenkradwinkel 8191;
BA_ "GenSigSendType" SG_ 134 LWI_QBit_Lenkradwinkel 0;
BA_ "GenSigStartValue" SG_ 134 LWI_QBit_Lenkradwinkel 1;
BA_ "GenSigSendType" SG_ 134 LWI_QBit_Sub_Daten 0;
BA_ "GenSigSendType" SG_ 134 LWI_Sensorstatus 0;
BA_ "GenSigSendType" SG_ 134 LWI_Sub_Daten 0;
BA_ "GenSigSendType" SG_ 134 LWI_VZ_Lenkradw_Geschw 0;
BA_ "GenSigSendType" SG_ 134 LWI_VZ_Lenkradwinkel 0;
BA_ "GenSigSendType" SG_ 1153 DSSS_Warning 3;
BA_ "GenSigSwitchedByIgnition" SG_ 1153 DSSS_Warning 0;
BA_ "GenSigSendType" SG_ 1153 MIB_ASW_Diagnose 0;
BA_ "GenSigSwitchedByIgnition" SG_ 1153 MIB_ASW_Diagnose 0;
BA_ "GenSigSendType" SG_ 1153 MIB_Tongenerator_PH_verfuegbar 3;
BA_ "GenSigSwitchedByIgnition" SG_ 1153 MIB_Tongenerator_PH_verfuegbar 0;
BA_ "GenSigSendType" SG_ 1153 MMI_Counter_Bedienevent 0;
BA_ "GenSigSwitchedByIgnition" SG_ 1153 MMI_Counter_Bedienevent 0;
BA_ "GenSigSendType" SG_ 1153 MMI_Gurt_Mic_ref 3;
BA_ "GenSigSwitchedByIgnition" SG_ 1153 MMI_Gurt_Mic_ref 0;
BA_ "GenSigSendType" SG_ 1153 MMI_SDS_aktiv 3;
BA_ "GenSigSwitchedByIgnition" SG_ 1153 MMI_SDS_aktiv 0;
BA_ "GenSigSendType" SG_ 1153 MMI_Telefon_aktiv 3;
BA_ "GenSigSwitchedByIgnition" SG_ 1153 MMI_Telefon_aktiv 0;
BA_ "GenSigSendType" SG_ 1153 MU_SecondDisplay 3;
BA_ "GenSigSwitchedByIgnition" SG_ 1153 MU_SecondDisplay 0;
BA_ "GenSigSendType" SG_ 1153 MU_Update_Time 0;
BA_ "GenSigSwitchedByIgnition" SG_ 1153 MU_Update_Time 0;
BA_ "GenSigSendType" SG_ 1153 Nav_FoD_Status 0;
BA_ "GenSigSwitchedByIgnition" SG_ 1153 Nav_FoD_Status 0;
BA_ "GenSigSendType" SG_ 1153 ZR_AppConnect_Zustand 4;
BA_ "GenSigSwitchedByIgnition" SG_ 1153 ZR_AppConnect_Zustand 0;
BA_ "GenSigSendType" SG_ 1153 ZR_Kindersicherung_RSE 3;
BA_ "GenSigSwitchedByIgnition" SG_ 1153 ZR_Kindersicherung_RSE 0;
BA_ "GenSigSendType" SG_ 1153 ZR_Lichter_Tag 3;
BA_ "GenSigSwitchedByIgnition" SG_ 1153 ZR_Lichter_Tag 0;
BA_ "GenSigSendType" SG_ 1153 ZR_LoGeWa_Event_Kombiwarnung 3;
BA_ "GenSigSwitchedByIgnition" SG_ 1153 ZR_LoGeWa_Event_Kombiwarnung 0;
BA_ "GenSigSendType" SG_ 1153 ZR_Parken_Sondermodus 3;
BA_ "GenSigSwitchedByIgnition" SG_ 1153 ZR_Parken_Sondermodus 0;
BA_ "GenSigSendType" SG_ 1153 ZR_RSE_aktivieren 3;
BA_ "GenSigSwitchedByIgnition" SG_ 1153 ZR_RSE_aktivieren 0;
BA_ "GenSigSendType" SG_ 1153 ZR_Sta_Inszenierung 4;
BA_ "GenSigSwitchedByIgnition" SG_ 1153 ZR_Sta_Inszenierung 0;
BA_ "GenSigSendType" SG_ 1178 FS_BFS_Fond_Verst_enable 3;
BA_ "GenSigSwitchedByIgnition" SG_ 1178 FS_BFS_Fond_Verst_enable 0;
BA_ "GenSigSendType" SG_ 1178 FS_BFS_KSS_Anfahrt 3;
BA_ "GenSigSwitchedByIgnition" SG_ 1178 FS_BFS_KSS_Anfahrt 0;
BA_ "GenSigSendType" SG_ 1178 FS_BFS_Sitzsym_Anfahrt 3;
BA_ "GenSigSwitchedByIgnition" SG_ 1178 FS_BFS_Sitzsym_Anfahrt 0;
BA_ "GenSigSendType" SG_ 1178 FS_EE_BFS_enable 3;
BA_ "GenSigSwitchedByIgnition" SG_ 1178 FS_EE_BFS_enable 0;
BA_ "GenSigSendType" SG_ 1178 FS_EE_Fond_BFS_enable 3;
BA_ "GenSigSwitchedByIgnition" SG_ 1178 FS_EE_Fond_BFS_enable 0;
BA_ "GenSigSendType" SG_ 1178 FS_EE_Fond_FS_enable 3;
BA_ "GenSigSwitchedByIgnition" SG_ 1178 FS_EE_Fond_FS_enable 0;
BA_ "GenSigSendType" SG_ 1178 FS_Fond_Bed_enable 3;
BA_ "GenSigSwitchedByIgnition" SG_ 1178 FS_Fond_Bed_enable 0;
BA_ "GenSigSendType" SG_ 1178 FS_GHV_aktiv 3;
BA_ "GenSigSwitchedByIgnition" SG_ 1178 FS_GHV_aktiv 0;
BA_ "GenSigSendType" SG_ 1178 FS_Gurtbringer_Sperre 0;
BA_ "GenSigSwitchedByIgnition" SG_ 1178 FS_Gurtbringer_Sperre 0;
BA_ "GenSigSendType" SG_ 1178 FS_KSV_aktiv 3;
BA_ "GenSigSwitchedByIgnition" SG_ 1178 FS_KSV_aktiv 0;
BA_ "GenSigSendType" SG_ 1178 FS_Lehne_nicht_verriegelt 3;
BA_ "GenSigSwitchedByIgnition" SG_ 1178 FS_Lehne_nicht_verriegelt 0;
BA_ "GenSigSendType" SG_ 1178 FS_LHV_aktiv 3;
BA_ "GenSigSwitchedByIgnition" SG_ 1178 FS_LHV_aktiv 0;
BA_ "GenSigSendType" SG_ 1178 FS_LKV_aktiv 3;
BA_ "GenSigSwitchedByIgnition" SG_ 1178 FS_LKV_aktiv 0;
BA_ "GenSigSendType" SG_ 1178 FS_LNV_aktiv 3;
BA_ "GenSigSwitchedByIgnition" SG_ 1178 FS_LNV_aktiv 0;
BA_ "GenSigSendType" SG_ 1178 FS_LWV_aktiv 3;
BA_ "GenSigSwitchedByIgnition" SG_ 1178 FS_LWV_aktiv 0;
BA_ "GenSigSendType" SG_ 1178 FS_MMB_glob_stop 3;
BA_ "GenSigSwitchedByIgnition" SG_ 1178 FS_MMB_glob_stop 0;
BA_ "GenSigSendType" SG_ 1178 FS_MMB_lokal_Stop 3;
BA_ "GenSigSwitchedByIgnition" SG_ 1178 FS_MMB_lokal_Stop 0;
BA_ "GenSigSendType" SG_ 1178 FS_MMB_storage 3;
BA_ "GenSigSwitchedByIgnition" SG_ 1178 FS_MMB_storage 0;
BA_ "GenSigSendType" SG_ 1178 FS_MMB_storage_beep 3;
BA_ "GenSigSwitchedByIgnition" SG_ 1178 FS_MMB_storage_beep 0;
BA_ "GenSigSendType" SG_ 1178 FS_MMB_store 3;
BA_ "GenSigSwitchedByIgnition" SG_ 1178 FS_MMB_store 0;
BA_ "GenSigSendType" SG_ 1178 FS_MMB_store_LED_on 3;
BA_ "GenSigSwitchedByIgnition" SG_ 1178 FS_MMB_store_LED_on 0;
BA_ "GenSigSendType" SG_ 1178 FS_MMB_tast 3;
BA_ "GenSigSwitchedByIgnition" SG_ 1178 FS_MMB_tast 0;
BA_ "GenSigSendType" SG_ 1178 FS_MMB_tipp 3;
BA_ "GenSigSwitchedByIgnition" SG_ 1178 FS_MMB_tipp 0;
BA_ "GenSigSendType" SG_ 1178 FS_SHV_aktiv 3;
BA_ "GenSigSwitchedByIgnition" SG_ 1178 FS_SHV_aktiv 0;
BA_ "GenSigSendType" SG_ 1178 FS_Sitzfahrt_aktiv 3;
BA_ "GenSigSwitchedByIgnition" SG_ 1178 FS_Sitzfahrt_aktiv 0;
BA_ "GenSigSendType" SG_ 1178 FS_SLV_aktiv 3;
BA_ "GenSigSwitchedByIgnition" SG_ 1178 FS_SLV_aktiv 0;
BA_ "GenSigSendType" SG_ 1178 FS_SNV_aktiv 3;
BA_ "GenSigSwitchedByIgnition" SG_ 1178 FS_SNV_aktiv 0;
BA_ "GenSigSendType" SG_ 1178 FS_Spezialposition_anfahren 3;
BA_ "GenSigSwitchedByIgnition" SG_ 1178 FS_Spezialposition_anfahren 0;
BA_ "GenSigSendType" SG_ 1178 FS_STV_aktiv 3;
BA_ "GenSigSwitchedByIgnition" SG_ 1178 FS_STV_aktiv 0;
BA_ "GenSigSendType" SG_ 1178 Mem_FS_01_MQB_BZ 0;
BA_ "GenSigFuncType" SG_ 1178 Mem_FS_01_MQB_BZ 1;
BA_ "GenSigSwitchedByIgnition" SG_ 1178 Mem_FS_01_MQB_BZ 0;
BA_ "GenSigSendType" SG_ 1178 Mem_FS_01_MQB_CRC 0;
BA_ "GenSigFuncType" SG_ 1178 Mem_FS_01_MQB_CRC 2;
BA_ "GenSigSwitchedByIgnition" SG_ 1178 Mem_FS_01_MQB_CRC 0;
BA_ "GenSigSendType" SG_ 1165 MF_ADR_Anforderung 0;
BA_ "GenSigSendType" SG_ 1165 MF_ADR_Fahrpedalsperre 0;
BA_ "GenSigSwitchedByIgnition" SG_ 1165 MF_ADR_Fahrpedalsperre 0;
BA_ "GenSigSendType" SG_ 1165 MF_ADR_neg_Rampe 0;
BA_ "GenSigSwitchedByIgnition" SG_ 1165 MF_ADR_neg_Rampe 0;
BA_ "GenSigSendType" SG_ 1165 MF_ADR_pos_Rampe 0;
BA_ "GenSigSendType" SG_ 1165 MF_ADR_Solldrehzahl 0;
BA_ "GenSigSendType" SG_ 1165 MF_MFSS_aktiv 0;
BA_ "GenSigSendType" SG_ 1165 MF_MFSS_kodiert 0;
BA_ "GenSigSwitchedByIgnition" SG_ 1165 MF_MFSS_kodiert 0;
BA_ "GenSigSendType" SG_ 1165 MF_VBEG_Anforderung 0;
BA_ "GenSigSendType" SG_ 1165 MF_VBEG_Geschwindigkeit 0;
BA_ "GenSigStartValue" SG_ 1165 MF_VBEG_Geschwindigkeit 255;
BA_ "GenSigSendType" SG_ 1165 MFG_02_BZ 0;
BA_ "GenSigFuncType" SG_ 1165 MFG_02_BZ 1;
BA_ "GenSigSendType" SG_ 1165 MFG_02_CRC 0;
BA_ "GenSigFuncType" SG_ 1165 MFG_02_CRC 2;
BA_ "GenSigSendType" SG_ 1165 MFG_Heizstufe_LSH 0;
BA_ "GenSigSwitchedByIgnition" SG_ 1165 MFG_Heizstufe_LSH 0;
BA_ "Fehlerwert" SG_ 1165 MFG_Heizstufe_LSH 15;
BA_ "GenSigSendType" SG_ 1165 MFG_Status_SREG 0;
BA_ "GenSigSwitchedByIgnition" SG_ 1165 MFG_Status_SREG 0;
BA_ "GenSigSendType" SG_ 1165 MFG_Taster_SREG 0;
BA_ "GenSigStartValue" SG_ 1165 MFG_Taster_SREG 2;
BA_ "GenSigSwitchedByIgnition" SG_ 1165 MFG_Taster_SREG 0;
BA_ "Fehlerwert" SG_ 1165 MFG_Taster_SREG 3;
BA_ "GenSigSendType" SG_ 1165 MFG_Taster_VREG 0;
BA_ "GenSigStartValue" SG_ 1165 MFG_Taster_VREG 2;
BA_ "GenSigSwitchedByIgnition" SG_ 1165 MFG_Taster_VREG 0;
BA_ "Fehlerwert" SG_ 1165 MFG_Taster_VREG 3;
BA_ "GenSigSendType" SG_ 1165 MFG_Zuheizer_Freigabe 0;
BA_ "GenSigSwitchedByIgnition" SG_ 1165 MFG_Zuheizer_Freigabe 0;
BA_ "GenSigSendType" SG_ 1164 MF_2BatSOCzugering 0;
BA_ "GenSigSendType" SG_ 1164 MF_2BattAb 0;
BA_ "GenSigSendType" SG_ 1164 MF_2BattHlkAnf 0;
BA_ "GenSigSendType" SG_ 1164 MF_2BattLadWarn 0;
BA_ "GenSigSendType" SG_ 1164 MF_2BattLlaAnf 0;
BA_ "GenSigSendType" SG_ 1164 MF_2BattSpannungsAnf 0;
BA_ "GenSigSendType" SG_ 1164 MF_Batteriediagnose 0;
BA_ "GenSigSwitchedByIgnition" SG_ 1164 MF_Batteriediagnose 0;
BA_ "Fehlerwert" SG_ 1164 MF_Batteriediagnose 7;
BA_ "GenSigSendType" SG_ 1164 MF_Blinker_L_Sta 3;
BA_ "GenSigSwitchedByIgnition" SG_ 1164 MF_Blinker_L_Sta 0;
BA_ "GenSigSendType" SG_ 1164 MF_Blinker_R_Sta 3;
BA_ "GenSigSwitchedByIgnition" SG_ 1164 MF_Blinker_R_Sta 0;
BA_ "GenSigSendType" SG_ 1164 MF_ExterneLadungWarn 0;
BA_ "GenSigSendType" SG_ 1164 MF_Fahrerhinweis 0;
BA_ "GenSigSendType" SG_ 1164 MF_Generatordiagnose 0;
BA_ "GenSigStartValue" SG_ 1164 MF_Generatordiagnose 3;
BA_ "GenSigSwitchedByIgnition" SG_ 1164 MF_Generatordiagnose 0;
BA_ "GenSigSendType" SG_ 1164 MF_Heck_entriegeln 0;
BA_ "GenSigSendType" SG_ 1164 MF_Heck_verriegeln 0;
BA_ "GenSigSendType" SG_ 1164 MF_interm_Nebelscheinwerfer 0;
BA_ "GenSigSwitchedByIgnition" SG_ 1164 MF_interm_Nebelscheinwerfer 0;
BA_ "GenSigSendType" SG_ 1164 MF_Lampenausfall 0;
BA_ "GenSigSwitchedByIgnition" SG_ 1164 MF_Lampenausfall 0;
BA_ "GenSigSendType" SG_ 1164 MF_LSH_Abschaltstufe 0;
BA_ "GenSigSwitchedByIgnition" SG_ 1164 MF_LSH_Abschaltstufe 0;
BA_ "GenSigSendType" SG_ 1164 MF_LSH_Einschaltverbot 0;
BA_ "GenSigSwitchedByIgnition" SG_ 1164 MF_LSH_Einschaltverbot 0;
BA_ "GenSigSendType" SG_ 1164 MF_LSH_Zielzeit 0;
BA_ "GenSigStartValue" SG_ 1164 MF_LSH_Zielzeit 14;
BA_ "GenSigSwitchedByIgnition" SG_ 1164 MF_LSH_Zielzeit 0;
BA_ "Fehlerwert" SG_ 1164 MF_LSH_Zielzeit 15;
BA_ "GenSigSendType" SG_ 1164 MF_NotStartAktiv 0;
BA_ "GenSigSendType" SG_ 1164 MF_Radiomute 3;
BA_ "GenSigSwitchedByIgnition" SG_ 1164 MF_Radiomute 0;
BA_ "GenSigSendType" SG_ 1164 MF_Relais_2_Batterie 3;
BA_ "GenSigSwitchedByIgnition" SG_ 1164 MF_Relais_2_Batterie 0;
BA_ "GenSigSendType" SG_ 1164 MF_Tuerverriegelung_hinten 3;
BA_ "GenSigSwitchedByIgnition" SG_ 1164 MF_Tuerverriegelung_hinten 0;
BA_ "GenSigSendType" SG_ 1164 MF_ZV_Unlock 0;
BA_ "GenSigSwitchedByIgnition" SG_ 1164 MF_ZV_Unlock 0;
BA_ "GenSigSendType" SG_ 1164 MFG_AppConnect_Anf 4;
BA_ "GenSigSwitchedByIgnition" SG_ 1164 MFG_AppConnect_Anf 0;
BA_ "GenSigSendType" SG_ 1164 MFG_Infotainment_Autark 0;
BA_ "GenSigSwitchedByIgnition" SG_ 1164 MFG_Infotainment_Autark 0;
BA_ "GenSigSendType" SG_ 1164 MFG_Klappe_Status 0;
BA_ "GenSigSwitchedByIgnition" SG_ 1164 MFG_Klappe_Status 0;
BA_ "GenSigSendType" SG_ 1164 MFG_LSH_Ansteuerung 0;
BA_ "GenSigSwitchedByIgnition" SG_ 1164 MFG_LSH_Ansteuerung 0;
BA_ "GenSigSendType" SG_ 1164 MFG_LSH_Betriebsdauer 0;
BA_ "GenSigSwitchedByIgnition" SG_ 1164 MFG_LSH_Betriebsdauer 0;
BA_ "GenSigSendType" SG_ 1164 MFG_LSH_DBetr_Bestaet 0;
BA_ "GenSigSwitchedByIgnition" SG_ 1164 MFG_LSH_DBetr_Bestaet 0;
BA_ "GenSigSendType" SG_ 1164 MFG_LSH_DBetr_Ein 0;
BA_ "GenSigSwitchedByIgnition" SG_ 1164 MFG_LSH_DBetr_Ein 0;
BA_ "GenSigSendType" SG_ 1471 MFL_Eventcode_1 9;
BA_ "GenSigSwitchedByIgnition" SG_ 1471 MFL_Eventcode_1 0;
BA_ "GenSigSendType" SG_ 1471 MFL_Eventcode_2 9;
BA_ "GenSigSwitchedByIgnition" SG_ 1471 MFL_Eventcode_2 0;
BA_ "GenSigFuncType" SG_ 1471 MFL_Marke 8;
BA_ "GenSigSwitchedByIgnition" SG_ 1471 MFL_Marke 0;
BA_ "GenSigSendType" SG_ 1471 MFL_Tastencode_1 9;
BA_ "GenSigSwitchedByIgnition" SG_ 1471 MFL_Tastencode_1 0;
BA_ "GenSigSendType" SG_ 1471 MFL_Tastencode_2 9;
BA_ "GenSigSwitchedByIgnition" SG_ 1471 MFL_Tastencode_2 0;
BA_ "GenSigFuncType" SG_ 1471 MFL_Variante 8;
BA_ "GenSigSwitchedByIgnition" SG_ 1471 MFL_Variante 0;
BA_ "GenSigSendType" SG_ 2463978670 SDF2_MIB_Fehler_Laengsrichtung 0;
BA_ "GenSigSendType" SG_ 2463978670 SDF2_MIB_Inhibitzeit 0;
BA_ "GenSigSendType" SG_ 2463978670 SDF2_MIB_Offset 0;
BA_ "GenSigSendType" SG_ 2463978670 SDF2_MIB_Segment_ID 0;
BA_ "GenSigSendType" SG_ 2463978670 SDF2_MIB_Standort_Eindeutig 0;
BA_REL_ "GenSigTimeoutTime" BU_SG_REL_ CDI SG_ 779 KBI_angez_Geschw 500;
BA_REL_ "GenSigTimeoutTime" BU_SG_REL_ CDI SG_ 1719 KBI_Kilometerstand 5000;
BA_REL_ "GenSigTimeoutTime" BU_SG_REL_ CDI SG_ 1624 BCM1_Licht_Dunkelheit_aktiv 5000;
BA_REL_ "GenSigTimeoutTime" BU_SG_REL_ ConMod_CD SG_ 1719 KBI_Kilometerstand 5000;
BA_REL_ "GenSigTimeoutTime" BU_SG_REL_ DashCAM SG_ 779 KBI_MFA_v_Einheit_01 500;
BA_REL_ "GenSigTimeoutTime" BU_SG_REL_ DashCAM SG_ 779 KBI_V_Digital 500;
BA_REL_ "GenSigTimeoutTime" BU_SG_REL_ DashCAM SG_ 1624 LV_Abblendlicht_Anzeige 5000;
BA_REL_ "GenSigTimeoutTime" BU_SG_REL_ DashCAM SG_ 1624 LV_Fernlicht_Anzeige 5000;
BA_REL_ "GenSigTimeoutTime" BU_SG_REL_ DashCAM SG_ 1624 LV_Abblendlicht_li_def 5000;
BA_REL_ "GenSigTimeoutTime" BU_SG_REL_ DashCAM SG_ 1624 LV_Abblendlicht_re_def 5000;
BA_REL_ "GenSigTimeoutTime" BU_SG_REL_ Gateway_Max SG_ 2549088371 Info_El_Nachlauftyp 5000;
BA_REL_ "GenSigTimeoutTime" BU_SG_REL_ Gateway_Max SG_ 2549088371 KN_Info_El_DiagPfad 5000;
BA_REL_ "GenSigTimeoutTime" BU_SG_REL_ Gateway_Max SG_ 2549088371 Info_El_KD_Fehler 2500;
BA_REL_ "GenSigTimeoutTime" BU_SG_REL_ Gateway_Max SG_ 2549088420 LSH_Nachlauftyp 5000;
BA_REL_ "GenSigTimeoutTime" BU_SG_REL_ Gateway_Max SG_ 2549088420 KN_LSH_DiagPfad 5000;
BA_REL_ "GenSigTimeoutTime" BU_SG_REL_ Gateway_Max SG_ 2549088420 LSH_KD_Fehler 2500;
BA_REL_ "GenSigTimeoutTime" BU_SG_REL_ Gateway_Max SG_ 2549088267 RDK_Nachlauftyp 5000;
BA_REL_ "GenSigTimeoutTime" BU_SG_REL_ Gateway_Max SG_ 2549088267 KN_RDK_DiagPfad 5000;
BA_REL_ "GenSigTimeoutTime" BU_SG_REL_ Gateway_Max SG_ 2549088267 RDK_KD_Fehler 2500;
BA_REL_ "GenSigTimeoutTime" BU_SG_REL_ Gateway_Max SG_ 2549088362 STH_Nachlauftyp 5000;
BA_REL_ "GenSigTimeoutTime" BU_SG_REL_ Gateway_Max SG_ 2549088362 KN_STH_DiagPfad 5000;
BA_REL_ "GenSigTimeoutTime" BU_SG_REL_ Gateway_Max SG_ 2549088362 STH_KD_Fehler 2500;
BA_REL_ "GenSigTimeoutTime" BU_SG_REL_ Gateway_Max SG_ 2527679633 LSH_LED 2000;
BA_REL_ "GenSigTimeoutTime" BU_SG_REL_ ICC_IO_Node SG_ 2527679639 AuthTime_Trigger_Distribution 5000;
BA_REL_ "GenSigTimeoutTime" BU_SG_REL_ ICC_IO_Node SG_ 1164 MFG_Infotainment_Autark 2000;
BA_REL_ "GenSigTimeoutTime" BU_SG_REL_ ICC_IO_Node SG_ 1471 MFL_Tastencode_1 5000;
BA_REL_ "GenSigTimeoutTime" BU_SG_REL_ ICC_IO_Node SG_ 1471 MFL_Tastencode_2 5000;
BA_REL_ "GenSigTimeoutTime" BU_SG_REL_ ICC_IO_Node SG_ 1471 MFL_Eventcode_1 5000;
BA_REL_ "GenSigTimeoutTime" BU_SG_REL_ ICC_IO_Node SG_ 1471 MFL_Eventcode_2 5000;
BA_REL_ "GenSigTimeoutTime" BU_SG_REL_ ICC_IO_Node SG_ 1471 MFL_Marke 5000;
BA_REL_ "GenSigTimeoutTime" BU_SG_REL_ ICC_IO_Node SG_ 1471 MFL_Variante 5000;
BA_REL_ "GenSigTimeoutTime" BU_SG_REL_ LSH SG_ 779 KBI_Tankwarnung 500;
BA_REL_ "GenSigTimeoutTime" BU_SG_REL_ LSH SG_ 1719 KBI_Inhalt_Tank 5000;
BA_REL_ "GenSigTimeoutTime" BU_SG_REL_ LSH SG_ 1719 KBI_QBit_Aussen_Temp_gef 5000;
BA_REL_ "GenSigTimeoutTime" BU_SG_REL_ LSH SG_ 1719 KBI_Aussen_Temp_gef 5000;
BA_REL_ "GenSigTimeoutTime" BU_SG_REL_ LSH SG_ 1165 MFG_Heizstufe_LSH 2000;
BA_REL_ "GenSigTimeoutTime" BU_SG_REL_ LSH SG_ 1165 MFG_Zuheizer_Freigabe 2000;
BA_REL_ "GenSigTimeoutTime" BU_SG_REL_ LSH SG_ 1164 MFG_Klappe_Status 2000;
BA_REL_ "GenSigTimeoutTime" BU_SG_REL_ LSH SG_ 1164 MFG_LSH_DBetr_Ein 2000;
BA_REL_ "GenSigTimeoutTime" BU_SG_REL_ LSH SG_ 1164 MFG_LSH_Betriebsdauer 2000;
BA_REL_ "GenSigTimeoutTime" BU_SG_REL_ LSH SG_ 1164 MFG_LSH_DBetr_Bestaet 2000;
BA_REL_ "GenSigTimeoutTime" BU_SG_REL_ LSH SG_ 1164 MFG_LSH_Ansteuerung 2000;
BA_REL_ "GenSigTimeoutTime" BU_SG_REL_ LSH SG_ 1164 MF_2BattAb 2000;
BA_REL_ "GenSigTimeoutTime" BU_SG_REL_ LSH SG_ 1164 MF_LSH_Abschaltstufe 2000;
BA_REL_ "GenSigTimeoutTime" BU_SG_REL_ LSH SG_ 1164 MF_LSH_Einschaltverbot 2000;
BA_REL_ "GenSigTimeoutTime" BU_SG_REL_ OCU SG_ 779 KBI_Vorglueh_System_Lampe 500;
BA_REL_ "GenSigTimeoutTime" BU_SG_REL_ OCU SG_ 779 KBI_Anzeigestatus_ACC 500;
BA_REL_ "GenSigTimeoutTime" BU_SG_REL_ OCU SG_ 779 KBI_Anzeigestatus_GRA 500;
BA_REL_ "GenSigTimeoutTime" BU_SG_REL_ OCU SG_ 779 KBI_Tankwarnung 500;
BA_REL_ "GenSigTimeoutTime" BU_SG_REL_ OCU SG_ 779 KBI_MFA_v_Einheit_01 500;
BA_REL_ "GenSigTimeoutTime" BU_SG_REL_ OCU SG_ 779 KBI_Tankwarnung_ungueltig 500;
BA_REL_ "GenSigTimeoutTime" BU_SG_REL_ OCU SG_ 779 KBI_Oeldruckwarnung 500;
BA_REL_ "GenSigTimeoutTime" BU_SG_REL_ OCU SG_ 779 KBI_Handbremse 500;
BA_REL_ "GenSigTimeoutTime" BU_SG_REL_ OCU SG_ 779 KBI_V_Digital 500;
BA_REL_ "GenSigTimeoutTime" BU_SG_REL_ OCU SG_ 779 KBI_Anzeigestatus_LIM 500;
BA_REL_ "GenSigTimeoutTime" BU_SG_REL_ OCU SG_ 779 KBI_Audioabsenkung_MIB 500;
BA_REL_ "GenSigTimeoutTime" BU_SG_REL_ OCU SG_ 779 KBI_angez_Geschw 500;
BA_REL_ "GenSigTimeoutTime" BU_SG_REL_ OCU SG_ 1719 KBI_Kilometerstand 5000;
BA_REL_ "GenSigTimeoutTime" BU_SG_REL_ OCU SG_ 1719 KBI_Standzeit_02 5000;
BA_REL_ "GenSigTimeoutTime" BU_SG_REL_ OCU SG_ 1719 KBI_Inhalt_Tank 5000;
BA_REL_ "GenSigTimeoutTime" BU_SG_REL_ OCU SG_ 1719 KBI_FStatus_Tank 5000;
BA_REL_ "GenSigTimeoutTime" BU_SG_REL_ OCU SG_ 1719 KBI_FoD_PopUP_Quittiert 5000;
BA_REL_ "GenSigTimeoutTime" BU_SG_REL_ OCU SG_ 1719 KBI_QBit_Aussen_Temp_gef 5000;
BA_REL_ "GenSigTimeoutTime" BU_SG_REL_ OCU SG_ 1719 KBI_Aussen_Temp_gef 5000;
BA_REL_ "GenSigTimeoutTime" BU_SG_REL_ OCU SG_ 1720 KBI_Tankfuellstand_Prozent 5000;
BA_REL_ "GenSigTimeoutTime" BU_SG_REL_ OCU SG_ 1720 KBI_Nachtanken_erkannt 5000;
BA_REL_ "GenSigTimeoutTime" BU_SG_REL_ OCU SG_ 1720 KBI_Tankinhalt_hochaufl 5000;
BA_REL_ "GenSigTimeoutTime" BU_SG_REL_ OCU SG_ 1720 KBI_Max_Tankinhalt 5000;
BA_REL_ "GenSigTimeoutTime" BU_SG_REL_ OCU SG_ 2527679639 KBI_Min_Tankinhalt 5000;
BA_REL_ "GenSigTimeoutTime" BU_SG_REL_ OCU SG_ 2527679639 AuthTime_Trigger_Distribution 5000;
BA_REL_ "GenSigTimeoutTime" BU_SG_REL_ OCU SG_ 110 EPS_QBit_Zahnstangen_Pos 1000;
BA_REL_ "GenSigTimeoutTime" BU_SG_REL_ OCU SG_ 110 EPS_Zahnstangen_Pos_02 1000;
BA_REL_ "GenSigTimeoutTime" BU_SG_REL_ OCU SG_ 110 EPS_VZ_Zahnstangenposition 1000;
BA_REL_ "GenSigTimeoutTime" BU_SG_REL_ OCU SG_ 981 BCM1_Standlicht_Anf 1000;
BA_REL_ "GenSigTimeoutTime" BU_SG_REL_ OCU SG_ 981 BCM1_Abblendlicht_Anf 1000;
BA_REL_ "GenSigTimeoutTime" BU_SG_REL_ OCU SG_ 981 BCM1_Fernlicht_Anf 1000;
BA_REL_ "GenSigTimeoutTime" BU_SG_REL_ OCU SG_ 981 BCM1_Nebellicht_Anf 1000;
BA_REL_ "GenSigTimeoutTime" BU_SG_REL_ OCU SG_ 981 BCM1_Parklicht_li_Anf 1000;
BA_REL_ "GenSigTimeoutTime" BU_SG_REL_ OCU SG_ 981 BCM1_Parklicht_re_Anf 1000;
BA_REL_ "GenSigTimeoutTime" BU_SG_REL_ OCU SG_ 981 BCM1_Nebelschluss_Fzg_Anf 1000;
BA_REL_ "GenSigTimeoutTime" BU_SG_REL_ OCU SG_ 981 BCM_Rueckfahrlicht_Anf 1000;
BA_REL_ "GenSigTimeoutTime" BU_SG_REL_ OCU SG_ 982 LH_Bremslicht_H_aktiv 1000;
BA_REL_ "GenSigTimeoutTime" BU_SG_REL_ OCU SG_ 982 LH_Blinker_li_def 1000;
BA_REL_ "GenSigTimeoutTime" BU_SG_REL_ OCU SG_ 982 LH_Bremsl_li_def 1000;
BA_REL_ "GenSigTimeoutTime" BU_SG_REL_ OCU SG_ 982 LH_Schlusslicht_li_def 1000;
BA_REL_ "GenSigTimeoutTime" BU_SG_REL_ OCU SG_ 982 LH_Rueckf_li_def 1000;
BA_REL_ "GenSigTimeoutTime" BU_SG_REL_ OCU SG_ 982 LH_Nebel_li_def 1000;
BA_REL_ "GenSigTimeoutTime" BU_SG_REL_ OCU SG_ 982 LH_Schluss_Brems_Nebel_li_def 1000;
BA_REL_ "GenSigTimeoutTime" BU_SG_REL_ OCU SG_ 982 LH_Schluss_Brems_Nebel_re_def 1000;
BA_REL_ "GenSigTimeoutTime" BU_SG_REL_ OCU SG_ 982 LH_Zusatzschlussl_def 1000;
BA_REL_ "GenSigTimeoutTime" BU_SG_REL_ OCU SG_ 982 LH_Schluss_Brems_li_def 1000;
BA_REL_ "GenSigTimeoutTime" BU_SG_REL_ OCU SG_ 982 LH_Schluss_Nebel_li_def 1000;
BA_REL_ "GenSigTimeoutTime" BU_SG_REL_ OCU SG_ 982 LH_SL_BRL_BLK_li_def 1000;
BA_REL_ "GenSigTimeoutTime" BU_SG_REL_ OCU SG_ 982 LH_Brems_Blk_li_def 1000;
BA_REL_ "GenSigTimeoutTime" BU_SG_REL_ OCU SG_ 982 LH_Diag_Status_re_def 1000;
BA_REL_ "GenSigTimeoutTime" BU_SG_REL_ OCU SG_ 982 LH_Diag_Status_li_def 1000;
BA_REL_ "GenSigTimeoutTime" BU_SG_REL_ OCU SG_ 982 LH_Diag_LED_li_def 1000;
BA_REL_ "GenSigTimeoutTime" BU_SG_REL_ OCU SG_ 982 LH_Diag_LED_re_def 1000;
BA_REL_ "GenSigTimeoutTime" BU_SG_REL_ OCU SG_ 982 LH_Blinker_re_def 1000;
BA_REL_ "GenSigTimeoutTime" BU_SG_REL_ OCU SG_ 982 LH_Bremsl_re_def 1000;
BA_REL_ "GenSigTimeoutTime" BU_SG_REL_ OCU SG_ 982 LH_Schlusslicht_re_def 1000;
BA_REL_ "GenSigTimeoutTime" BU_SG_REL_ OCU SG_ 982 LH_Rueckf_re_def 1000;
BA_REL_ "GenSigTimeoutTime" BU_SG_REL_ OCU SG_ 982 LH_Nebel_re_def 1000;
BA_REL_ "GenSigTimeoutTime" BU_SG_REL_ OCU SG_ 982 LH_Schluss_Brems_re_def 1000;
BA_REL_ "GenSigTimeoutTime" BU_SG_REL_ OCU SG_ 982 LH_Schluss_Nebel_re_def 1000;
BA_REL_ "GenSigTimeoutTime" BU_SG_REL_ OCU SG_ 982 LH_SL_BRL_BLK_re_def 1000;
BA_REL_ "GenSigTimeoutTime" BU_SG_REL_ OCU SG_ 982 LH_Brems_Blk_re_def 1000;
BA_REL_ "GenSigTimeoutTime" BU_SG_REL_ OCU SG_ 982 LH_Kennzl_def 1000;
BA_REL_ "GenSigTimeoutTime" BU_SG_REL_ OCU SG_ 982 LH_3_Bremsl_def 1000;
BA_REL_ "GenSigTimeoutTime" BU_SG_REL_ OCU SG_ 982 LH_Nebel_mi_def 1000;
BA_REL_ "GenSigTimeoutTime" BU_SG_REL_ OCU SG_ 982 LH_Bremsl_li_ges_def 1000;
BA_REL_ "GenSigTimeoutTime" BU_SG_REL_ OCU SG_ 982 LH_Bremsl_re_ges_def 1000;
BA_REL_ "GenSigTimeoutTime" BU_SG_REL_ OCU SG_ 1624 LV_Standlicht_Anzeige 5000;
BA_REL_ "GenSigTimeoutTime" BU_SG_REL_ OCU SG_ 1624 LV_Abblendlicht_Anzeige 5000;
BA_REL_ "GenSigTimeoutTime" BU_SG_REL_ OCU SG_ 1624 LV_Fernlicht_Anzeige 5000;
BA_REL_ "GenSigTimeoutTime" BU_SG_REL_ OCU SG_ 1624 LV_Nebellicht_Anzeige 5000;
BA_REL_ "GenSigTimeoutTime" BU_SG_REL_ OCU SG_ 1624 LV_Nebelschlusslicht_Anzeige 5000;
BA_REL_ "GenSigTimeoutTime" BU_SG_REL_ OCU SG_ 1624 LV_Tagfahrlicht_Anzeige 5000;
BA_REL_ "GenSigTimeoutTime" BU_SG_REL_ OCU SG_ 1624 LV_AFL_aktiv_Anzeige 5000;
BA_REL_ "GenSigTimeoutTime" BU_SG_REL_ OCU SG_ 1624 LV_AFL_defekt 5000;
BA_REL_ "GenSigTimeoutTime" BU_SG_REL_ OCU SG_ 1624 LV_Blinker_li_def 5000;
BA_REL_ "GenSigTimeoutTime" BU_SG_REL_ OCU SG_ 1624 LV_Standlicht_li_def 5000;
BA_REL_ "GenSigTimeoutTime" BU_SG_REL_ OCU SG_ 1624 LV_Abblendlicht_li_def 5000;
BA_REL_ "GenSigTimeoutTime" BU_SG_REL_ OCU SG_ 1624 LV_Fernlicht_li_def 5000;
BA_REL_ "GenSigTimeoutTime" BU_SG_REL_ OCU SG_ 1624 LV_Nebellicht_li_def 5000;
BA_REL_ "GenSigTimeoutTime" BU_SG_REL_ OCU SG_ 1624 LV_Blk_li_Seite_def 5000;
BA_REL_ "GenSigTimeoutTime" BU_SG_REL_ OCU SG_ 1624 LV_Tagfahrlicht_li_def 5000;
BA_REL_ "GenSigTimeoutTime" BU_SG_REL_ OCU SG_ 1624 LV_FLA_aktiv_Anzeige 5000;
BA_REL_ "GenSigTimeoutTime" BU_SG_REL_ OCU SG_ 1624 LV_FLA_defekt 5000;
BA_REL_ "GenSigTimeoutTime" BU_SG_REL_ OCU SG_ 1624 LV_Blinker_re_def 5000;
BA_REL_ "GenSigTimeoutTime" BU_SG_REL_ OCU SG_ 1624 LV_Standlicht_re_def 5000;
BA_REL_ "GenSigTimeoutTime" BU_SG_REL_ OCU SG_ 1624 LV_Abblendlicht_re_def 5000;
BA_REL_ "GenSigTimeoutTime" BU_SG_REL_ OCU SG_ 1624 LV_Fernlicht_re_def 5000;
BA_REL_ "GenSigTimeoutTime" BU_SG_REL_ OCU SG_ 1624 LV_Nebellicht_re_def 5000;
BA_REL_ "GenSigTimeoutTime" BU_SG_REL_ OCU SG_ 1624 LV_Blk_re_Seite_def 5000;
BA_REL_ "GenSigTimeoutTime" BU_SG_REL_ OCU SG_ 1624 LV_Tagfahrlicht_re_def 5000;
BA_REL_ "GenSigTimeoutTime" BU_SG_REL_ OCU SG_ 1624 LV_Aussenlicht_def 5000;
BA_REL_ "GenSigTimeoutTime" BU_SG_REL_ OCU SG_ 1624 LV_Abblendlicht_TFL_li_def 5000;
BA_REL_ "GenSigTimeoutTime" BU_SG_REL_ OCU SG_ 1624 LV_Nebellicht_TFL_li_def 5000;
BA_REL_ "GenSigTimeoutTime" BU_SG_REL_ OCU SG_ 1624 LV_Standlicht_TFL_li_def 5000;
BA_REL_ "GenSigTimeoutTime" BU_SG_REL_ OCU SG_ 1624 LV_Abblend_Fernlicht_li_def 5000;
BA_REL_ "GenSigTimeoutTime" BU_SG_REL_ OCU SG_ 1624 LV_Abblendlicht_TFL_re_def 5000;
BA_REL_ "GenSigTimeoutTime" BU_SG_REL_ OCU SG_ 1624 LV_Nebellicht_TFL_re_def 5000;
BA_REL_ "GenSigTimeoutTime" BU_SG_REL_ OCU SG_ 1624 LV_Standlicht_TFL_re_def 5000;
BA_REL_ "GenSigTimeoutTime" BU_SG_REL_ OCU SG_ 1624 LV_Abblend_Fernlicht_re_def 5000;
BA_REL_ "GenSigTimeoutTime" BU_SG_REL_ OCU SG_ 1624 LV_Abbiegelicht_li_def 5000;
BA_REL_ "GenSigTimeoutTime" BU_SG_REL_ OCU SG_ 1624 LV_Abbiegelicht_re_def 5000;
BA_REL_ "GenSigTimeoutTime" BU_SG_REL_ OCU SG_ 1624 LV_LED_Scheinwerfer_li_def 5000;
BA_REL_ "GenSigTimeoutTime" BU_SG_REL_ OCU SG_ 1624 LV_LED_Scheinwerfer_re_def 5000;
BA_REL_ "GenSigTimeoutTime" BU_SG_REL_ OCU SG_ 2463978598 LoGeWa_C2C_Event_Einheit 2000;
BA_REL_ "GenSigTimeoutTime" BU_SG_REL_ OCU SG_ 2463978598 LoGeWa_C2C_Event_Richtung 2000;
BA_REL_ "GenSigTimeoutTime" BU_SG_REL_ OCU SG_ 2463978598 LoGeWa_C2C_Event_Status 2000;
BA_REL_ "GenSigTimeoutTime" BU_SG_REL_ OCU SG_ 2463978598 LoGeWa_C2C_Event_Warnung 2000;
BA_REL_ "GenSigTimeoutTime" BU_SG_REL_ OCU SG_ 2463978598 LoGeWa_C2C_Event_Entfernung 2000;
BA_REL_ "GenSigTimeoutTime" BU_SG_REL_ OCU SG_ 2527679633 LSH_Geblaese_aktiv 2000;
BA_REL_ "GenSigTimeoutTime" BU_SG_REL_ OCU SG_ 2527679633 LSH_LED 2000;
BA_REL_ "GenSigTimeoutTime" BU_SG_REL_ OCU SG_ 2527679633 LSH_Servicemode 2000;
BA_REL_ "GenSigTimeoutTime" BU_SG_REL_ OCU SG_ 2527679633 LSH_Funk_aus 2000;
BA_REL_ "GenSigTimeoutTime" BU_SG_REL_ OCU SG_ 2527679633 LSH_Funk_ein 2000;
BA_REL_ "GenSigTimeoutTime" BU_SG_REL_ OCU SG_ 2527679633 LSH_Klappe_Status 2000;
BA_REL_ "GenSigTimeoutTime" BU_SG_REL_ OCU SG_ 2527679633 LSH_Start_folgt 2000;
BA_REL_ "GenSigTimeoutTime" BU_SG_REL_ OCU SG_ 2527679633 LSH_Heiztemp 2000;
BA_REL_ "GenSigTimeoutTime" BU_SG_REL_ OCU SG_ 2527679633 LSH_Empf_Heizstufe 2000;
BA_REL_ "GenSigTimeoutTime" BU_SG_REL_ OCU SG_ 2527679633 LSH_Texte 2000;
BA_REL_ "GenSigTimeoutTime" BU_SG_REL_ OCU SG_ 2527679633 LSH_Waermeeintrag 2000;
BA_REL_ "GenSigTimeoutTime" BU_SG_REL_ OCU SG_ 2527679633 LSH_Ansaug_Fuell_1 2000;
BA_REL_ "GenSigTimeoutTime" BU_SG_REL_ OCU SG_ 2527679633 LSH_Ansaug_Fuell_2 2000;
BA_REL_ "GenSigTimeoutTime" BU_SG_REL_ OCU SG_ 2527679634 LSH_KVS_Ueberlauf 2000;
BA_REL_ "GenSigTimeoutTime" BU_SG_REL_ OCU SG_ 2527679634 LSH_KVS 2000;
BA_REL_ "GenSigTimeoutTime" BU_SG_REL_ OCU SG_ 134 LWI_Sensorstatus 5000;
BA_REL_ "GenSigTimeoutTime" BU_SG_REL_ OCU SG_ 134 LWI_QBit_Lenkradwinkel 5000;
BA_REL_ "GenSigTimeoutTime" BU_SG_REL_ OCU SG_ 134 LWI_Lenkradwinkel 5000;
BA_REL_ "GenSigTimeoutTime" BU_SG_REL_ OCU SG_ 134 LWI_VZ_Lenkradwinkel 5000;
BA_REL_ "GenSigTimeoutTime" BU_SG_REL_ OCU SG_ 134 LWI_VZ_Lenkradw_Geschw 5000;
BA_REL_ "GenSigTimeoutTime" BU_SG_REL_ OCU SG_ 134 LWI_Lenkradw_Geschw 5000;
BA_REL_ "GenSigTimeoutTime" BU_SG_REL_ OCU SG_ 1153 Nav_FoD_Status 5000;
BA_REL_ "GenSigTimeoutTime" BU_SG_REL_ OCU SG_ 1153 MIB_ASW_Diagnose 5000;
BA_REL_ "GenSigTimeoutTime" BU_SG_REL_ OCU SG_ 1153 MIB_Tongenerator_PH_verfuegbar 5000;
BA_REL_ "GenSigTimeoutTime" BU_SG_REL_ OCU SG_ 1178 FS_Sitzfahrt_aktiv 1000;
BA_REL_ "GenSigTimeoutTime" BU_SG_REL_ OCU SG_ 1471 MFL_Tastencode_1 5000;
BA_REL_ "GenSigTimeoutTime" BU_SG_REL_ OCU SG_ 1471 MFL_Tastencode_2 5000;
BA_REL_ "GenSigTimeoutTime" BU_SG_REL_ OCU SG_ 1471 MFL_Eventcode_1 5000;
BA_REL_ "GenSigTimeoutTime" BU_SG_REL_ OCU SG_ 1471 MFL_Eventcode_2 5000;
BA_REL_ "GenSigTimeoutTime" BU_SG_REL_ OCU SG_ 1471 MFL_Marke 5000;
BA_REL_ "GenSigTimeoutTime" BU_SG_REL_ OCU SG_ 1471 MFL_Variante 5000;
BA_REL_ "GenSigTimeoutTime" BU_SG_REL_ RDK_RS3 SG_ 779 KBI_MFA_v_Einheit_01 500;
BA_REL_ "GenSigTimeoutTime" BU_SG_REL_ RDK_RS3 SG_ 779 KBI_V_Digital 500;
BA_REL_ "GenSigTimeoutTime" BU_SG_REL_ RDK_RS3 SG_ 1719 KBI_RDK_Kalibrier_Anf 5000;
BA_REL_ "GenSigTimeoutTime" BU_SG_REL_ RDK_RS3 SG_ 1719 KBI_QBit_Aussen_Temp_gef 5000;
BA_REL_ "GenSigTimeoutTime" BU_SG_REL_ RDK_RS3 SG_ 1719 KBI_Aussen_Temp_gef 5000;
BA_REL_ "GenSigTimeoutTime" BU_SG_REL_ STH SG_ 779 KBI_Tankwarnung 500;
BA_REL_ "GenSigTimeoutTime" BU_SG_REL_ STH SG_ 1719 KBI_Inhalt_Tank 5000;
BA_REL_ "GenSigTimeoutTime" BU_SG_REL_ STH SG_ 1719 KBI_Aussen_Temp_gef 5000;
BA_REL_ "GenSigTimeoutTime" BU_SG_REL_ STH SG_ 2527679633 LSH_LED 2000;
BA_REL_ "GenSigTimeoutTime" BU_SG_REL_ STH SG_ 2527679634 LSH_Fehlerstatus 2000;
BA_REL_ "GenSigTimeoutTime" BU_SG_REL_ ZR_MIB_EINSTIEG_ab_Gen3 SG_ 779 KBI_Tankwarnung 500;
BA_REL_ "GenSigTimeoutTime" BU_SG_REL_ ZR_MIB_EINSTIEG_ab_Gen3 SG_ 779 KBI_MFA_v_Einheit_01 500;
BA_REL_ "GenSigTimeoutTime" BU_SG_REL_ ZR_MIB_EINSTIEG_ab_Gen3 SG_ 779 KBI_Handbremse 500;
BA_REL_ "GenSigTimeoutTime" BU_SG_REL_ ZR_MIB_EINSTIEG_ab_Gen3 SG_ 779 KBI_V_Digital 500;
BA_REL_ "GenSigTimeoutTime" BU_SG_REL_ ZR_MIB_EINSTIEG_ab_Gen3 SG_ 779 KBI_angez_Geschw 500;
BA_REL_ "GenSigTimeoutTime" BU_SG_REL_ ZR_MIB_EINSTIEG_ab_Gen3 SG_ 1719 KBI_Standzeit_02 5000;
BA_REL_ "GenSigTimeoutTime" BU_SG_REL_ ZR_MIB_EINSTIEG_ab_Gen3 SG_ 1719 KBI_Reserve_Warnung_Sek 5000;
BA_REL_ "GenSigTimeoutTime" BU_SG_REL_ ZR_MIB_EINSTIEG_ab_Gen3 SG_ 1719 KBI_FStatus_Tank 5000;
BA_REL_ "GenSigTimeoutTime" BU_SG_REL_ ZR_MIB_EINSTIEG_ab_Gen3 SG_ 1719 KBI_QBit_Aussen_Temp_gef 5000;
BA_REL_ "GenSigTimeoutTime" BU_SG_REL_ ZR_MIB_EINSTIEG_ab_Gen3 SG_ 1719 KBI_Aussen_Temp_gef 5000;
BA_REL_ "GenSigTimeoutTime" BU_SG_REL_ ZR_MIB_EINSTIEG_ab_Gen3 SG_ 1720 KBI_Reifenumfang 5000;
BA_REL_ "GenSigTimeoutTime" BU_SG_REL_ ZR_MIB_EINSTIEG_ab_Gen3 SG_ 2527679639 KBI_Weg_Zaehler_F 5000;
BA_REL_ "GenSigTimeoutTime" BU_SG_REL_ ZR_MIB_EINSTIEG_ab_Gen3 SG_ 2527679639 KBI_Weg_Zaehler 5000;
BA_REL_ "GenSigTimeoutTime" BU_SG_REL_ ZR_MIB_EINSTIEG_ab_Gen3 SG_ 2527679639 AuthTime_Trigger_Distribution 5000;
BA_REL_ "GenSigTimeoutTime" BU_SG_REL_ ZR_MIB_EINSTIEG_ab_Gen3 SG_ 2527679656 KBI_StartupAnimation 5000;
BA_REL_ "GenSigTimeoutTime" BU_SG_REL_ ZR_MIB_EINSTIEG_ab_Gen3 SG_ 981 BCM1_Kurvenlicht_links_Anf 1000;
BA_REL_ "GenSigTimeoutTime" BU_SG_REL_ ZR_MIB_EINSTIEG_ab_Gen3 SG_ 981 BCM1_Kurvenlicht_rechts_Anf 1000;
BA_REL_ "GenSigTimeoutTime" BU_SG_REL_ ZR_MIB_EINSTIEG_ab_Gen3 SG_ 981 BCM1_Standlicht_Anf 1000;
BA_REL_ "GenSigTimeoutTime" BU_SG_REL_ ZR_MIB_EINSTIEG_ab_Gen3 SG_ 981 BCM1_Abblendlicht_Anf 1000;
BA_REL_ "GenSigTimeoutTime" BU_SG_REL_ ZR_MIB_EINSTIEG_ab_Gen3 SG_ 981 BCM1_Fernlicht_Anf 1000;
BA_REL_ "GenSigTimeoutTime" BU_SG_REL_ ZR_MIB_EINSTIEG_ab_Gen3 SG_ 981 BCM1_Nebellicht_Anf 1000;
BA_REL_ "GenSigTimeoutTime" BU_SG_REL_ ZR_MIB_EINSTIEG_ab_Gen3 SG_ 981 BCM1_Parklicht_li_Anf 1000;
BA_REL_ "GenSigTimeoutTime" BU_SG_REL_ ZR_MIB_EINSTIEG_ab_Gen3 SG_ 981 BCM1_Parklicht_re_Anf 1000;
BA_REL_ "GenSigTimeoutTime" BU_SG_REL_ ZR_MIB_EINSTIEG_ab_Gen3 SG_ 981 BCM1_Nebelschluss_Fzg_Anf 1000;
BA_REL_ "GenSigTimeoutTime" BU_SG_REL_ ZR_MIB_EINSTIEG_ab_Gen3 SG_ 981 BCM_Rueckfahrlicht_Anf 1000;
BA_REL_ "GenSigTimeoutTime" BU_SG_REL_ ZR_MIB_EINSTIEG_ab_Gen3 SG_ 981 BCM1_Tagfahrlicht_Anf 1000;
BA_REL_ "GenSigTimeoutTime" BU_SG_REL_ ZR_MIB_EINSTIEG_ab_Gen3 SG_ 981 BCM1_GLW_Fernlicht_Anf 1000;
BA_REL_ "GenSigTimeoutTime" BU_SG_REL_ ZR_MIB_EINSTIEG_ab_Gen3 SG_ 982 LH_Bremslicht_H_aktiv 1000;
BA_REL_ "GenSigTimeoutTime" BU_SG_REL_ ZR_MIB_EINSTIEG_ab_Gen3 SG_ 1624 LV_Abblendlicht_Anzeige 5000;
BA_REL_ "GenSigTimeoutTime" BU_SG_REL_ ZR_MIB_EINSTIEG_ab_Gen3 SG_ 1624 LV_Fernlicht_Anzeige 5000;
BA_REL_ "GenSigTimeoutTime" BU_SG_REL_ ZR_MIB_EINSTIEG_ab_Gen3 SG_ 1624 LV_Nebellicht_Anzeige 5000;
BA_REL_ "GenSigTimeoutTime" BU_SG_REL_ ZR_MIB_EINSTIEG_ab_Gen3 SG_ 1624 LV_Nebelschlusslicht_Anzeige 5000;
BA_REL_ "GenSigTimeoutTime" BU_SG_REL_ ZR_MIB_EINSTIEG_ab_Gen3 SG_ 1164 MFG_Infotainment_Autark 2000;
BA_REL_ "GenSigTimeoutTime" BU_SG_REL_ ZR_MIB_EINSTIEG_ab_Gen3 SG_ 1164 MF_Radiomute 2000;
BA_REL_ "GenSigTimeoutTime" BU_SG_REL_ ZR_MIB_EINSTIEG_ab_Gen3 SG_ 1164 MFG_AppConnect_Anf 2000;
BA_REL_ "GenSigTimeoutTime" BU_SG_REL_ ZR_MIB_EINSTIEG_ab_Gen3 SG_ 1471 MFL_Tastencode_1 5000;
BA_REL_ "GenSigTimeoutTime" BU_SG_REL_ ZR_MIB_EINSTIEG_ab_Gen3 SG_ 1471 MFL_Tastencode_2 5000;
BA_REL_ "GenSigTimeoutTime" BU_SG_REL_ ZR_MIB_EINSTIEG_ab_Gen3 SG_ 1471 MFL_Eventcode_1 5000;
BA_REL_ "GenSigTimeoutTime" BU_SG_REL_ ZR_MIB_EINSTIEG_ab_Gen3 SG_ 1471 MFL_Eventcode_2 5000;
BA_REL_ "GenSigTimeoutTime" BU_SG_REL_ ZR_MIB_EINSTIEG_ab_Gen3 SG_ 1471 MFL_Marke 5000;
BA_REL_ "GenSigTimeoutTime" BU_SG_REL_ ZR_MIB_EINSTIEG_ab_Gen3 SG_ 1471 MFL_Variante 5000;
BA_REL_ "GenSigTimeoutTime" BU_SG_REL_ ZR_MIB_OPTION_ab_Gen3 SG_ 779 KBI_Tankwarnung 500;
BA_REL_ "GenSigTimeoutTime" BU_SG_REL_ ZR_MIB_OPTION_ab_Gen3 SG_ 779 KBI_MFA_v_Einheit_01 500;
BA_REL_ "GenSigTimeoutTime" BU_SG_REL_ ZR_MIB_OPTION_ab_Gen3 SG_ 779 KBI_Handbremse 500;
BA_REL_ "GenSigTimeoutTime" BU_SG_REL_ ZR_MIB_OPTION_ab_Gen3 SG_ 779 KBI_V_Digital 500;
BA_REL_ "GenSigTimeoutTime" BU_SG_REL_ ZR_MIB_OPTION_ab_Gen3 SG_ 1719 KBI_Reserve_Warnung_Sek 5000;
BA_REL_ "GenSigTimeoutTime" BU_SG_REL_ ZR_MIB_OPTION_ab_Gen3 SG_ 1719 KBI_FStatus_Tank 5000;
BA_REL_ "GenSigTimeoutTime" BU_SG_REL_ ZR_MIB_OPTION_ab_Gen3 SG_ 1719 KBI_QBit_Aussen_Temp_gef 5000;
BA_REL_ "GenSigTimeoutTime" BU_SG_REL_ ZR_MIB_OPTION_ab_Gen3 SG_ 1719 KBI_Aussen_Temp_gef 5000;
BA_REL_ "GenSigTimeoutTime" BU_SG_REL_ ZR_MIB_OPTION_ab_Gen3 SG_ 1720 KBI_Reifenumfang 5000;
BA_REL_ "GenSigTimeoutTime" BU_SG_REL_ ZR_MIB_OPTION_ab_Gen3 SG_ 2527679639 KBI_Weg_Zaehler_F 5000;
BA_REL_ "GenSigTimeoutTime" BU_SG_REL_ ZR_MIB_OPTION_ab_Gen3 SG_ 2527679639 KBI_Weg_Zaehler 5000;
BA_REL_ "GenSigTimeoutTime" BU_SG_REL_ ZR_MIB_OPTION_ab_Gen3 SG_ 2527679639 AuthTime_Trigger_Distribution 5000;
BA_REL_ "GenSigTimeoutTime" BU_SG_REL_ ZR_MIB_OPTION_ab_Gen3 SG_ 2589283935 KBI_View1 5000;
BA_REL_ "GenSigTimeoutTime" BU_SG_REL_ ZR_MIB_OPTION_ab_Gen3 SG_ 2589283935 KBI_View2 5000;
BA_REL_ "GenSigTimeoutTime" BU_SG_REL_ ZR_MIB_OPTION_ab_Gen3 SG_ 2589283935 KBI_View3 5000;
BA_REL_ "GenSigTimeoutTime" BU_SG_REL_ ZR_MIB_OPTION_ab_Gen3 SG_ 2589283935 KBI_View4 5000;
BA_REL_ "GenSigTimeoutTime" BU_SG_REL_ ZR_MIB_OPTION_ab_Gen3 SG_ 2589283935 KBI_View5 5000;
BA_REL_ "GenSigTimeoutTime" BU_SG_REL_ ZR_MIB_OPTION_ab_Gen3 SG_ 2589283935 KBI_View6 5000;
BA_REL_ "GenSigTimeoutTime" BU_SG_REL_ ZR_MIB_OPTION_ab_Gen3 SG_ 2589283935 KBI_View7 5000;
BA_REL_ "GenSigTimeoutTime" BU_SG_REL_ ZR_MIB_OPTION_ab_Gen3 SG_ 2589283935 KBI_View8 5000;
BA_REL_ "GenSigTimeoutTime" BU_SG_REL_ ZR_MIB_OPTION_ab_Gen3 SG_ 2589283935 KBI_View9 5000;
BA_REL_ "GenSigTimeoutTime" BU_SG_REL_ ZR_MIB_OPTION_ab_Gen3 SG_ 2589283935 KBI_View10 5000;
BA_REL_ "GenSigTimeoutTime" BU_SG_REL_ ZR_MIB_OPTION_ab_Gen3 SG_ 2589283935 KBI_View11 5000;
BA_REL_ "GenSigTimeoutTime" BU_SG_REL_ ZR_MIB_OPTION_ab_Gen3 SG_ 2589283935 KBI_View12 5000;
BA_REL_ "GenSigTimeoutTime" BU_SG_REL_ ZR_MIB_OPTION_ab_Gen3 SG_ 2589283935 KBI_View13 5000;
BA_REL_ "GenSigTimeoutTime" BU_SG_REL_ ZR_MIB_OPTION_ab_Gen3 SG_ 2589283935 KBI_View14 5000;
BA_REL_ "GenSigTimeoutTime" BU_SG_REL_ ZR_MIB_OPTION_ab_Gen3 SG_ 2589283935 KBI_View15 5000;
BA_REL_ "GenSigTimeoutTime" BU_SG_REL_ ZR_MIB_OPTION_ab_Gen3 SG_ 2589283935 KBI_View16 5000;
BA_REL_ "GenSigTimeoutTime" BU_SG_REL_ ZR_MIB_OPTION_ab_Gen3 SG_ 2589283935 KBI_View17 5000;
BA_REL_ "GenSigTimeoutTime" BU_SG_REL_ ZR_MIB_OPTION_ab_Gen3 SG_ 2589283935 KBI_View18 5000;
BA_REL_ "GenSigTimeoutTime" BU_SG_REL_ ZR_MIB_OPTION_ab_Gen3 SG_ 2589283935 KBI_View19 5000;
BA_REL_ "GenSigTimeoutTime" BU_SG_REL_ ZR_MIB_OPTION_ab_Gen3 SG_ 2589283935 KBI_View20 5000;
BA_REL_ "GenSigTimeoutTime" BU_SG_REL_ ZR_MIB_OPTION_ab_Gen3 SG_ 2589283935 KBI_View21 5000;
BA_REL_ "GenSigTimeoutTime" BU_SG_REL_ ZR_MIB_OPTION_ab_Gen3 SG_ 2589283935 KBI_View22 5000;
BA_REL_ "GenSigTimeoutTime" BU_SG_REL_ ZR_MIB_OPTION_ab_Gen3 SG_ 2589283935 KBI_View23 5000;
BA_REL_ "GenSigTimeoutTime" BU_SG_REL_ ZR_MIB_OPTION_ab_Gen3 SG_ 2589283935 KBI_View24 5000;
BA_REL_ "GenSigTimeoutTime" BU_SG_REL_ ZR_MIB_OPTION_ab_Gen3 SG_ 2589283935 KBI_Curr_View 5000;
BA_REL_ "GenSigTimeoutTime" BU_SG_REL_ ZR_MIB_OPTION_ab_Gen3 SG_ 2589283935 KBI_Sec_View_Status 5000;
BA_REL_ "GenSigTimeoutTime" BU_SG_REL_ ZR_MIB_OPTION_ab_Gen3 SG_ 110 EPS_Sensorikstatus 1000;
BA_REL_ "GenSigTimeoutTime" BU_SG_REL_ ZR_MIB_OPTION_ab_Gen3 SG_ 110 EPS_QBit_Zahnstangen_Pos 1000;
BA_REL_ "GenSigTimeoutTime" BU_SG_REL_ ZR_MIB_OPTION_ab_Gen3 SG_ 110 EPS_Zahnstangen_Pos_02 1000;
BA_REL_ "GenSigTimeoutTime" BU_SG_REL_ ZR_MIB_OPTION_ab_Gen3 SG_ 110 EPS_VZ_Zahnstangenposition 1000;
BA_REL_ "GenSigTimeoutTime" BU_SG_REL_ ZR_MIB_OPTION_ab_Gen3 SG_ 981 BCM1_Kurvenlicht_links_Anf 1000;
BA_REL_ "GenSigTimeoutTime" BU_SG_REL_ ZR_MIB_OPTION_ab_Gen3 SG_ 981 BCM1_Kurvenlicht_rechts_Anf 1000;
BA_REL_ "GenSigTimeoutTime" BU_SG_REL_ ZR_MIB_OPTION_ab_Gen3 SG_ 981 BCM1_Standlicht_Anf 1000;
BA_REL_ "GenSigTimeoutTime" BU_SG_REL_ ZR_MIB_OPTION_ab_Gen3 SG_ 981 BCM1_Abblendlicht_Anf 1000;
BA_REL_ "GenSigTimeoutTime" BU_SG_REL_ ZR_MIB_OPTION_ab_Gen3 SG_ 981 BCM1_Fernlicht_Anf 1000;
BA_REL_ "GenSigTimeoutTime" BU_SG_REL_ ZR_MIB_OPTION_ab_Gen3 SG_ 981 BCM1_Nebellicht_Anf 1000;
BA_REL_ "GenSigTimeoutTime" BU_SG_REL_ ZR_MIB_OPTION_ab_Gen3 SG_ 981 BCM1_Parklicht_li_Anf 1000;
BA_REL_ "GenSigTimeoutTime" BU_SG_REL_ ZR_MIB_OPTION_ab_Gen3 SG_ 981 BCM1_Parklicht_re_Anf 1000;
BA_REL_ "GenSigTimeoutTime" BU_SG_REL_ ZR_MIB_OPTION_ab_Gen3 SG_ 981 BCM1_Nebelschluss_Fzg_Anf 1000;
BA_REL_ "GenSigTimeoutTime" BU_SG_REL_ ZR_MIB_OPTION_ab_Gen3 SG_ 981 BCM_Rueckfahrlicht_Anf 1000;
BA_REL_ "GenSigTimeoutTime" BU_SG_REL_ ZR_MIB_OPTION_ab_Gen3 SG_ 981 BCM1_Tagfahrlicht_Anf 1000;
BA_REL_ "GenSigTimeoutTime" BU_SG_REL_ ZR_MIB_OPTION_ab_Gen3 SG_ 981 BCM1_GLW_Fernlicht_Anf 1000;
BA_REL_ "GenSigTimeoutTime" BU_SG_REL_ ZR_MIB_OPTION_ab_Gen3 SG_ 982 LH_Bremslicht_H_aktiv 1000;
BA_REL_ "GenSigTimeoutTime" BU_SG_REL_ ZR_MIB_OPTION_ab_Gen3 SG_ 1624 LV_Abblendlicht_Anzeige 5000;
BA_REL_ "GenSigTimeoutTime" BU_SG_REL_ ZR_MIB_OPTION_ab_Gen3 SG_ 1624 LV_Fernlicht_Anzeige 5000;
BA_REL_ "GenSigTimeoutTime" BU_SG_REL_ ZR_MIB_OPTION_ab_Gen3 SG_ 1624 LV_Nebellicht_Anzeige 5000;
BA_REL_ "GenSigTimeoutTime" BU_SG_REL_ ZR_MIB_OPTION_ab_Gen3 SG_ 1624 LV_Nebelschlusslicht_Anzeige 5000;
BA_REL_ "GenSigTimeoutTime" BU_SG_REL_ ZR_MIB_OPTION_ab_Gen3 SG_ 1164 MFG_Infotainment_Autark 2000;
BA_REL_ "GenSigTimeoutTime" BU_SG_REL_ ZR_MIB_OPTION_ab_Gen3 SG_ 1164 MF_Radiomute 2000;
BA_REL_ "GenSigTimeoutTime" BU_SG_REL_ ZR_MIB_OPTION_ab_Gen3 SG_ 1471 MFL_Tastencode_1 5000;
BA_REL_ "GenSigTimeoutTime" BU_SG_REL_ ZR_MIB_OPTION_ab_Gen3 SG_ 1471 MFL_Tastencode_2 5000;
BA_REL_ "GenSigTimeoutTime" BU_SG_REL_ ZR_MIB_OPTION_ab_Gen3 SG_ 1471 MFL_Eventcode_1 5000;
BA_REL_ "GenSigTimeoutTime" BU_SG_REL_ ZR_MIB_OPTION_ab_Gen3 SG_ 1471 MFL_Eventcode_2 5000;
BA_REL_ "GenSigTimeoutTime" BU_SG_REL_ ZR_MIB_OPTION_ab_Gen3 SG_ 1471 MFL_Marke 5000;
BA_REL_ "GenSigTimeoutTime" BU_SG_REL_ ZR_MIB_OPTION_ab_Gen3 SG_ 1471 MFL_Variante 5000;
BA_REL_ "GenSigTimeoutTime" BU_SG_REL_ ZR_MIB_TOP_ab_Gen3 SG_ 779 KBI_Tankwarnung 500;
BA_REL_ "GenSigTimeoutTime" BU_SG_REL_ ZR_MIB_TOP_ab_Gen3 SG_ 779 KBI_MFA_v_Einheit_01 500;
BA_REL_ "GenSigTimeoutTime" BU_SG_REL_ ZR_MIB_TOP_ab_Gen3 SG_ 779 KBI_Tankwarnung_ungueltig 500;
BA_REL_ "GenSigTimeoutTime" BU_SG_REL_ ZR_MIB_TOP_ab_Gen3 SG_ 779 KBI_Handbremse 500;
BA_REL_ "GenSigTimeoutTime" BU_SG_REL_ ZR_MIB_TOP_ab_Gen3 SG_ 779 KBI_V_Digital 500;
BA_REL_ "GenSigTimeoutTime" BU_SG_REL_ ZR_MIB_TOP_ab_Gen3 SG_ 779 KBI_angez_Geschw 500;
BA_REL_ "GenSigTimeoutTime" BU_SG_REL_ ZR_MIB_TOP_ab_Gen3 SG_ 1719 KBI_Standzeit_02 5000;
BA_REL_ "GenSigTimeoutTime" BU_SG_REL_ ZR_MIB_TOP_ab_Gen3 SG_ 1719 KBI_Reserve_Warnung_Sek 5000;
BA_REL_ "GenSigTimeoutTime" BU_SG_REL_ ZR_MIB_TOP_ab_Gen3 SG_ 1719 KBI_FStatus_Tank 5000;
BA_REL_ "GenSigTimeoutTime" BU_SG_REL_ ZR_MIB_TOP_ab_Gen3 SG_ 1720 KBI_Reifenumfang 5000;
BA_REL_ "GenSigTimeoutTime" BU_SG_REL_ ZR_MIB_TOP_ab_Gen3 SG_ 1720 KBI_Nachtanken_erkannt 5000;
BA_REL_ "GenSigTimeoutTime" BU_SG_REL_ ZR_MIB_TOP_ab_Gen3 SG_ 2527679639 KBI_Weg_Zaehler_F 5000;
BA_REL_ "GenSigTimeoutTime" BU_SG_REL_ ZR_MIB_TOP_ab_Gen3 SG_ 2527679639 KBI_Weg_Zaehler 5000;
BA_REL_ "GenSigTimeoutTime" BU_SG_REL_ ZR_MIB_TOP_ab_Gen3 SG_ 2527679639 AuthTime_Trigger_Distribution 5000;
BA_REL_ "GenSigTimeoutTime" BU_SG_REL_ ZR_MIB_TOP_ab_Gen3 SG_ 981 BCM_Rueckfahrlicht_Anf 1000;
BA_REL_ "GenSigTimeoutTime" BU_SG_REL_ ZR_MIB_TOP_ab_Gen3 SG_ 981 BCM1_Tagfahrlicht_Anf 1000;
BA_REL_ "GenSigTimeoutTime" BU_SG_REL_ ZR_MIB_TOP_ab_Gen3 SG_ 1624 LV_Abblendlicht_Anzeige 5000;
BA_REL_ "GenSigTimeoutTime" BU_SG_REL_ ZR_MIB_TOP_ab_Gen3 SG_ 1624 LV_Fernlicht_Anzeige 5000;
BA_REL_ "GenSigTimeoutTime" BU_SG_REL_ ZR_MIB_TOP_ab_Gen3 SG_ 1624 LV_Nebellicht_Anzeige 5000;
BA_REL_ "GenSigTimeoutTime" BU_SG_REL_ ZR_MIB_TOP_ab_Gen3 SG_ 1624 LV_Nebelschlusslicht_Anzeige 5000;
BA_REL_ "GenSigTimeoutTime" BU_SG_REL_ ZR_MIB_TOP_ab_Gen3 SG_ 1164 MF_Radiomute 2000;
BA_REL_ "GenSigTimeoutTime" BU_SG_REL_ ZR_MIB_TOP_ab_Gen3 SG_ 1471 MFL_Tastencode_1 5000;
BA_REL_ "GenSigTimeoutTime" BU_SG_REL_ ZR_MIB_TOP_ab_Gen3 SG_ 1471 MFL_Tastencode_2 5000;
BA_REL_ "GenSigTimeoutTime" BU_SG_REL_ ZR_MIB_TOP_ab_Gen3 SG_ 1471 MFL_Eventcode_1 5000;
BA_REL_ "GenSigTimeoutTime" BU_SG_REL_ ZR_MIB_TOP_ab_Gen3 SG_ 1471 MFL_Eventcode_2 5000;
BA_REL_ "GenSigTimeoutTime" BU_SG_REL_ ZR_MIB_TOP_ab_Gen3 SG_ 1471 MFL_Marke 5000;
BA_REL_ "GenSigTimeoutTime" BU_SG_REL_ ZR_MIB_TOP_ab_Gen3 SG_ 1471 MFL_Variante 5000;
VAL_ 2549088371 Info_El_KompSchutz 0 "inaktiv" 1 "aktiv" ;
VAL_ 2549088371 Info_El_Abschaltstufe 0 "keine_Einschraenkung" 1 "Funktionseinschraenkung" ;
VAL_ 2549088371 Info_El_Transport_Mode 0 "keine_Einschraenkung" 1 "Funktionseinschraenkung" ;
VAL_ 2549088371 Info_El_Nachlauftyp 0 "Komm_bei_KL15_EIN" 1 "Komm_nach_KL15_AUS" 2 "Komm_bei_KL15_AUS" ;
VAL_ 2549088371 KN_Info_El_BusKnockOutTimer 255 "BusKnockOut_deaktiviert" ;
VAL_ 2549088371 NM_Info_El_Wakeup 0 "Peripherie_Wakeup__Ursache_nicht_bekannt" 1 "Bus_Wakeup" 2 "KL15_HW" 3 "Eject_Button" 4 "Remote_Lock_Unlock" 5 "Remote_Standheizung" 128 "WakeUp_Lock_Anf" 129 "Display_On_Anf" 130 "HMI_OnlineUpdate" ;
VAL_ 2549088371 KN_Info_El_DiagPfad 0 "aktiv" 1 "inaktiv" ;
VAL_ 2549088371 NM_Info_El_Lokalaktiv 0 "war_nicht_lokal_aktiv" 1 "war_lokal_aktiv" ;
VAL_ 2549088371 NM_Info_El_Subsystemaktiv 0 "Subsystem_war_nicht_lokalaktiv" 1 "war_lokalaktiv" ;
VAL_ 2549088371 Info_El_KD_Fehler 0 "Kein_KD_Fehler" 1 "KD_Fehler" ;
VAL_ 2549088420 LSH_KompSchutz 0 "inaktiv" 1 "aktiv" ;
VAL_ 2549088420 LSH_Abschaltstufe 0 "keine_Einschraenkung" 1 "Funktionseinschraenkung" ;
VAL_ 2549088420 LSH_Transport_Mode 0 "keine_Einschraenkung" 1 "Funktionseinschraenkung" ;
VAL_ 2549088420 LSH_Nachlauftyp 0 "Komm_bei_KL15_EIN" 1 "Komm_nach_KL15_AUS" 2 "Komm_bei_KL15_AUS" ;
VAL_ 2549088420 NM_LSH_Wakeup 0 "Peripherie_Wakeup__Ursache_nicht_bekannt" 1 "Bus_Wakeup" 2 "KL15_HW" 3 "LSH_EIN_AUS_Funk" 4 "Datentransfer_Funk" 5 "Geblaese_aktiv" 131 "Abschalten_Fehlerfall" ;
VAL_ 2549088420 KN_LSH_DiagPfad 0 "aktiv" 1 "inaktiv" ;
VAL_ 2549088420 LSH_KD_Fehler 0 "kein_KD_Fehler" 1 "KD_Fehler" ;
VAL_ 2549088267 RDK_KompSchutz 0 "inaktiv" 1 "aktiv" ;
VAL_ 2549088267 RDK_Abschaltstufe 0 "keine_Einschraenkung" 1 "Funktionseinschraenkung" ;
VAL_ 2549088267 RDK_Transport_Mode 0 "keine_Einschraenkung" 1 "Funktionseinschraenkung" ;
VAL_ 2549088267 RDK_Nachlauftyp 0 "Komm_bei_KL15_EIN" 1 "Komm_nach_KL15_AUS" 2 "Komm_bei_KL15_AUS" ;
VAL_ 2549088267 KN_RDK_ECUKnockOutTimer 63 "ECUKnockOut_deaktiviert" ;
VAL_ 2549088267 KN_RDK_BusKnockOut 0 "Funktion_nicht_ausgeloest" 1 "Veto_aktiv" 2 "Funktion_ausgeloest" 3 "Funktion_deaktiviert" ;
VAL_ 2549088267 KN_RDK_BusKnockOutTimer 255 "BusKnockOut_deaktiviert" ;
VAL_ 2549088267 NM_RDK_Wakeup 0 "Peripherie_Wakeup_Ursache_nicht_bekannt" 1 "Bus_Wakeup" 2 "KL15_HW" ;
VAL_ 2549088267 KN_RDK_ECUKnockOut 0 "Funktion_nicht_ausgeloest" 1 "Veto_war_aktiv" 2 "Funktion_ausgeloest" 3 "Funktion_deaktiviert" ;
VAL_ 2549088267 KN_RDK_DiagPfad 0 "aktiv" 1 "inaktiv" ;
VAL_ 2549088267 RDK_KD_Fehler 0 "Kein KD_Fehler" 1 "KD_Fehler" ;
VAL_ 2549088362 STH_KompSchutz 0 "inaktiv" 1 "aktiv" ;
VAL_ 2549088362 STH_Abschaltstufe 0 "keine_Einschraenkung" 1 "Funktionseinschraenkung" ;
VAL_ 2549088362 STH_Transport_Mode 0 "keine_Einschraenkung" 1 "Funktionseinschraenkung" ;
VAL_ 2549088362 STH_Nachlauftyp 0 "Komm_bei_KL15_EIN" 1 "Komm_nach_KL15_AUS" 2 "Komm_bei_KL15_AUS" ;
VAL_ 2549088362 KN_STH_BusKnockOutTimer 255 "BusKnockOut_deaktiviert" ;
VAL_ 2549088362 NM_STH_Wakeup 0 "Peripherie_Wakeup_Ursache_nicht_bekannt" 1 "Bus_Wakeup" 2 "KL15_HW" 3 "STH_EIN_AUS_Funk" 4 "Datentransfer_Funk" 128 "Anf_Schwalltopf_fuellen" 129 "Anf_Geblaese" 130 "Anf_WaPu_Starten" 131 "Abschalten_Fehlerfall" 132 "STH_STL_Einschalt_Ausschaltwunsc" ;
VAL_ 2549088362 KN_STH_DiagPfad 0 "aktiv" 1 "inaktiv" ;
VAL_ 2549088362 NMH_STH_Lokalaktiv 0 "war_nicht_lokal_aktiv" 1 "war_lokal_aktiv" ;
VAL_ 2549088362 NMH_STH_Subsystemaktiv 0 "Subsystem_war_nicht_lokalaktiv" 1 "war_lokalaktiv" ;
VAL_ 2549088362 STH_KD_Fehler 0 "Kein KD_Fehler" 1 "KD_Fehler" ;
VAL_ 779 KBI_ABS_Lampe 0 "ABS Lampe aus" 1 "ABS Lampe ein" ;
VAL_ 779 KBI_ESP_Lampe 0 "ESP Lampe aus" 1 "ESP Lampe ein" ;
VAL_ 779 KBI_BKL_Lampe 0 "BKL aus" 1 "BKL ein" ;
VAL_ 779 KBI_Airbag_Lampe 0 "Airbag Lampe aus" 1 "Airbag Lampe ein" ;
VAL_ 779 KBI_SILA_gueltig 0 "ungueltig" 1 "gueltig" ;
VAL_ 779 KBI_Vorglueh_System_Lampe 0 "Lampe aus" 1 "Lampe ein" ;
VAL_ 779 KBI_NV_in_Anzeige 0 "NV_nicht_in_Anzeige" 1 "NV_in_Anzeige" ;
VAL_ 779 KBI_Anzeigestatus_ACC 0 "keine_ACC_Anzeige" 1 "ACC_Anzeige_aktiv" ;
VAL_ 779 KBI_Anzeigestatus_GRA 0 "nicht_vorhanden" 1 "Anzeigemoeglichkeit_vorhanden" 2 "reserviert" 3 "Fehler" ;
VAL_ 779 KBI_Oeldruck_Schalter 0 "offen____p_kleiner_pnenn" 1 "geschlossen____p_groessergleich_pnenn" ;
VAL_ 779 KBI_Tankwarnung 0 "Lampe aus" 1 "Lampe ein" ;
VAL_ 779 KBI_MFA_v_Einheit_01 0 "kmh" 1 "mph" ;
VAL_ 779 KBI_im_Stellgliedtest 0 "kein Stellgliedtest" 1 "Kombi im Stellgliedtest" ;
VAL_ 779 KBI_Anzeigefehler_LDW 0 "nicht vorhanden bzw. unterstützt" 1 "Anzeige iO" 2 "Anzeigefehler" 3 "nicht definiert" ;
VAL_ 779 KBI_Tankwarnung_ungueltig 0 "KBI_Tankwarnung_gueltig" 1 "KBI_Tankwarnung_ungueltig" ;
VAL_ 779 KBI_Oeldruckwarnung 0 "inaktiv" 1 "aktiv" ;
VAL_ 779 KBI_Handbremse 0 "nicht_angezogen" 1 "angezogen" ;
VAL_ 779 KBI_PLA_in_Anzeige 0 "PLA_nicht_in_Anzeige" 1 "PLA_in_Anzeige" ;
VAL_ 779 KBI_Anzeigefehler_NV 0 "kein_Anzeigefehler" 1 "Anzeigefehler" ;
VAL_ 779 KBI_Anzeigestatus_LIM 0 "nicht_vorhanden" 1 "Anzeigemoeglichkeit_vorhanden" 2 "reserviert" 3 "Fehler" ;
VAL_ 779 KBI_ARA_in_Anzeige 0 "ARA nicht in Anzeige" 1 "ARA in Anzeige" ;
VAL_ 779 KBI_Taster_Lift 0 "nicht_betaetigt" 1 "betaetigt" ;
VAL_ 779 KBI_Taster_Fahrwerk 0 "nicht_betaetigt" 1 "betaetigt" ;
VAL_ 779 KBI_Audioabsenkung_MIB 0 "keine_Audio_Absenkung" 1 "Audio_Absenkung_Stufe_1" 2 "Audio_Absenkung_Stufe_2" 3 "Audio_Absenkung_Stufe_3" ;
VAL_ 779 KBI_Bestaetigung_ESP_Off 0 "ESP_off_nicht_quittiert" 1 "ESP_off_quittiert" 2 "Abbruch" ;
VAL_ 779 KBI_Anzeigestatus_RHP 0 "nicht_unterstuetzt_oder_Startup" 1 "Anzeige iO" 2 "Anzeigefehler" 3 "nicht definiert" ;
VAL_ 779 KBI_Konsistenz_ACC 0 "ACC Botschaft konsistent" 1 "ACC Botschaft inkonsistent" ;
VAL_ 779 KBI_Fehler_Anzeige_ACC 0 " iO" 1 "Anzeigefehler ACC" ;
VAL_ 779 KBI_Anzeigefehler_SWA 0 "nicht vorhanden bzw. unterstützt" 1 "Anzeige iO" 2 "Anzeigefehler" 3 "nicht definiert" ;
VAL_ 779 KBI_Systemstatus 0 "KBI_IO" 1 "KBI_System_Failure" ;
VAL_ 1719 KBI_Kilometerstand 1048574 "Init" 1048575 "Fehler" ;
VAL_ 1719 KBI_Standzeit_02 131069 "nicht_verfuegbar" 131070 "Init" 131071 "Fehler" ;
VAL_ 1719 KBI_Reserve_Warnung_Sek 0 "Keine_Warnung" 1 "Sekundaere_Reservewarnung" ;
VAL_ 1719 KBI_RDK_Kalibrier_Anf 0 "keine_Kalibrieranforderung" 1 "Kalibrieranforderung" ;
VAL_ 1719 KBI_Inhalt_Tank 126 "Init" 127 "Fehler" ;
VAL_ 1719 KBI_FStatus_Tank 0 "Tankfüllstand i.O." 1 "Tankfüllstand n.i.O" ;
VAL_ 1719 KBI_aktive_Laengsfunktion_02 0 "Init" 1 "Speedlimiter" 2 "GRA_oder_ACC" 3 "PACCh" 4 "HDC" 5 "p_GRA" 6 "p_Lim" 7 "ACC_im_GRA_Modus" 8 "Travel_Assist" 9 "RHP" ;
VAL_ 1719 KBI_FoD_PopUP_Quittiert 0 "nicht_quittiert" 1 "Meldung_quittiert" ;
VAL_ 1719 KBI_GRA_im_ACC 0 "GRA_im_ACC_nicht_ausgewaehlt" 1 "GRA_im_ACC_ausgewaehlt" ;
VAL_ 1719 KBI_Oelwechsel_durchgefuehrt 0 "Oelwechsel_nicht_durchgefuehrt" 1 "Oelwechsel_durchgefuehrt" ;
VAL_ 1719 KBI_QBit_Aussen_Temp_gef 0 "gueltiger_Wert" 1 "Ersatz_Init_oder_Fehlerwert" ;
VAL_ 1719 KBI_Aussen_Temp_gef 253 "nicht verbaut" 254 "Init" 255 "Fehler" ;
VAL_ 1720 KBI_Variante_USA 0 "keine USA-Variante" 1 "USA-Variante" ;
VAL_ 1720 KBI_Variante 0 "Zeiger Kombiinstrument" 1 "Volldisplay Kombiinstrument" ;
VAL_ 1720 KBI_GAP_Warn_Zeit_abgelaufen 0 "Zaehler_nicht_abgelaufen" 1 "Zaehler_abgelaufen" ;
VAL_ 1720 KBI_Quittierung_Naesse 0 "nicht_quittiert" 1 "quittiert" ;
VAL_ 1720 KBI_BCmE_aktiv 0 "Anzeige_nicht_aktiv" 1 "Anzeige_aktiv" ;
VAL_ 1720 KBI_Sparhinweis_quittiert 0 "nicht_quittiert" 1 "quittiert" ;
VAL_ 1720 KBI_Tankfuellstand_Prozent 126 "Init" 127 "Fehler" ;
VAL_ 1720 KBI_Nachtanken_erkannt 0 "Geberbetrieb" 1 "Nachtankmodus" ;
VAL_ 1720 KBI_Tankinhalt_hochaufl 16382 "Init" 16383 "Fehler" ;
VAL_ 1720 KBI_Max_Tankinhalt 254 "Init" 255 "Fehler" ;
VAL_ 1720 KBI_Quittierung_cAQP 0 "nicht_quittiert" 1 "quittiert" ;
VAL_ 2527679639 KBI_Weg_Zaehler_F 0 "kein Fehler" 1 "Fehler" ;
VAL_ 2527679639 KBI_Anzeige_ID_quittiert 0 "Init" ;
VAL_ 2527679639 KBI_Min_Tankinhalt 126 "Init" 127 "Fehler" ;
VAL_ 2527679639 KBI_Jokerkey 0 "nicht_betaetigt" 1 "betaetigt" ;
VAL_ 2527679639 KBI_RS_Druck_uebernehmen 0 " Druck für Rundstreckenmodue nicht uebernehmen" 1 " Druck für Rundstreckenmodus uebernehmen" ;
VAL_ 2527679639 KBI_RS_Druckauswahl_Aktiv 0 "inaktiv" 1 "aktiv" ;
VAL_ 2527679639 KBI_RS_Mode_fortsetzen 0 "Rundstreckenmodus_nicht_fortsetzen" 1 "Rundstreckenmodus_fortsetzen" ;
VAL_ 2527679639 KBI_Rundstreckenmodus 0 "nicht_angefordert" 1 "angefordert" ;
VAL_ 2527679639 AuthTime_Trigger_Distribution 0 "inaktiv" 1 "aktiv" ;
VAL_ 2527679639 KBI_FoD_VirtualCockpitPlus_State 0 "Init" 1 "locked" 2 "unlocked" ;
VAL_ 2527679656 KBI_StartupAnimation 0 "Init" 1 "StartMeasureDelay" 2 "RequestStartAnimation" 3 "RequestCancelAnimation" 4 "CIAnimationStarted" 5 "CIAnimationStopped" ;
VAL_ 2589283935 KBI_View1 0 "false" 1 "true" ;
VAL_ 2589283935 KBI_View2 0 "false" 1 "true" ;
VAL_ 2589283935 KBI_View3 0 "false" 1 "true" ;
VAL_ 2589283935 KBI_View4 0 "false" 1 "true" ;
VAL_ 2589283935 KBI_View5 0 "false" 1 "true" ;
VAL_ 2589283935 KBI_View6 0 "false" 1 "true" ;
VAL_ 2589283935 KBI_View7 0 "false" 1 "true" ;
VAL_ 2589283935 KBI_View8 0 "false" 1 "true" ;
VAL_ 2589283935 KBI_View9 0 "false" 1 "true" ;
VAL_ 2589283935 KBI_View10 0 "false" 1 "true" ;
VAL_ 2589283935 KBI_View11 0 "false" 1 "true" ;
VAL_ 2589283935 KBI_View12 0 "false" 1 "true" ;
VAL_ 2589283935 KBI_View13 0 "false" 1 "true" ;
VAL_ 2589283935 KBI_View14 0 "false" 1 "true" ;
VAL_ 2589283935 KBI_View15 0 "false" 1 "true" ;
VAL_ 2589283935 KBI_View16 0 "false" 1 "true" ;
VAL_ 2589283935 KBI_View17 0 "false" 1 "true" ;
VAL_ 2589283935 KBI_View18 0 "false" 1 "true" ;
VAL_ 2589283935 KBI_View19 0 "false" 1 "true" ;
VAL_ 2589283935 KBI_View20 0 "false" 1 "true" ;
VAL_ 2589283935 KBI_View21 0 "false" 1 "true" ;
VAL_ 2589283935 KBI_View22 0 "false" 1 "true" ;
VAL_ 2589283935 KBI_View23 0 "false" 1 "true" ;
VAL_ 2589283935 KBI_View24 0 "false" 1 "true" ;
VAL_ 2589283935 KBI_Curr_View 0 "init" 1 "View1" 2 "View2" 3 "View3" 4 "View4" 5 "View5" 6 "View6" 7 "View7" 8 "View8" 9 "View9" 10 "View10" 11 "View11" 12 "View12" 13 "View13" 14 "View14" 15 "View15" 16 "View16" 17 "View17" 18 "View18" 19 "View19" 20 "View20" 21 "View21" 22 "View22" 23 "View23" 24 "View24" 25 "reserved" 26 "reserved" 27 "reserved" 28 "reserved" 29 "reserved" 30 "reserved" 31 "reserved" ;
VAL_ 2589283935 KBI_Sec_View_Status 0 "init" 1 "Deaktiviert" 2 "Aktiviert" ;
VAL_ 110 EPS_QBit_Zahnstangen_Grad 0 "gueltiger_Wert" 1 "Ersatz_Init_oder_Fehlerwert" ;
VAL_ 110 EPS_Sensorikstatus 0 "iO" 1 "nicht_kalibriert" ;
VAL_ 110 EPS_QBit_Zahnstangen_Pos 0 "gueltiger_Wert" 1 "Ersatz_Init_oder_Fehlerwert" ;
VAL_ 110 EPS_Zahnstangen_Pos_02 32766 "Init" 32767 "Fehler" ;
VAL_ 110 EPS_VZ_Zahnstangenposition 0 "pos_VZ" 1 "neg_VZ" ;
VAL_ 110 EPS_Zahnstangen_Grad 32767 "Fehler" ;
VAL_ 110 EPS_VZ_Zahnstangen_Grad 0 "pos_in_Richt_links_Nullstellung" 1 "neg_in_Richt_rechts_Nullstellung" ;
VAL_ 981 BCM1_Kurvenlicht_links_Anf 0 "linkes_Kurvenlicht/Abbiegelicht_durch_BCM1_nicht_angesteuert" 1 "linkes_Kurven/Abbiegelicht_durch_BCM1_angesteuert" ;
VAL_ 981 BCM1_Kurvenlicht_rechts_Anf 0 "rechtes_Kurvenlicht/Abbiegelicht_durch_BCM1_nicht_angesteuert" 1 "rechtes_Kurvenlicht/Abbiegelicht_durch_BCM1_angesteuert" ;
VAL_ 981 BCM1_Standlicht_Anf 0 "Licht_nicht_angefordert" 1 "Licht ist einzuschalten" ;
VAL_ 981 BCM1_Abblendlicht_Anf 0 "Licht_nicht_angefordert" 1 "Licht ist einzuschalten" ;
VAL_ 981 BCM1_Fernlicht_Anf 0 "Licht_nicht_angefordert" 1 "Licht ist einzuschalten" ;
VAL_ 981 BCM1_Nebellicht_Anf 0 "Licht_nicht_angefordert" 1 "Licht ist einzuschalten" ;
VAL_ 981 BCM1_Parklicht_li_Anf 0 "Licht_nicht_angefordert" 1 "Licht ist einzuschalten" ;
VAL_ 981 BCM1_Parklicht_re_Anf 0 "Licht_nicht_angefordert" 1 "Licht ist einzuschalten" ;
VAL_ 981 BCM1_Nebelschluss_Ahg_Anf 0 "Licht_nicht_angefordert" 1 "Licht ist einzuschalten" ;
VAL_ 981 BCM1_Nebelschluss_Fzg_Anf 0 "Licht_nicht_angefordert" 1 "Licht_ist_einzuschalten" ;
VAL_ 981 BCM1_Schlusslicht_Anf 0 "Licht_nicht_angefordert" 1 "Licht ist einzuschalten" ;
VAL_ 981 BCM_Rueckfahrlicht_Anf 0 "Licht_nicht_angefordert" 1 "Licht_angefordert" ;
VAL_ 981 BCM1_Signaturlicht_Anf 0 "Licht_nicht_angefordert" 1 "Licht_ist_einzuschalten" ;
VAL_ 981 BCM1_Umfeldleuchten_Anf 0 "Licht_nicht_angefordert" 1 "Licht_ist_einzuschalten" ;
VAL_ 981 BCM1_Tagfahrlicht_Anf 0 "Licht_nicht_angefordert" 1 "Licht ist einzuschalten" ;
VAL_ 981 BCM1_Regenlicht_Anf 0 "Licht_nicht_angefordert" 1 "Licht ist einzuschalten" ;
VAL_ 981 BCM1_Autobahnlicht_Anf 0 "Licht_nicht_angefordert" 1 "Licht ist einzuschalten" ;
VAL_ 981 BCM1_Touristen_Licht_Anf 0 "Licht_nicht_angefordert" 1 "Anforderung von Touristenlicht" ;
VAL_ 981 BCM1_CH_aktiv 0 "Inaktiv" 1 "Aktiv" ;
VAL_ 981 BCM1_LH_aktiv 0 "Inaktiv" 1 "Aktiv" ;
VAL_ 981 BCM1_Gleitende_Leuchtw_Anf 0 "Aus" 1 "Ein" ;
VAL_ 981 BCM1_GLW_Fernlicht_Anf 0 "Aus" 1 "Ein" ;
VAL_ 981 BCM1_Adaptive_Lichtvert_Anf 0 "Aus" 1 "Ein" ;
VAL_ 981 BCM1_Animationssperrung 0 "keine_Sperrung" 1 "Sperrung" ;
VAL_ 981 BCM1_CH_LH_aktiv 0 "Comming_Home_Bzw._Leaving_Home_nicht_aktiv" 1 "Comming Home bzw. Leaving Home aktiv" ;
VAL_ 981 BCM1_Allwetterlicht_Anf 0 "Licht_nicht_angefordert" 1 "Licht_ist_einzuschalten" ;
VAL_ 981 TFL_Matrix_Variante01_Anf 0 "nicht_angefordert" 1 "angefordert" ;
VAL_ 981 TFL_Matrix_Variante02_Anf 0 "nicht_angefordert" 1 "angefordert" ;
VAL_ 981 TFL_Matrix_Variante03_Anf 0 "nicht_angefordert" 1 "angefordert" ;
VAL_ 981 TFL_Matrix_Variante04_Anf 0 "nicht_angefordert" 1 "angefordert" ;
VAL_ 982 BCM2_Bremsl_durch_ECD_invers 0 "Bremslicht_durch_ECD_aktiv" 1 "Bremslicht_ist_aus" ;
VAL_ 982 BCM2_Bremsl_durch_ECD 0 "Bremslicht_ist_aus" 1 "Bremslicht_durch_ECD_aktiv" ;
VAL_ 982 LH_Aussenlicht_def 0 "OK" 1 "defekt" ;
VAL_ 982 LH_Standlicht_H_aktiv 1 "Standlicht hinten aktiv" ;
VAL_ 982 LH_Parklicht_HL_aktiv 0 "nicht aktiv" 1 "Parklicht hinten links aktiv" ;
VAL_ 982 LH_Parklicht_HR_aktiv 0 "nicht aktiv" 1 "Parklicht hinten rechts aktiv" ;
VAL_ 982 LH_Bremslicht_H_aktiv 1 "Bremslicht hinten aktiv" ;
VAL_ 982 LH_Nebelschluss_aktiv 0 "nicht aktiv" 1 "aktiv" ;
VAL_ 982 LH_Rueckfahrlicht_aktiv 0 "nicht_aktiv" 1 "aktiv" ;
VAL_ 982 LH_Blinker_HL_akt 1 "Blinker hinten links aktiv" ;
VAL_ 982 LH_Blinker_HR_akt 1 "Blinker hinten rechts aktiv" ;
VAL_ 982 LH_Blinker_li_def 0 "OK" 1 "Blinker hinten links defekt" ;
VAL_ 982 LH_Bremsl_li_def 0 "OK" 1 "mindestens ein Bremslicht hinten links defekt" ;
VAL_ 982 LH_Schlusslicht_li_def 0 "OK" 1 "mindestens ein Schlusslicht hinten links defekt" ;
VAL_ 982 LH_Rueckf_li_def 0 "OK" 1 "Rückfahrlicht hinten links defekt" ;
VAL_ 982 LH_Nebel_li_def 0 "OK" 1 "Nebelschlusslicht_hinten_links_defekt" ;
VAL_ 982 LH_Schluss_Brems_Nebel_li_def 0 "iO" 1 "defekt" ;
VAL_ 982 LH_Schluss_Brems_Nebel_re_def 0 "iO" 1 "defekt" ;
VAL_ 982 LH_Zusatzschlussl_def 0 "OK" 1 "mindestens_ein_Zusatzschlusslicht_defekt" ;
VAL_ 982 LH_Schluss_Brems_li_def 0 "OK" 1 "defekt" ;
VAL_ 982 LH_Schluss_Nebel_li_def 0 "OK" 1 "defekt" ;
VAL_ 982 LH_SL_BRL_BLK_li_def 0 "OK" 1 "defekt" ;
VAL_ 982 LH_Brems_Blk_li_def 0 "OK" 1 "defekt" ;
VAL_ 982 LH_Diag_Status_re_def 0 "OK" 1 "Aussenlict_Diagnose_Systemstoerung_rechts" ;
VAL_ 982 LH_Diag_Status_li_def 0 "OK" 1 "Aussenlicht_Diagnose_Systemstoerung_links" ;
VAL_ 982 LH_Diag_LED_li_def 0 "OK" 1 "Heckleuchte_links_defekt" ;
VAL_ 982 LH_Diag_LED_re_def 0 "OK" 1 "Heckleuchte_rechts_defekt" ;
VAL_ 982 LH_Blinker_re_def 0 "OK" 1 "Blinker hinten rechts defekt" ;
VAL_ 982 LH_Bremsl_re_def 0 "OK" 1 "mindestens ein Bremslicht hinten rechts defekt" ;
VAL_ 982 LH_Schlusslicht_re_def 0 "OK" 1 "mindestens_ein_Schlusslicht_hinten_rechts_defekt" ;
VAL_ 982 LH_Rueckf_re_def 0 "OK" 1 "Rückfahrlicht hinten rechts defekt" ;
VAL_ 982 LH_Nebel_re_def 0 "OK" 1 "Nebelschlusslicht hinten rechts defekt" ;
VAL_ 982 LH_Schluss_Brems_re_def 0 "OK" 1 "defekt" ;
VAL_ 982 LH_Schluss_Nebel_re_def 0 "OK" 1 "defekt" ;
VAL_ 982 LH_SL_BRL_BLK_re_def 0 "OK" 1 "defekt" ;
VAL_ 982 LH_Brems_Blk_re_def 0 "OK" 1 "defekt" ;
VAL_ 982 LH_Kennzl_def 0 "OK" 1 "Kennzeichenbeleuchtung hinten defekt" ;
VAL_ 982 LH_3_Bremsl_def 0 "OK" 1 "hochgesetzte  Bremsleuchte defekt" ;
VAL_ 982 LH_Nebel_mi_def 0 "OK" 1 " Nebelschlusslicht hinten Mitte defekt" ;
VAL_ 982 LH_Rueckf_mi_def 0 "OK" 1 "Rückfahllicht Mitte defekt" ;
VAL_ 982 LH_Bremsl_li_ges_def 0 "OK" 1 "Alle Bremslichter hinten links defekt" ;
VAL_ 982 LH_Bremsl_re_ges_def 0 "OK" 1 "Alle Bremslichter hinten rechts defekt" ;
VAL_ 1624 LV_Standlicht_Anzeige 0 "nicht aktiv" 1 "aktiv" ;
VAL_ 1624 LV_Abblendlicht_Anzeige 0 "inaktiv" 1 "aktiv" ;
VAL_ 1624 LV_Fernlicht_Anzeige 0 "nicht aktiv" 1 "aktiv" ;
VAL_ 1624 LV_Nebellicht_Anzeige 0 "nicht aktiv" 1 "aktiv" ;
VAL_ 1624 LV_Nebelschlusslicht_Anzeige 0 "nicht aktiv" 1 "aktiv" ;
VAL_ 1624 LV_Tagfahrlicht_Anzeige 0 "nicht aktiv" 1 "aktiv" ;
VAL_ 1624 LV_AFL_aktiv_Anzeige 0 "nicht aktiv" 1 "aktiv" ;
VAL_ 1624 LV_AFL_defekt 0 "OK" 1 "defekt" ;
VAL_ 1624 LV_Blinker_li_def 0 "OK" 1 "defekt" ;
VAL_ 1624 LV_Standlicht_li_def 0 "OK" 1 "defekt" ;
VAL_ 1624 LV_Abblendlicht_li_def 0 "OK" 1 "defekt" ;
VAL_ 1624 LV_Fernlicht_li_def 0 "OK" 1 "defekt" ;
VAL_ 1624 LV_Nebellicht_li_def 0 "OK" 1 "defekt" ;
VAL_ 1624 LV_Blk_li_Seite_def 0 "OK" 1 "defekt" ;
VAL_ 1624 LV_Tagfahrlicht_li_def 0 "OK" 1 "defekt" ;
VAL_ 1624 LV_FLA_aktiv_Anzeige 0 "aus" 1 "ein" ;
VAL_ 1624 LV_FLA_defekt 0 "i.O." 1 "FLA defekt" ;
VAL_ 1624 LV_FLA_Sensor_blockiert 0 "i.O." 1 "FLA-Sensor blockiert" ;
VAL_ 1624 LV_Blinker_re_def 0 "OK" 1 "defekt" ;
VAL_ 1624 LV_Standlicht_re_def 0 "OK" 1 "defekt" ;
VAL_ 1624 LV_Abblendlicht_re_def 0 "OK" 1 "defekt" ;
VAL_ 1624 LV_Fernlicht_re_def 0 "OK" 1 "defekt" ;
VAL_ 1624 LV_Nebellicht_re_def 0 "OK" 1 "defekt" ;
VAL_ 1624 LV_Blk_re_Seite_def 0 "OK" 1 "defekt" ;
VAL_ 1624 LV_Tagfahrlicht_re_def 0 "OK" 1 "defekt" ;
VAL_ 1624 LV_Aussenlicht_def 0 "OK" 1 "defekt" ;
VAL_ 1624 LV_Abblendlicht_TFL_li_def 0 "OK" 1 "defekt" ;
VAL_ 1624 LV_Nebellicht_TFL_li_def 0 "OK" 1 "defekt" ;
VAL_ 1624 LV_Standlicht_TFL_li_def 0 "OK" 1 "defekt" ;
VAL_ 1624 LV_Abblend_Fernlicht_li_def 0 "OK" 1 "defekt" ;
VAL_ 1624 LV_Abblendlicht_TFL_re_def 0 "OK" 1 "defekt" ;
VAL_ 1624 LV_Nebellicht_TFL_re_def 0 "OK" 1 "defekt" ;
VAL_ 1624 LV_Standlicht_TFL_re_def 0 "OK" 1 "defekt" ;
VAL_ 1624 LV_Abblend_Fernlicht_re_def 0 "OK" 1 "defekt" ;
VAL_ 1624 LV_Abbiegelicht_li_def 0 "OK" 1 "defekt" ;
VAL_ 1624 LV_Abbiegelicht_re_def 0 "OK" 1 "defekt" ;
VAL_ 1624 BCM1_Linksverkehr 0 "Rechtsverkehr" 1 "Linksverkehr" ;
VAL_ 1624 BCM1_Licht_Dunkelheit_aktiv 0 "inaktiv" 1 "aktiv" ;
VAL_ 1624 LV_LED_Scheinwerfer_li_def 0 "OK" 1 "defekt" ;
VAL_ 1624 LV_LED_Scheinwerfer_re_def 0 "OK" 1 "defekt" ;
VAL_ 1624 LV_Blinker_VL_aktiv 0 "inaktiv" 1 "aktiv" ;
VAL_ 1624 LV_Blinker_VR_aktiv 0 "inaktiv" 1 "aktiv" ;
VAL_ 1624 LV_MXB_Status_Anzeige 0 "MXB_aus" 1 "MXB_regelt" 2 "MXB_volles_Fernlicht" 3 "MXB_und_Laser_aktiv" ;
VAL_ 2463978598 LoGeWa_C2C_Anf_Audioabsenkung 0 "nicht_aktiv" 1 "aktiv" ;
VAL_ 2463978598 LoGeWa_C2C_Event_Einheit 0 "Init" 1 "Meter" 2 "Kilometer" 3 "Yard" 4 "Meilen" ;
VAL_ 2463978598 LoGeWa_C2C_Event_Richtung 0 "Init_keine_Richtungsanzeige" 1 "voraus" 2 "von_rechts_naehernd" 3 "von_links_naehernd" 4 "von_hinten_naehernd" 5 "mehrere_Richtungen" ;
VAL_ 2463978598 LoGeWa_C2C_Event_Status 0 "Init_keine_Anzeige" 1 "Info_ohne_Infogong" 2 "Info_mit_Infogong" 3 "Warnung_ohne_Warngong" 4 "Warnung_mit_Warngong" ;
VAL_ 2463978598 LoGeWa_C2C_Event_Warnung 0 "Init" 1 "Unfall" 2 "Traktionsverlust" 3 "Panne" 4 "Sichtbehinderung" 5 "Stauende" 6 "Stau" 7 "Eingriff_Sicherheitssystem" 8 "statisches_SEF" 9 "dynamisches_SEF" 10 "mehrere_dynamische_SEF" 11 "Sperranhaenger" 12 "generisches_statisches_Event" 13 "Stehenbleiber" 14 "Car2X_system_eingeschraenkt" 15 "Car2X_eingeschraenkt_geofencing" 16 "dynamische_SEF_ohneAbsenkung" 17 "mehrere_dyn_SEF_ohneAbsenkung" 18 "Strong_Wind" 19 "Obstacle_on_Road" 20 "Person_on_Road" 21 "Animal_on_Road" 22 "Public_Tranport_Vehicle_Crossing" 23 "Slow_Vehicle" 24 "Wrong_Way_Driving" 25 "Generic_Adverse_Weather" 26 "Water_Accumulation" 27 "Fire" 28 "Facility_Damaged" 29 "Traffic_Light_Failure" 30 "Traffic_Accident" ;
VAL_ 2463978598 LoGeWa_C2C_Event_Entfernung 65535 "Init_keine_Entfernung" ;
VAL_ 2527679633 LSH_Geblaese_aktiv 0 "Geblaese_inaktiv" 1 "Geblaese_aktiv" ;
VAL_ 2527679633 LSH_LED 0 "keine_Rueckmeldung" 1 "Rueckmeldung_in_Betrieb" ;
VAL_ 2527679633 LSH_Servicemode 0 "inaktiv" 1 "aktiv" ;
VAL_ 2527679633 LSH_Funk_aus 0 "kein_Funkbefehl_erhalten" 1 "Funkbefehl_erhalten" ;
VAL_ 2527679633 LSH_Funk_ein 0 "kein_Funkbefehl_erhalten" 1 "Funkbefehl_erhalten" ;
VAL_ 2527679633 LSH_Klappe_Status 0 "Init" 1 "Front" 2 "Heck" 3 "Front_u_Heck" 4 "misch_Front_u_Heck" ;
VAL_ 2527679633 LSH_Start_folgt 0 "kein_Start_folgt" 1 "Start_folgt" ;
VAL_ 2527679633 LSH_Heiztemp 254 "Init" 255 "Fehler" ;
VAL_ 2527679633 LSH_Empf_Heizstufe 0 "Init" 1 "Stufe_1" 2 "Stufe_2" 3 "Stufe_3" 4 "Stufe_4" 5 "Stufe_5" 6 "Stufe_6" 7 "Stufe_7" 8 "Stufe_8" 9 "Stufe_9" 10 "Stufe_10" 15 "Fehler" ;
VAL_ 2527679633 LSH_Texte 0 "keine_Anzeige" 1 "Batteriemanagementeinschraenkung" 2 "Kraftstoffmangel" 3 "interner_Systemfehler" 4 "Heizzeitueberschreitung" ;
VAL_ 2527679633 LSH_Waermeeintrag 510 "Init" 511 "Fehler" ;
VAL_ 2527679633 LSH_Ansaug_Fuell_1 254 "Init" 255 "Fehler" ;
VAL_ 2527679633 LSH_Ansaug_Fuell_2 254 "Init" 255 "Fehler" ;
VAL_ 2527679634 LSH_Zuheizen 0 "Aus" 1 "Ein" ;
VAL_ 2527679634 LSH_KVS_Ueberlauf 0 "kein_Ueberlauf" 1 "Kraftstoff_Ueberlauf_erkannt" ;
VAL_ 2527679634 LSH_KL_DBetr_Anf 0 "nicht_angefordert" 1 "angefordert" ;
VAL_ 2527679634 LSH_Fehlerstatus 0 "kein_Fehler" 1 "Unterspannung" 2 "Tankfuellstand_zu_gering" 3 "Fehler_Betrieb_verhindert" 4 "Heizgeraet_verriegelt" 5 "Fehler_Betrieb_nicht_verhindert" 6 "Emissionsueberschreitung" ;
VAL_ 134 LWI_Sensorstatus 0 "iO" 1 "nicht kalibriert" ;
VAL_ 134 LWI_QBit_Sub_Daten 0 "LWS-Subinfo real (Lenkradwinkelinformation ADS-tauglich) " 1 "LWS-Subinfo simuliert (Lenkradwinkelinformation nicht ADS-tauglich )" ;
VAL_ 134 LWI_QBit_Lenkradwinkel 0 "gültiger Wert" 1 "ausserhalb der Spezifikation" ;
VAL_ 134 LWI_Lenkradwinkel 8190 "Init" 8191 "Fehler" ;
VAL_ 134 LWI_VZ_Lenkradwinkel 0 "positiv_links_von_der_Nullstellung" 1 "negativ" ;
VAL_ 134 LWI_VZ_Lenkradw_Geschw 0 "positiv_links_von_der_Nullstellung" 1 "negativ" ;
VAL_ 134 LWI_Lenkradw_Geschw 510 "Init" 511 "Fehler" ;
VAL_ 1153 ZR_LoGeWa_Event_Kombiwarnung 0 "Init" 1 "Unfall" 2 "Traktionsverlust" 3 "Panne" 4 "Sichtbehinderung" 5 "Aquaplaning" 6 "EEBL" 7 "SEF_stat" 8 "SEF_dyn_allgemein" 9 "SEF_dyn_vorne" 10 "SEF_dyn_hinten" 11 "SEF_dyn_links" 12 "SEF_dyn_rechts" 13 "Stauende" ;
VAL_ 1153 Nav_FoD_Status 0 "Init" 1 "Nav_permanently_available" 2 "FoD_Nav_not_activated" 3 "FoD_Nav_activated" 4 "R4N_Nav_not_activated" ;
VAL_ 1153 MIB_ASW_Diagnose 0 "ASW_Warnton_nicht_verfuegbar" 1 "ASW_Warnton_verfuegbar" ;
VAL_ 1153 ZR_Lichter_Tag 0 "Nacht" 1 "Tag" ;
VAL_ 1153 MIB_Tongenerator_PH_verfuegbar 0 "Tongenerator_nicht_verfuegbar" 1 "Tongenerator_vorne_verfuegbar" 2 "Tongenerator_hinten_verfuegbar" 3 "Tongenerator_gesamt_verfuegbar" 4 "Tongenerator_im_AMP" ;
VAL_ 1153 DSSS_Warning 0 "No_Warning" 1 "Red_traffic_light_guidance" 2 "Stop_sign_warning" 3 "Rear_end_collision_avoidance_warning" 4 "Intersection_collision_avoidance_warning_right" 5 "Intersection_collision_avoidance_warning_left" 6 "turn_right_collision_avoidance" 7 "turn_left_collision_avoidance" 8 "pedestrian_crossing_right" 9 "pedestrian_crossing_left" 10 "bicycle_collision_right" 11 "bicycle_collision_left" ;
VAL_ 1153 ZR_Kindersicherung_RSE 0 "inaktiv" 1 "aktiv" ;
VAL_ 1153 ZR_RSE_aktivieren 0 "inaktiv" 1 "aktiv" ;
VAL_ 1153 MMI_SDS_aktiv 0 "inaktiv" 1 "aktiv" ;
VAL_ 1153 MU_SecondDisplay 0 "Init" 1 "gueltige_Karte" 2 "ungueltiges_Signal" 3 "Nicht_Verbaut" ;
VAL_ 1153 MMI_Telefon_aktiv 0 "Telefongespraech_nicht_aktiv" 1 "Telefongespraech_aktiv" ;
VAL_ 1153 MMI_Gurt_Mic_ref 0 "Downlink_inaktiv" 1 "Downlink_aktiv" ;
VAL_ 1153 ZR_Sta_Inszenierung 0 "Init" 1 "Inszenierung_deaktiviert" 2 "Inszenierung_Start" 3 "Inszenierung_Stop" ;
VAL_ 1153 ZR_AppConnect_Zustand 0 "AppConnect_nicht_in_Anzeige" 1 "AppConnect_in_Anzeige" ;
VAL_ 1153 ZR_Parken_Sondermodus 0 "Init" 1 "Sondermodus_aktiv" 2 "Sondermodus_nicht_verfuegbar" 3 "WLAN_aus" 4 "WLAN_auscodiert" 15 "keine_WLAN_HW" ;
VAL_ 1178 FS_Fond_Bed_enable 0 "disable" 1 "enable" ;
VAL_ 1178 FS_Lehne_nicht_verriegelt 0 "keine Anzeige" 1 "Lehne_nicht_verriegelt" ;
VAL_ 1178 FS_Spezialposition_anfahren 0 "Fkt_inaktiv" 1 "Fkt_aktiv" ;
VAL_ 1178 FS_Gurtbringer_Sperre 0 "Gurtzubringer_freigegeben" 1 "Gurtzubringer_gesperrt" ;
VAL_ 1178 FS_BFS_Sitzsym_Anfahrt 0 "keine Sitzsymetrie Anfahrt BFS" 1 "Sitzsymetrie Anfahrt BFS" ;
VAL_ 1178 FS_Sitzfahrt_aktiv 0 "Sitz_nicht_in_Bewegung" 1 "Sitz_in_Bewegung" ;
VAL_ 1178 FS_SLV_aktiv 0 "nicht_aktiv" 1 "Sitzlaengsverstellung aktiv" ;
VAL_ 1178 FS_SHV_aktiv 0 "nicht_aktiv" 1 "Sitzhoehenverstellung aktiv" ;
VAL_ 1178 FS_LNV_aktiv 0 "nicht_aktiv" 1 "Lehnenneigungverstellung aktiv" ;
VAL_ 1178 FS_SNV_aktiv 0 "nicht_aktiv" 1 "Sitzneigungsverstellung_aktiv" ;
VAL_ 1178 FS_KSV_aktiv 0 "nicht_aktiv" 1 "Kopfstuetzenverstellung aktiv" ;
VAL_ 1178 FS_LKV_aktiv 0 "nicht_aktiv" 1 "Lehnenkopfverstellung aktiv" ;
VAL_ 1178 FS_STV_aktiv 0 "nicht_aktiv" 1 "Sitztiefeverstellung aktiv" ;
VAL_ 1178 FS_LHV_aktiv 0 "nicht_aktiv" 1 "Lordose Höhe Verstellung aktiv" ;
VAL_ 1178 FS_LWV_aktiv 0 "nicht_aktiv" 1 "Lordose W Verstellung aktiv" ;
VAL_ 1178 FS_GHV_aktiv 0 "nicht_aktiv" 1 "Gurthoehenverstellung aktiv" ;
VAL_ 1178 FS_BFS_KSS_Anfahrt 0 "keine Anfahrt KSS BFS" 1 "Anfahrt KSS BFS" ;
VAL_ 1178 FS_MMB_lokal_Stop 0 "kein_Abbruch" 1 "lokaler_Abbruch" ;
VAL_ 1178 FS_MMB_storage 0 "keine_Zuweisung" 1 "P1_FP1_Pos_Zuweisung" 2 "P2_FP2_Pos_Zuweisung" 3 "P3_FP3_Pos_Zuweisung" 4 "P4_FP4_Pos_Zuweisung" 5 "FS1_bzw_Benutzerkonto_1" 6 "FS2_bzw_Benutzerkonto_2" 7 "FS3_bzw_Benutzerkonto_3" 8 "FS4_bzw_Benutzerkonto_4" 9 "FS5_bzw_Benutzerkonto_5" 10 "FS6_bzw_Benutzerkonto_6" 11 "FS7_bzw_Benutzerkonto_7" ;
VAL_ 1178 FS_MMB_tipp 0 "kein_Tippbetrieb" 1 "Tippbetrieb__automatisches_Funks" ;
VAL_ 1178 FS_MMB_tast 0 "kein_Tastbetrieb" 1 "Tastbetrieb__Fingerprintautomati" ;
VAL_ 1178 FS_MMB_store_LED_on 0 "LED_aus" 1 "LED_ein" ;
VAL_ 1178 FS_MMB_storage_beep 0 "beep aus" 1 "beep ein" ;
VAL_ 1178 FS_MMB_store 0 "nicht_speichern__kein_keyless_ve" 1 "abspeichern__keyless_verbaut" ;
VAL_ 1178 FS_MMB_glob_stop 0 "kein_globaler_Abbrucht" 1 "globaler_Abbruch" ;
VAL_ 1178 FS_EE_Fond_FS_enable 0 "EE Fond links deaktiv" 1 "EE Fond links aktiv (default) vom MMI" ;
VAL_ 1178 FS_EE_Fond_BFS_enable 0 "EE Fond rechts deaktiv" 1 "EE Fond rechts aktiv (default) vom MMI" ;
VAL_ 1178 FS_EE_BFS_enable 0 "keine_EE_Freigabe" 1 "EE_Freigabe" ;
VAL_ 1165 MF_VBEG_Anforderung 0 "nicht_angefordert" 1 "angefordert" ;
VAL_ 1165 MF_MFSS_aktiv 0 "inaktiv" 1 "aktiv" ;
VAL_ 1165 MF_MFSS_kodiert 0 "auskodiert" 1 "kodiert" ;
VAL_ 1165 MFG_Status_SREG 0 "Sperrung_SREG" 1 "Keine_SREG_Sperrung" ;
VAL_ 1165 MFG_Taster_SREG 0 "Taster_SREG_inaktiv" 1 "Taster_SREG_aktiviert" 2 "Init" 3 "Fehler" ;
VAL_ 1165 MFG_Taster_VREG 0 "Taster_VREG_inaktiv" 1 "Taster_VREG_aktiviert" 2 "Init" 3 "Fehler" ;
VAL_ 1165 MFG_Heizstufe_LSH 0 "Init" 1 "Stufe_1" 2 "Stufe_2" 3 "Stufe_3" 4 "Stufe_4" 5 "Stufe_5" 6 "Stufe_6" 7 "Stufe_7" 8 "Stufe_8" 9 "Stufe_9" 10 "Stufe_10" 15 "Fehler" ;
VAL_ 1165 MFG_Zuheizer_Freigabe 0 "keine_Freigabe_Zuheizer" 1 "Zuheizerfreigabe" ;
VAL_ 1165 MF_VBEG_Geschwindigkeit 255 "Init" ;
VAL_ 1165 MF_ADR_Fahrpedalsperre 0 "inaktiv" 1 "aktiv" ;
VAL_ 1165 MF_ADR_Anforderung 0 "nicht_angefordert" 1 "angefordert" ;
VAL_ 1164 MFG_Infotainment_Autark 0 "Autarkie_no" 1 "Autarkie_yes" ;
VAL_ 1164 MFG_Klappe_Status 0 "Init" 1 "Front" 2 "Heck" 3 "Front_u_Heck" 4 "misch_Front_u_Heck" ;
VAL_ 1164 MFG_LSH_DBetr_Ein 0 "Dauerbetrieb_nicht_gefordert" 1 "Dauerbetrieb_gefordert" ;
VAL_ 1164 MFG_LSH_Betriebsdauer 127 "Dauerbetrieb" ;
VAL_ 1164 MFG_LSH_DBetr_Bestaet 0 "kein_Dauerbetrieb" 1 "Dauerbetrieb_bestaetigt" ;
VAL_ 1164 MFG_LSH_Ansteuerung 0 "Aus" 1 "Ein" 2 "Kombi_Betrieb" 3 "Heizleistung_reduziert" ;
VAL_ 1164 MF_Radiomute 0 "Kein_Mute" 1 "Mute" ;
VAL_ 1164 MF_Relais_2_Batterie 0 "nicht_betaetigt" 1 "betaetigt" ;
VAL_ 1164 MF_Batteriediagnose 0 "keine_Anzeige" 1 "Anzeige_Batterieservice" 2 "Anzeige_aberkannte_Batterie" 3 "Anzeige_schwache_Batterie" 4 "Anzeige_Batterie_OK" 5 "Anzeige_Batterie_Laden" 6 "Anzeige_Batterie_Pruefen" 7 "Fehler" ;
VAL_ 1164 MFG_AppConnect_Anf 0 "AppConnect_keine_Anforderung" 1 "AppConnect_Anforderung" 2 "AppConnect_Darstellungsrueckgabe" ;
VAL_ 1164 MF_Lampenausfall 0 "iO" 1 "defekt" ;
VAL_ 1164 MF_Blinker_L_Sta 0 "inaktiv" 1 "aktiv" ;
VAL_ 1164 MF_Blinker_R_Sta 0 "inaktiv" 1 "aktiv" ;
VAL_ 1164 MF_interm_Nebelscheinwerfer 0 "inaktiv" 1 "aktiv" ;
VAL_ 1164 MF_Generatordiagnose 0 "keine_Warnung" 1 "Warnung_Stufe_1" 2 "Warnung_Stufe_2" 3 "Nicht_verbaut" ;
VAL_ 1164 MF_Heck_entriegeln 0 "nicht_entriegeln" 1 "entriegeln" ;
VAL_ 1164 MF_Heck_verriegeln 0 "nicht_verriegeln" 1 "verriegeln" ;
VAL_ 1164 MF_2BatSOCzugering 0 "inaktiv" 1 "aktiv" ;
VAL_ 1164 MF_Fahrerhinweis 0 "keine_Anzeige" 1 "Warnung_Verrollsicherheit" 2 "Warnung_Fahrzeug_im_Freien" 3 "Warnung_Verlassen_Verriegeln" 4 "reserved" 5 "reserved" 6 "reserved" 7 "reserved" ;
VAL_ 1164 MF_ZV_Unlock 0 "nicht_entriegeln" 1 "entriegeln" ;
VAL_ 1164 MF_Tuerverriegelung_hinten 0 "inaktiv" 1 "aktiv" ;
VAL_ 1164 MF_2BattAb 0 "inaktiv" 1 "aktiv" ;
VAL_ 1164 MF_2BattHlkAnf 0 "inaktiv" 1 "aktiv" ;
VAL_ 1164 MF_2BattLadWarn 0 "inaktiv" 1 "aktiv" ;
VAL_ 1164 MF_2BattLlaAnf 0 "inaktiv" 1 "aktiv" ;
VAL_ 1164 MF_2BattSpannungsAnf 0 "keine_Anforderung" 1 "Anforderung_Stufe1" 2 "Anforderung_Stufe2" 3 "Anforderung_Stufe3" ;
VAL_ 1164 MF_NotStartAktiv 0 "inaktiv" 1 "aktiv" ;
VAL_ 1164 MF_ExterneLadungWarn 0 "inaktiv" 1 "aktiv" ;
VAL_ 1164 MF_LSH_Zielzeit 14 "Init" 15 "Fehler" ;
VAL_ 1164 MF_LSH_Abschaltstufe 0 "Init" 1 "Stufe1" 2 "Stufe2" 3 "Stufe3" 4 "Transportmodus" 7 "Ruhestrommessmodus" ;
VAL_ 1164 MF_LSH_Einschaltverbot 0 "Init_volleVerfuegbarkeit" 1 "Standheizung_bzw_lueftung_nicht_aktivierbar" ;
VAL_ 1471 MFL_Tastencode_1 0 "Key_Released__No_Key" 1 "Context_Menu" 2 "Menu_Up__Next_Screen" 3 "Menu_Down__Previous_Screen" 4 "Up" 5 "Down" 6 "Up__Down_ThumbWheel" 7 "OK__ThumbWheel_Button" 8 "Cancel__Escape" 9 "Main_Menu" 10 "Side_Menu_left" 11 "Side_Menu_right" 12 "FAS_Menu" 13 "Left__Right_ThumbWheel" 14 "FAS_Menu_ThumbWheel" 16 "Volume_Up" 17 "Volume_Down" 18 "Volume_Up__Down_ThumbWheel" 19 "Volume_ThumbWheel_Button" 20 "Audio_Source" 21 "Arrow_A_Up__Right" 22 "Arrow_A_Down__Left" 23 "Arrow_B_Up__Right" 24 "Arrow_B_Down__Left" 25 "PTT__PushToTalk" 26 "PTT_Cancel" 27 "Route_Info" 28 "Hook" 29 "Hang_Up" 30 "Off_Hook" 31 "Light_On__Off" 32 "Mute" 33 "Joker1" 34 "Joker2" 35 "View" 36 "Arrow_A_Up__Down_ThumbWheel" 37 "Lenkradheizung" 38 "Rekuperation" 39 "Tube_Toggle" 40 "DRS_Drag_Reduction_System" 41 "Stopwatch_Start_Stop" 42 "Stopwatch_Nextlap" 100 "MAP" 101 "MAP_Boost" 102 "Turn_signal_left" 103 "Turn_signal_right" 104 "Turn_signal_off" 105 "Flashlight" 106 "Highbeam" 107 "Washer_button" 108 "Wiper_button_left" 109 "Wiper_button_right" 110 "Wiper_button_cancel" 111 "Exhaust_Sound" 112 "Drive_Select_button" 113 "Sport_button" 114 "ESP_Drift_Selection_ThumbWheel" 115 "PTT_special_vehicle" 116 "TravelAssist" 117 "Launch_Control" 118 "Drift_Mode_Button_Increase" 119 "Drift_Mode_Button_Decrease" 120 "Drift_Mode_Button_Select" 121 "Drive_Mode_Button_Increase" 122 "Drive_Mode_Button_Decrease" 123 "Drive_Mode_Button_Select" 124 "E_Boost_Button_Increase" 125 "E_Boost_Button_Decrease" 126 "E_Boost_Button_Select" 127 "PerformanceHybridButton_Increase" 128 "PerformanceHybridButton_Decrease" 129 "EV_Mode_Button" 130 "HUD_Button" 131 "PASM_Wheel" 132 "PASM_Button" 133 "PTV_Wheel" 134 "PTV_Button" 135 "TC_ESC_Wheel" 136 "TC_ESC_Button" 240 "Startup_Reset" 241 "Initialization" ;
VAL_ 1471 MFL_Tastencode_2 0 "Key_Released__No_Key" 1 "Context_Menu" 2 "Menu_Up__Next_Screen" 3 "Menu_Down__Previous_Screen" 4 "Up" 5 "Down" 6 "Up__Down_ThumbWheel" 7 "OK__ThumbWheel_Button" 8 "Cancel__Escape" 9 "Main_Menu" 10 "Side_Menu_left" 11 "Side_Menu_right" 12 "FAS_Menu" 13 "Left__Right_ThumbWheel" 14 "FAS_Menu_ThumbWheel" 16 "Volume_Up" 17 "Volume_Down" 18 "Volume_Up__Down_ThumbWheel" 19 "Volume_ThumbWheel_Button" 20 "Audio_Source" 21 "Arrow_A_Up__Right" 22 "Arrow_A_Down__Left" 23 "Arrow_B_Up__Right" 24 "Arrow_B_Down__Left" 25 "PTT__PushToTalk" 26 "PTT_Cancel" 27 "Route_Info" 28 "Hook" 29 "Hang_Up" 30 "Off_Hook" 31 "Light_On__Off" 32 "Mute" 33 "Joker1" 34 "Joker2" 35 "View" 36 "Arrow_A_Up_Right_Down_Left_ThumbWheel" 37 "Lenkradheizung" 38 "Rekuperation" 39 "Tube_Toggle" 40 "DRS_Drag_Reduction_System" 41 "Stopwatch_Start_Stop" 42 "Stopwatch_Nextlap" 100 "MAP" 101 "MAP_Boost" 102 "Turn_signal_left" 103 "Turn_signal_right" 104 "Turn_signal_off" 105 "Flashlight" 106 "Highbeam" 107 "Washer_button" 108 "Wiper_button_left" 109 "Wiper_button_right" 110 "Wiper_button_cancel" 111 "Exhaust_Sound" 112 "Drive_Select_button" 113 "Sport_button" 114 "ESP_Drift_Selection_ThumbWheel" 115 "PTT_special_vehicle" 116 "TravelAssist" 117 "Launch_Control" 118 "Drift_Mode_Button_Increase" 119 "Drift_Mode_Button_Decrease" 120 "Drift_Mode_Button_Select" 121 "Drive_Mode_Button_Increase" 122 "Drive_Mode_Button_Decrease" 123 "Drive_Mode_Button_Select" 124 "E_Boost_Button_Increase" 125 "E_Boost_Button_Decrease" 126 "E_Boost_Button_Select" 127 "PerformanceHybridButton_Increase" 128 "PerformanceHybridButton_Decrease" 129 "EV_Mode_Button" 130 "HUD_Button" 131 "PASM_Wheel" 132 "PASM_Button" 133 "PTV_Wheel" 134 "PTV_Button" 135 "TC_ESC_Wheel" 136 "TC_ESC_Button" 240 "Startup_Reset" 241 "Initialization" ;
VAL_ 1471 MFL_Eventcode_1 0 "W_no_event____T_no_event" 1 "W_1_Tick_up__T_pressed_normal" 2 "W_2_Ticks_up__T_touched" 3 "W_3_Ticks_up__T_double_click_nor" 4 "W_4_Ticks_up__T_long_press_nor_1" 5 "W_5_Ticks_up__T_long_press_nor_2" 6 "W_6_Ticks_up__T_long_press_nor_3" 7 "W_7_Ticks_up" 9 "W_7_Ticks_dn__T_pressed_strong" 10 "W_6_Ticks_dn" 11 "W_5_Ticks_dn__T_double_click_str" 12 "W_4_Ticks_dn__T_long_press_str_1" 13 "W_3_Ticks_dn__T_long_press_str_2" 14 "W_2_Ticks_dn__T_long_press_str_3" 15 "W_1_Tick_dn" ;
VAL_ 1471 MFL_Eventcode_2 0 "W_no_event____T_no_event" 1 "W_1_Tick_up__T_pressed_normal" 2 "W_2_Ticks_up__T_touched" 3 "W_3_Ticks_up__T_double_click_nor" 4 "W_4_Ticks_up__T_long_press_nor_1" 5 "W_5_Ticks_up__T_long_press_nor_2" 6 "W_6_Ticks_up__T_long_press_nor_3" 7 "W_7_Ticks_up" 9 "W_7_Ticks_dn__T_pressed_strong" 10 "W_6_Ticks_dn" 11 "W_5_Ticks_dn__T_double_click_str" 12 "W_4_Ticks_dn__T_long_press_str_1" 13 "W_3_Ticks_dn__T_long_press_str_2" 14 "W_2_Ticks_dn__T_long_press_str_3" 15 "W_1_Tick_dn" ;
VAL_ 1471 MFL_Marke 0 "VW" 1 "Audi" 2 "Seat" 3 "Skoda" 4 "VW_Nutzf" 5 "Bugatti" 6 "Lamborghini" 7 "Bentley" 8 "Rolls Royce" 9 "Quattro" 10 "kein_Hersteller_1" 11 "kein_Hersteller_2" 12 "kein_Hersteller_3" 13 "kein_Hersteller_4" 14 "Ford" 15 "Porsche" ;
VAL_ 2463978670 SDF2_MIB_Segment_ID 0 "KeineSegmentinformation" 1 "Fehlerwert" ;
VAL_ 2463978670 SDF2_MIB_Fehler_Laengsrichtung 0 "Init" 1 "kleiner_2m" 2 "kleiner_5m" 3 "kleiner_10m" 4 "kleiner_20m" 5 "kleiner_50m" 6 "groesser_50m" 7 "offroad" ;
VAL_ 2463978670 SDF2_MIB_Standort_Eindeutig 0 "mehrdeutiger_Standort" 1 "eindeutiger_Standort" ;
